VERSION ""

NS_ :

BS_:

BU_: OLDC EWP2 iBAU PSB EWP ESC EVP2 Dummy EVP1 SCU AAF eCALL H_U AEB IBOX LCA MCU SPAS CGW OBC TMU EPB SMK BCF MDPS CPD vDCM ACU vBDM AAF_2 CCM AAF_3 CLU ICSC LVR LDC CDM VCMS FCA IBU SCC PLC VCRM TCU EMS TPMS BMS NEMS LDW_LKA AAF_Tester DATC eCall VESS VCU ODS

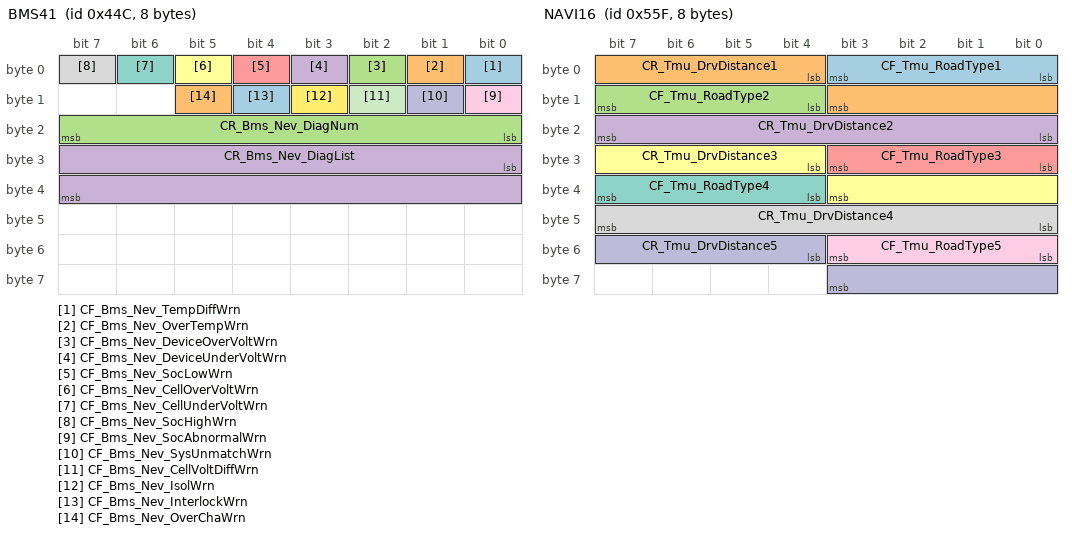
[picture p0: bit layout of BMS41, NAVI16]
BO_ 1100 BMS41: 8 BMS
 SG_ CF_Bms_Nev_TempDiffWrn : 0|1@1+ (1,0) [0|0] ""  CGW,NEMS
 SG_ CF_Bms_Nev_OverTempWrn : 1|1@1+ (1,0) [0|0] ""  CGW,NEMS
 SG_ CF_Bms_Nev_DeviceOverVoltWrn : 2|1@1+ (1,0) [0|0] ""  CGW,NEMS
 SG_ CF_Bms_Nev_DeviceUnderVoltWrn : 3|1@1+ (1,0) [0|0] ""  CGW,NEMS
 SG_ CF_Bms_Nev_SocLowWrn : 4|1@1+ (1,0) [0|0] ""  CGW,NEMS
 SG_ CF_Bms_Nev_CellOverVoltWrn : 5|1@1+ (1,0) [0|0] ""  CGW,NEMS
 SG_ CF_Bms_Nev_CellUnderVoltWrn : 6|1@1+ (1,0) [0|0] ""  CGW,NEMS
 SG_ CF_Bms_Nev_SocHighWrn : 7|1@1+ (1,0) [0|0] ""  CGW,NEMS
 SG_ CF_Bms_Nev_SocAbnormalWrn : 8|1@1+ (1,0) [0|0] ""  CGW,NEMS
 SG_ CF_Bms_Nev_SysUnmatchWrn : 9|1@1+ (1,0) [0|0] ""  CGW,NEMS
 SG_ CF_Bms_Nev_CellVoltDiffWrn : 10|1@1+ (1,0) [0|0] ""  CGW,NEMS
 SG_ CF_Bms_Nev_IsolWrn : 11|1@1+ (1,0) [0|0] ""  CGW,NEMS
 SG_ CF_Bms_Nev_InterlockWrn : 12|1@1+ (1,0) [0|0] ""  CGW,NEMS
 SG_ CF_Bms_Nev_OverChaWrn : 13|1@1+ (1,0) [0|0] ""  CGW,NEMS
 SG_ CR_Bms_Nev_DiagNum : 16|8@1+ (1,0) [0|0] ""  CGW,NEMS
 SG_ CR_Bms_Nev_DiagList : 24|16@1+ (1,0) [0|0] ""  CGW,NEMS

BO_ 1375 NAVI16: 8 CGW
 SG_ CF_Tmu_RoadType1 : 0|4@1+ (1,0) [0|15] ""  VCU
 SG_ CR_Tmu_DrvDistance1 : 4|8@1+ (1,0) [0|255] "km"  VCU
 SG_ CF_Tmu_RoadType2 : 12|4@1+ (1,0) [0|15] ""  VCU
 SG_ CR_Tmu_DrvDistance2 : 16|8@1+ (1,0) [0|255] "km"  VCU
 SG_ CF_Tmu_RoadType3 : 24|4@1+ (1,0) [0|15] ""  VCU
 SG_ CR_Tmu_DrvDistance3 : 28|8@1+ (1,0) [0|255] "km"  VCU
 SG_ CF_Tmu_RoadType4 : 36|4@1+ (1,0) [0|15] ""  VCU
 SG_ CR_Tmu_DrvDistance4 : 40|8@1+ (1,0) [0|255] "km"  VCU
 SG_ CF_Tmu_RoadType5 : 48|4@1+ (1,0) [0|15] ""  VCU
 SG_ CR_Tmu_DrvDistance5 : 52|8@1+ (1,0) [0|255] "km"  VCU

BO_ 820 MCB11: 8 iBAU
 SG_ MCB_CtlSta : 0|1@1+ (1,0) [0|1] ""  ACU,vBDM
 SG_ MCB_DefSta : 1|1@1+ (1,0) [0|1] ""  ACU,vBDM

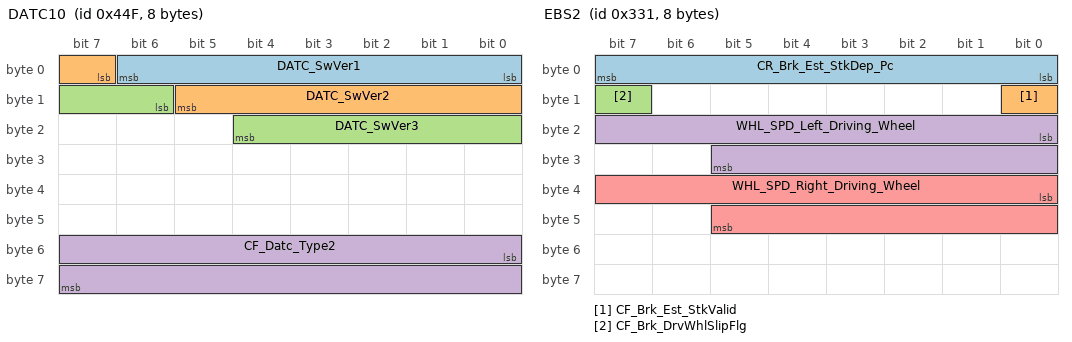
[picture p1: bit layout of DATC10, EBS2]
BO_ 1103 DATC10: 8 DATC
 SG_ DATC_SwVer1 : 0|7@1+ (1,0) [0|127] ""  CGW
 SG_ DATC_SwVer2 : 7|7@1+ (1,0) [0|127] ""  CGW
 SG_ DATC_SwVer3 : 14|7@1+ (1,0) [0|127] ""  CGW
 SG_ CF_Datc_Type2 : 48|16@1+ (1,0) [0|0] ""  CGW

BO_ 817 EBS2: 8 iBAU
 SG_ CR_Brk_Est_StkDep_Pc : 0|8@1+ (0.390625,0) [0|99.609375] "%"  Dummy
 SG_ CF_Brk_Est_StkValid : 8|1@1+ (1,0) [0|1] ""  Dummy
 SG_ CF_Brk_DrvWhlSlipFlg : 15|1@1+ (1,0) [0|1] ""  VCU
 SG_ WHL_SPD_Left_Driving_Wheel : 16|14@1+ (0.03125,0) [0|511.9375] "Km/h"  MCU,VCU
 SG_ WHL_SPD_Right_Driving_Wheel : 32|14@1+ (0.03125,0) [0|511.9375] "Km/h"  MCU,VCU

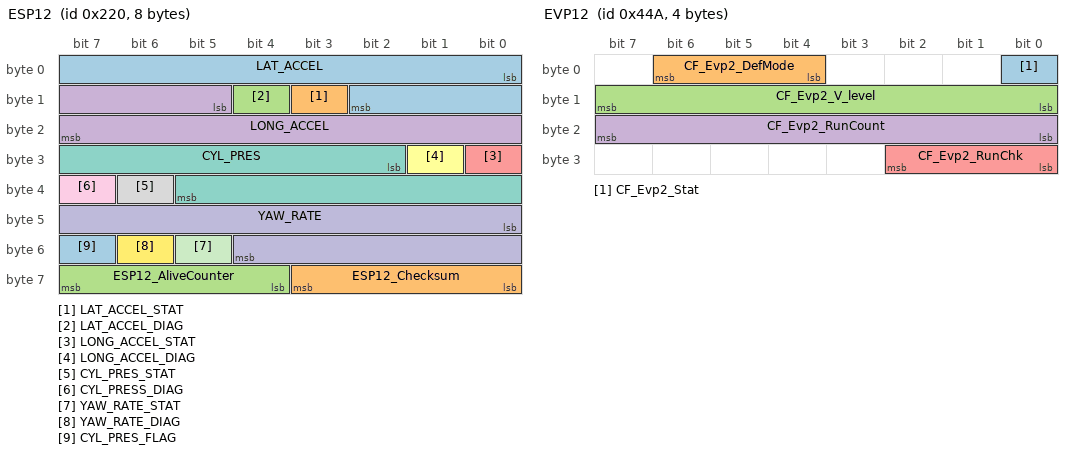
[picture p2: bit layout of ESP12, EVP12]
BO_ 544 ESP12: 8 iBAU
 SG_ LAT_ACCEL : 0|11@1+ (0.01,-10.23) [-10.23|10.24] "m/s^2"  CGW,MCU,VCU,vBDM
 SG_ LAT_ACCEL_STAT : 11|1@1+ (1,0) [0|1] ""  MCU,VCU
 SG_ LAT_ACCEL_DIAG : 12|1@1+ (1,0) [0|1] ""  ACU,MCU,VCU
 SG_ LONG_ACCEL : 13|11@1+ (0.01,-10.23) [-10.23|10.24] "m/s^2"  MCU,VCU
 SG_ LONG_ACCEL_STAT : 24|1@1+ (1,0) [0|1] ""  MCU,VCU
 SG_ LONG_ACCEL_DIAG : 25|1@1+ (1,0) [0|1] ""  ACU,MCU,VCU
 SG_ CYL_PRES : 26|12@1+ (0.1,0) [0|409.5] "Bar"  ACU,Dummy,EVP1,EVP2
 SG_ CYL_PRES_STAT : 38|1@1+ (1,0) [0|1] ""  CGW,Dummy,IBU
 SG_ CYL_PRESS_DIAG : 39|1@1+ (1,0) [0|1] ""  Dummy
 SG_ YAW_RATE : 40|13@1+ (0.01,-40.95) [-40.95|40.96] "¢ª/s"  Dummy
 SG_ YAW_RATE_STAT : 53|1@1+ (1,0) [0|1] ""  Dummy
 SG_ YAW_RATE_DIAG : 54|1@1+ (1,0) [0|1] ""  ACU,Dummy
 SG_ CYL_PRES_FLAG : 55|1@1+ (1,0) [0|1] ""  CGW,IBU
 SG_ ESP12_Checksum : 56|4@1+ (1,0) [0|15] ""  Dummy
 SG_ ESP12_AliveCounter : 60|4@1+ (1,0) [0|15] ""  Dummy,TMU

BO_ 819 VCU30: 8 VCU
 SG_ CR_Vcu_WhlRgnTqMax_Nm : 0|16@1+ (1,0) [0|65535] "Nm"  Dummy,iBAU

BO_ 1098 EVP12: 4 EVP2
 SG_ CF_Evp2_Stat : 0|1@1+ (1,0) [0|1] ""  CGW,EVP1,iBAU
 SG_ CF_Evp2_DefMode : 4|3@1+ (1,0) [0|7] ""  EVP1
 SG_ CF_Evp2_V_level : 8|8@1+ (10,0) [0|760] "mmHg"  EVP1
 SG_ CF_Evp2_RunCount : 16|8@1+ (100,0) [0|255] "ms"  EVP1
 SG_ CF_Evp2_RunChk : 24|3@1+ (1,0) [0|7] ""  EVP1,iBAU

BO_ 1369 CGW4: 8 CGW
 SG_ CF_Gway_MemoryP1Cmd : 0|1@1+ (1,0) [0|1] ""  Dummy
 SG_ CF_Gway_MemoryP2Cmd : 1|1@1+ (1,0) [0|1] ""  Dummy
 SG_ CF_Gway_PBackP1Cmd : 2|1@1+ (1,0) [0|1] ""  Dummy
 SG_ CF_Gway_PBackP2Cmd : 3|1@1+ (1,0) [0|1] ""  Dummy
 SG_ CF_Gway_StrgWhlHeatedState : 4|1@1+ (1,0) [0|1] ""  Dummy
 SG_ CF_Gway_PBackStopCmd : 5|1@1+ (1,0) [0|1] ""  Dummy
 SG_ CF_Gway_StaticBendLhAct : 6|1@1+ (1,0) [0|1] ""  Dummy
 SG_ CF_Gway_StaticBendRhAct : 7|1@1+ (1,0) [0|1] ""  Dummy
 SG_ CF_Gway_DrvWdwStat : 8|1@1+ (1,0) [0|1] ""  Dummy
 SG_ CF_Gway_RLWdwState : 9|1@1+ (1,0) [0|1] ""  Dummy
 SG_ CF_Gway_RRWdwState : 10|1@1+ (1,0) [0|1] ""  Dummy
 SG_ CF_Gway_AstWdwStat : 11|1@1+ (1,0) [0|1] ""  Dummy
 SG_ CF_Gway_MemoryEnable : 12|1@1+ (1,0) [0|1] ""  Dummy
 SG_ CF_Gway_DrvUnlockState : 14|1@1+ (1,0) [0|1] ""  Dummy
 SG_ CF_Gway_IMSBuzzer : 15|1@1+ (1,0) [0|1] ""  Dummy
 SG_ C_HSWSSysStat : 16|2@1+ (1,0) [0|3] ""  Dummy
 SG_ CF_Gway_WiperSwState : 18|2@1+ (1,0) [0|3] ""  Dummy
 SG_ CF_Gway_HCIMSPBackCmd : 20|12@1+ (1,0) [0|4095] ""  Dummy
 SG_ CF_Gway_DrvSeatBeltIND : 36|2@1+ (1,0) [0|3] ""  Dummy
 SG_ CF_Gway_AstSeatBeltIND : 38|2@1+ (1,0) [0|3] ""  Dummy
 SG_ CF_Gway_RCSeatBeltIND : 40|2@1+ (1,0) [0|3] ""  Dummy
 SG_ CF_Gway_RLSeatBeltIND : 42|2@1+ (1,0) [0|3] ""  Dummy
 SG_ CF_Gway_RRSeatBeltIND : 44|2@1+ (1,0) [0|3] ""  Dummy
 SG_ CF_Gway_RrWiperHighSw : 46|1@1+ (1,0) [0|1] ""  Dummy
 SG_ CF_Gway_RrWiperLowSw : 47|1@1+ (1,0) [0|1] ""  Dummy
 SG_ CF_Gway_Navigation_On_Off : 48|2@1+ (1,0) [0|3] ""  Dummy
 SG_ CF_Gway_LanguageInfo : 50|5@1+ (1,0) [0|31] ""  Dummy
 SG_ CF_Gway_Navi_On_Off : 55|1@1+ (1,0) [0|1] ""  Dummy
 SG_ CF_Gway_WPCWarning : 56|3@1+ (1,0) [0|7] ""  Dummy
 SG_ CF_Gway_RWPCWarning : 59|3@1+ (1,0) [0|7] ""  Dummy
 SG_ CF_Gway_DedicatedDRLState : 62|1@1+ (1,0) [0|1] ""  Dummy
 SG_ CF_Gway_SeatBeltWngBuz : 63|1@1+ (1,0) [0|1] ""  Dummy

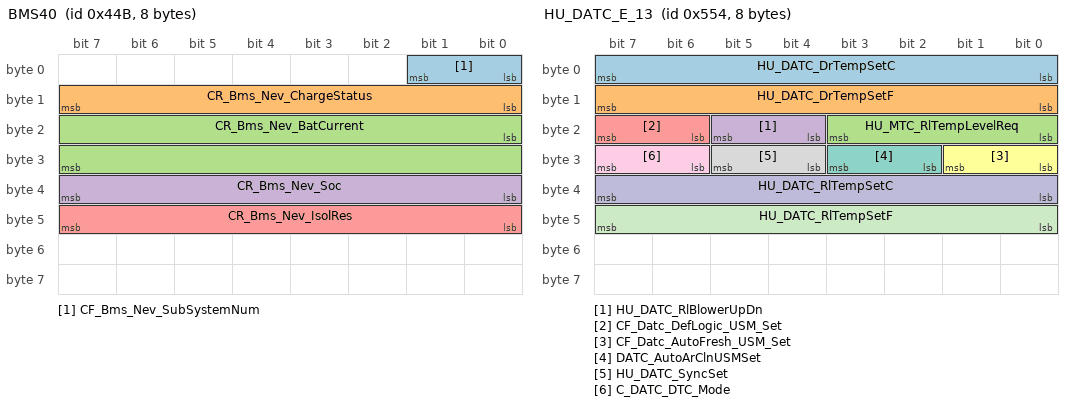
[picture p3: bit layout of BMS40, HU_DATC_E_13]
BO_ 1099 BMS40: 8 BMS
 SG_ CF_Bms_Nev_SubSystemNum : 0|2@1+ (1,0) [0|0] ""  CGW,NEMS
 SG_ CR_Bms_Nev_ChargeStatus : 8|8@1+ (1,0) [0|0] ""  CGW,NEMS
 SG_ CR_Bms_Nev_BatCurrent : 16|16@1- (0.1,0) [0|0] "A"  CGW,NEMS
 SG_ CR_Bms_Nev_Soc : 32|8@1+ (0.5,0) [0|0] "%"  CGW,NEMS
 SG_ CR_Bms_Nev_IsolRes : 40|8@1+ (5,0) [0|0] "k¥Ø"  CGW,NEMS

BO_ 1364 HU_DATC_E_13: 8 CGW
 SG_ HU_DATC_DrTempSetC : 0|8@1+ (0.5,14) [15|32] "¡É"  DATC
 SG_ HU_DATC_DrTempSetF : 8|8@1+ (1,56) [58|90] "¢µ"  DATC
 SG_ HU_MTC_RlTempLevelReq : 16|4@1+ (1,0) [0|0] ""  DATC
 SG_ HU_DATC_RlBlowerUpDn : 20|2@1+ (1,0) [0|0] ""  DATC
 SG_ CF_Datc_DefLogic_USM_Set : 22|2@1+ (1,0) [0|0] ""  DATC
 SG_ CF_Datc_AutoFresh_USM_Set : 24|2@1+ (1,0) [0|0] ""  DATC
 SG_ DATC_AutoArClnUSMSet : 26|2@1+ (1,0) [0|0] ""  DATC
 SG_ HU_DATC_SyncSet : 28|2@1+ (1,0) [0|0] ""  DATC
 SG_ C_DATC_DTC_Mode : 30|2@1+ (1,0) [0|0] ""  DATC
 SG_ HU_DATC_RlTempSetC : 32|8@1+ (0.5,14) [15|32] ""  DATC
 SG_ HU_DATC_RlTempSetF : 40|8@1+ (1,56) [58|90] ""  DATC

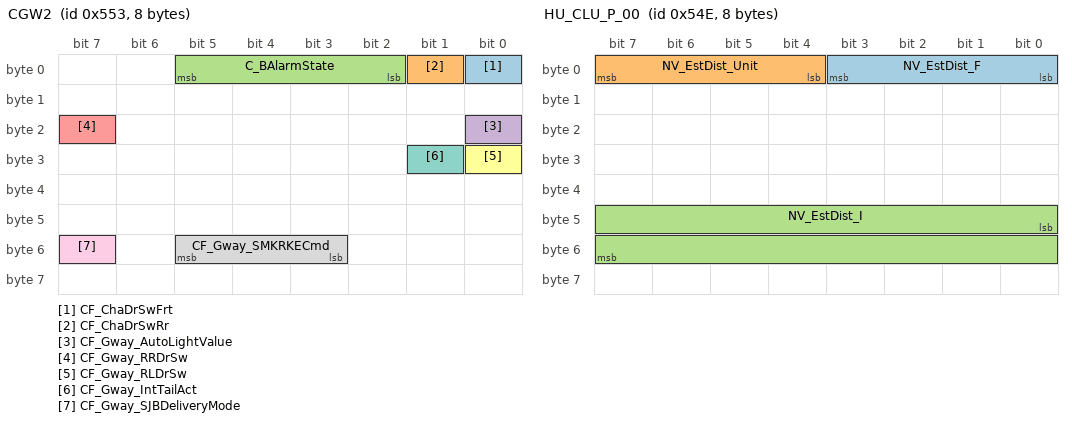
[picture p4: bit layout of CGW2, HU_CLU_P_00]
BO_ 1363 CGW2: 8 CGW
 SG_ CF_ChaDrSwFrt : 0|1@1+ (1,0) [0|0] ""  CDM,VCU
 SG_ CF_ChaDrSwRr : 1|1@1+ (1,0) [0|0] ""  CDM,VCU
 SG_ C_BAlarmState : 2|4@1+ (1,0) [0|0] ""  TMU,VCU
 SG_ CF_Gway_AutoLightValue : 16|1@1+ (1,0) [0|0] ""  DATC
 SG_ CF_Gway_RRDrSw : 23|1@1+ (1,0) [0|1] ""  BMS,vBDM
 SG_ CF_Gway_RLDrSw : 24|1@1+ (1,0) [0|1] ""  BMS
 SG_ CF_Gway_IntTailAct : 25|1@1+ (1,0) [0|1] ""  CLU,LVR,VESS
 SG_ CF_Gway_SMKRKECmd : 51|3@1+ (1,0) [0|7] ""  LVR
 SG_ CF_Gway_SJBDeliveryMode : 55|1@1+ (1,0) [0|1] ""  H_U,LDC,TMU

BO_ 1358 HU_CLU_P_00: 8 CGW
 SG_ NV_EstDist_F : 0|4@1+ (1,0) [0|15] ""  VCU
 SG_ NV_EstDist_Unit : 4|4@1+ (1,0) [0|15] ""  VCU
 SG_ NV_EstDist_I : 40|16@1+ (1,0) [0|65535] ""  VCU

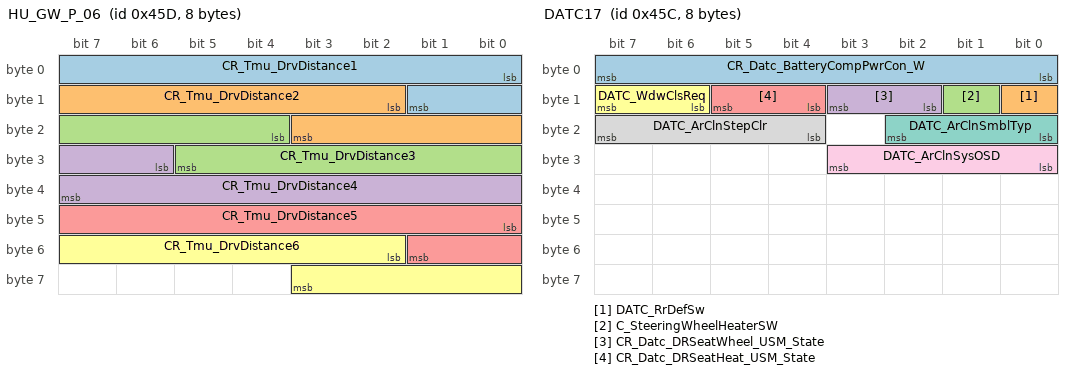
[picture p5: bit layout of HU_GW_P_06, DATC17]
BO_ 1117 HU_GW_P_06: 8 CGW
 SG_ CR_Tmu_DrvDistance1 : 0|10@1+ (1,0) [0|1022] "km"  VCU
 SG_ CR_Tmu_DrvDistance2 : 10|10@1+ (1,0) [0|1022] "km"  VCU
 SG_ CR_Tmu_DrvDistance3 : 20|10@1+ (1,0) [0|1022] "km"  VCU
 SG_ CR_Tmu_DrvDistance4 : 30|10@1+ (1,0) [0|1022] "km"  VCU
 SG_ CR_Tmu_DrvDistance5 : 40|10@1+ (1,0) [0|1022] "km"  VCU
 SG_ CR_Tmu_DrvDistance6 : 50|10@1+ (1,0) [0|1022] "km"  VCU

BO_ 1116 DATC17: 8 DATC
 SG_ CR_Datc_BatteryCompPwrCon_W : 0|8@1+ (40,0) [0|8000] "W"  CGW,TMU,VCU
 SG_ DATC_RrDefSw : 8|1@1+ (1,0) [0|1] ""  CGW
 SG_ C_SteeringWheelHeaterSW : 9|1@1+ (1,0) [0|1] ""  CGW,IBU
 SG_ CR_Datc_DRSeatWheel_USM_State : 10|2@1+ (1,0) [0|3] ""  CGW
 SG_ CR_Datc_DRSeatHeat_USM_State : 12|2@1+ (1,0) [0|3] ""  CGW
 SG_ DATC_WdwClsReq : 14|2@1+ (1,0) [0|3] ""  CGW,IBU
 SG_ DATC_ArClnSmblTyp : 16|3@1+ (1,0) [0|0] ""  CGW
 SG_ DATC_ArClnStepClr : 20|4@1+ (1,0) [0|0] ""  CGW
 SG_ DATC_ArClnSysOSD : 24|4@1+ (1,0) [0|0] ""  CGW

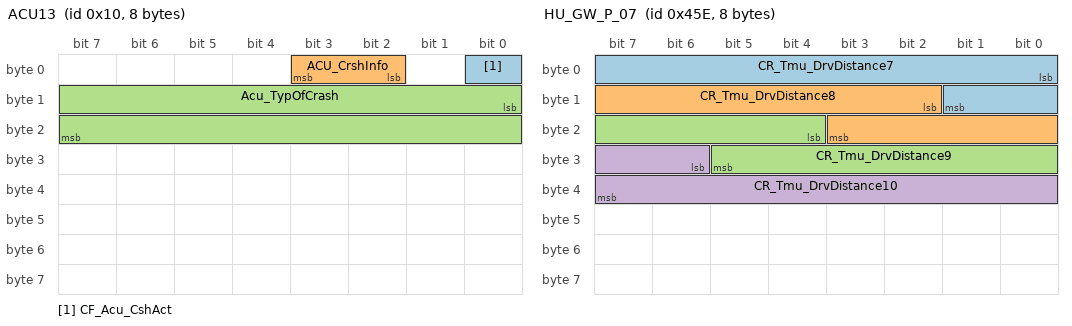
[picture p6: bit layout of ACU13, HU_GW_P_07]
BO_ 16 ACU13: 8 ACU
 SG_ CF_Acu_CshAct : 0|1@1+ (1,0) [0|1] ""  BMS,CGW,DATC,H_U,LDC,MCU,ODS,TMU,eCall
 SG_ ACU_CrshInfo : 2|2@1+ (1,0) [0|2] ""  ESC,iBAU
 SG_ Acu_TypOfCrash : 8|16@1+ (1,0) [0|0] ""  iBAU,vBDM

BO_ 1359 HU_DATC_E_12: 8 CGW
 SG_ HU_DATC_DrTempUpDn : 0|2@1+ (1,0) [0|0] ""  DATC
 SG_ HU_DATC_PsTempUpDn : 2|2@1+ (1,0) [0|0] ""  DATC
 SG_ HU_DATC_RLTempUpDn : 4|2@1+ (1,0) [0|3] ""  DATC
 SG_ HU_DATC_RrTempUpDn : 6|2@1+ (1,0) [0|0] ""  DATC
 SG_ HU_DATC_MainBlower : 8|4@1+ (1,0) [0|0] ""  DATC
 SG_ HU_DATC_RearBlower : 16|4@1+ (1,0) [0|15] ""  DATC
 SG_ HU_DATCRearPsModeSet : 20|4@1+ (1,0) [0|15] ""  DATC
 SG_ HU_DATC_FrontModeSet : 24|4@1+ (1,0) [0|0] ""  DATC
 SG_ HU_DATC_RearModeSet : 28|4@1+ (1,0) [0|15] ""  DATC
 SG_ HU_DATC_AutoSet : 32|2@1+ (1,0) [0|0] ""  DATC
 SG_ HU_DATC_OffReq : 34|2@1+ (1,0) [0|0] ""  DATC
 SG_ HU_DATC_IntakeSet : 36|2@1+ (1,0) [0|0] ""  DATC
 SG_ HU_DATC_RearOnOffSet : 38|2@1+ (1,0) [0|3] ""  DATC
 SG_ HU_DATC_AcSet : 40|2@1+ (1,0) [0|0] ""  DATC
 SG_ HU_DATC_FrontDefog : 44|2@1+ (1,0) [0|0] ""  DATC
 SG_ HU_DATC_RearDefog : 46|2@1+ (1,0) [0|0] ""  DATC
 SG_ HU_DATC_CO2Set : 50|2@1+ (1,0) [0|3] ""  DATC
 SG_ DATC_SmartVentOnOffSet : 52|2@1+ (1,0) [0|3] ""  DATC
 SG_ DATC_ADSOnOffSet : 54|2@1+ (1,0) [0|3] ""  DATC
 SG_ HU_Datc_RearAutoDisp : 56|2@1+ (1,0) [0|3] ""  DATC
 SG_ HU_Datc_RearOffDisp : 58|2@1+ (1,0) [0|3] ""  DATC
 SG_ HU_DATC_MainBlowerUpDn : 60|2@1+ (1,0) [0|0] ""  DATC
 SG_ HU_DATC_AirCleaningSet : 62|2@1+ (1,0) [0|0] ""  DATC

BO_ 1118 HU_GW_P_07: 8 CGW
 SG_ CR_Tmu_DrvDistance7 : 0|10@1+ (1,0) [0|1022] "km"  VCU
 SG_ CR_Tmu_DrvDistance8 : 10|10@1+ (1,0) [0|1022] "km"  VCU
 SG_ CR_Tmu_DrvDistance9 : 20|10@1+ (1,0) [0|1022] "km"  VCU
 SG_ CR_Tmu_DrvDistance10 : 30|10@1+ (1,0) [0|1022] "km"  VCU

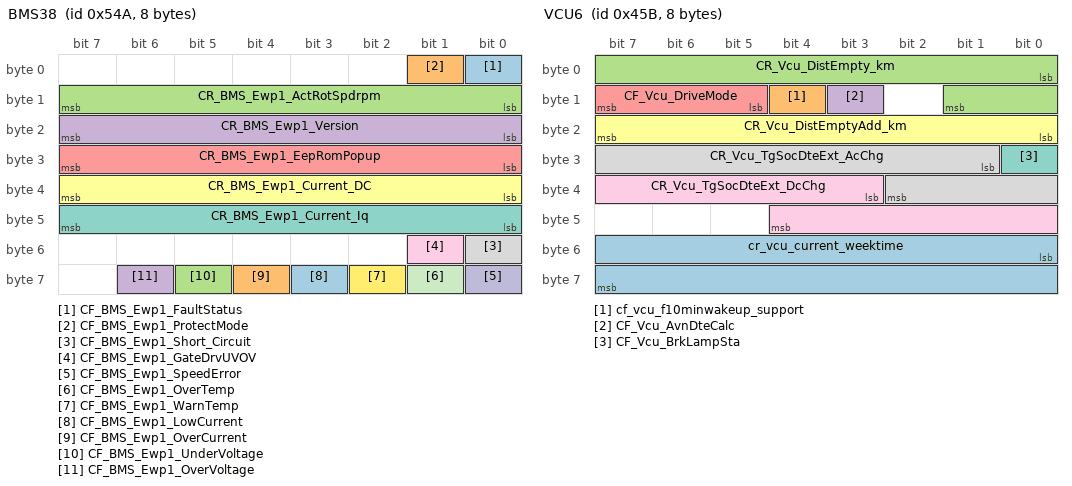
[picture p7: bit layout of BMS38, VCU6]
BO_ 1354 BMS38: 8 BMS
 SG_ CF_BMS_Ewp1_FaultStatus : 0|1@1+ (1,0) [0|1] "flag"  Dummy
 SG_ CF_BMS_Ewp1_ProtectMode : 1|1@1+ (1,0) [0|1] "flag"  Dummy
 SG_ CR_BMS_Ewp1_ActRotSpdrpm : 8|8@1+ (20,0) [0|5000] "rpm"  Dummy
 SG_ CR_BMS_Ewp1_Version : 16|8@1+ (1,0) [0|255] ""  CGW,Dummy,vBDM
 SG_ CR_BMS_Ewp1_EepRomPopup : 24|8@1+ (1,0) [0|255] ""  Dummy
 SG_ CR_BMS_Ewp1_Current_DC : 32|8@1+ (0.1,0) [0|25.5] "A"  Dummy
 SG_ CR_BMS_Ewp1_Current_Iq : 40|8@1+ (0.1,0) [0|25.5] "A"  Dummy
 SG_ CF_BMS_Ewp1_Short_Circuit : 48|1@1+ (1,0) [0|1] ""  Dummy
 SG_ CF_BMS_Ewp1_GateDrvUVOV : 49|1@1+ (1,0) [0|1] "flag"  Dummy
 SG_ CF_BMS_Ewp1_SpeedError : 56|1@1+ (1,0) [0|1] "flag"  Dummy
 SG_ CF_BMS_Ewp1_OverTemp : 57|1@1+ (1,0) [0|1] "flag"  Dummy
 SG_ CF_BMS_Ewp1_WarnTemp : 58|1@1+ (1,0) [0|1] "flag"  Dummy
 SG_ CF_BMS_Ewp1_LowCurrent : 59|1@1+ (1,0) [0|1] "flag"  Dummy
 SG_ CF_BMS_Ewp1_OverCurrent : 60|1@1+ (1,0) [0|1] "flag"  Dummy
 SG_ CF_BMS_Ewp1_UnderVoltage : 61|1@1+ (1,0) [0|1] "flag"  Dummy
 SG_ CF_BMS_Ewp1_OverVoltage : 62|1@1+ (1,0) [0|1] "flag"  Dummy

BO_ 1115 VCU6: 8 VCU
 SG_ cr_vcu_current_weektime : 48|16@1+ (1,0) [0|65535] "" Vector__XXX
 SG_ cf_vcu_f10minwakeup_support : 12|1@1+ (1,0) [0|1] "" Vector__XXX
 SG_ CR_Vcu_DistEmpty_km : 0|10@1+ (1,0) [0|1023] "km"  CGW,H_U,TMU
 SG_ CF_Vcu_AvnDteCalc : 11|1@1+ (1,0) [0|1] "flag"  CGW
 SG_ CF_Vcu_DriveMode : 13|3@1+ (1,0) [0|7] ""  CGW,DATC,MCU,iBAU
 SG_ CR_Vcu_DistEmptyAdd_km : 16|8@1+ (1,0) [0|255] "km"  CGW,TMU
 SG_ CF_Vcu_BrkLampSta : 24|1@1+ (1,0) [0|1] ""  EVP1,EVP2
 SG_ CR_Vcu_TgSocDteExt_AcChg : 25|10@1+ (1,0) [0|1023] ""  CGW
 SG_ CR_Vcu_TgSocDteExt_DcChg : 35|10@1+ (1,0) [0|1023] ""  CGW

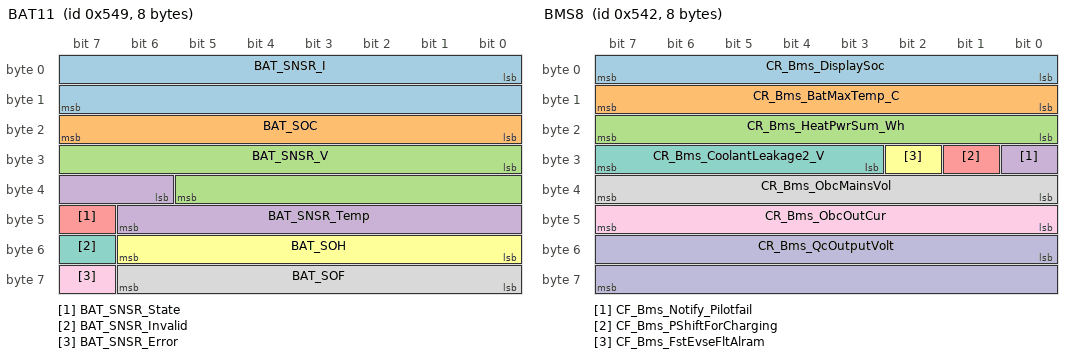
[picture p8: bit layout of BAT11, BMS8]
BO_ 1353 BAT11: 8 LDC
 SG_ BAT_SNSR_I : 0|16@1+ (0.01,-327) [-327|327] "A"  CGW,MCU
 SG_ BAT_SOC : 16|8@1+ (1,0) [0|100] "%"  CGW,H_U,MCU,TMU
 SG_ BAT_SNSR_V : 24|14@1+ (0.001,6) [6|18] "V"  MCU
 SG_ BAT_SNSR_Temp : 38|9@1- (0.5,-40) [-40|87] "¡É"  MCU
 SG_ BAT_SNSR_State : 47|1@1+ (1,0) [0|1] ""  CGW,H_U,MCU,TMU
 SG_ BAT_SOH : 48|7@1+ (1,0) [0|100] "%"  CGW,MCU
 SG_ BAT_SNSR_Invalid : 55|1@1+ (1,0) [0|1] ""  MCU
 SG_ BAT_SOF : 56|7@1+ (0.1,0) [0|12] "V"  MCU
 SG_ BAT_SNSR_Error : 63|1@1+ (1,0) [0|1] ""  MCU

BO_ 265 VCU32: 8 VCU
 SG_ CR_Vcu_EwpRpmReqToMcu : 0|8@1+ (20,0) [0|5000] "rpm"  MCU
 SG_ CF_Vcu_WakeupReq : 8|1@1+ (1,0) [0|1] ""  SCU
 SG_ CF_Vcu_HvIntlock_Req : 9|1@1+ (1,0) [0|1] "flag"  BMS,DATC,OBC,VCU
 SG_ CF_Vcu_BmsEwpOpReq : 10|1@1+ (1,0) [0|1] "flag"  BMS
 SG_ CR_Vcu_TQI_Max : 16|8@1+ (0.3906,0) [0|99.61] "%"  iBAU
 SG_ CR_Vcu_SchedChgSt_Day : 24|3@1+ (1,0) [0|6] ""  CGW
 SG_ CR_Vcu_SchedChgSt_Hr : 27|5@1+ (1,0) [0|23] "Hour"  CGW
 SG_ CR_Vcu_SchedChgSt_Min : 32|6@1+ (1,0) [0|59] "Min"  CGW
 SG_ CR_Vcu_SchedChgEnd_Day : 38|3@1+ (1,0) [0|6] ""  CGW
 SG_ CR_Vcu_SchedChgEnd_Hr : 41|5@1+ (1,0) [0|23] "Hour"  CGW
 SG_ CR_Vcu_SchedChgEnd_Min : 46|6@1+ (1,0) [0|59] "Min"  CGW
 SG_ CF_Vcu_3WayValInhibitToMcu : 52|1@1+ (1,0) [0|1] ""  MCU
 SG_ CF_Vcu_EwpForcedOperToMcu : 53|1@1+ (1,0) [0|1] "flag"  MCU
 SG_ CF_Vcu_EwpCoolantDiagEnbToMcu : 54|1@1+ (1,0) [0|1] "flag"  MCU
 SG_ CF_Vcu_EwpCoolantDispToMcu : 55|1@1+ (1,0) [0|1] "flag"  MCU
 SG_ CF_Vcu_CAN_CHECKSUM : 56|4@1+ (1,0) [0|15] ""  CGW,SCU,TMU,vBDM
 SG_ CF_Vcu_CAN_COUNT : 60|2@1+ (1,0) [0|3] ""  SCU
 SG_ CF_Vcu_PARKCMD : 62|2@1+ (1,0) [0|3] ""  SCU

BO_ 1346 BMS8: 8 BMS
 SG_ CR_Bms_DisplaySoc : 0|8@1+ (0.5,0) [0|100] "%"  CGW,TMU,vBDM
 SG_ CR_Bms_BatMaxTemp_C : 8|8@1- (1,0) [-128|126] "¡É"  Dummy
 SG_ CR_Bms_HeatPwrSum_Wh : 16|8@1+ (10,0) [0|2540] "Wh"  CGW,TMU
 SG_ CF_Bms_Notify_Pilotfail : 24|1@1+ (1,0) [0|1] "flag"  CGW,TMU
 SG_ CF_Bms_PShiftForCharging : 25|1@1+ (1,0) [0|1] "flag"  CGW,TMU
 SG_ CF_Bms_FstEvseFltAlram : 26|1@1+ (1,0) [0|1] "flag"  CGW,TMU
 SG_ CR_Bms_CoolantLeakage2_V : 27|5@1+ (0.2,0) [0|6.3] "V"  Dummy
 SG_ CR_Bms_ObcMainsVol : 32|8@1+ (2,0) [0|500] "V"  VCU
 SG_ CR_Bms_ObcOutCur : 40|8@1+ (0.1,0) [0|25] "A"  VCU
 SG_ CR_Bms_QcOutputVolt : 48|16@1+ (0.1,0) [0|500] "V"  MCU,VCU

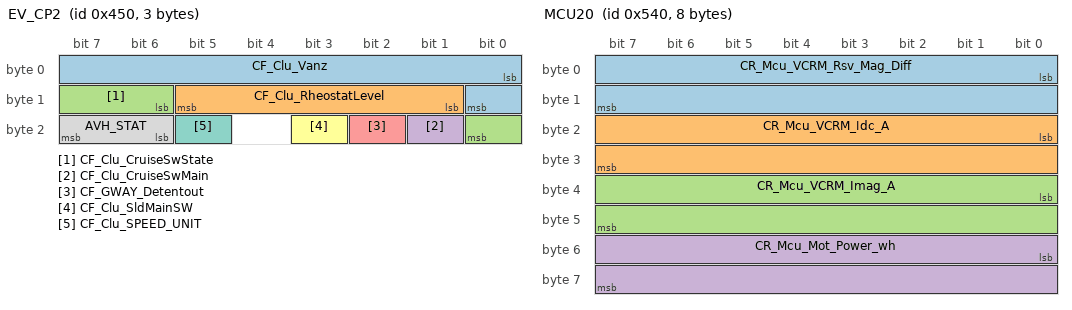
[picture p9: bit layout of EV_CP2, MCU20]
BO_ 1104 EV_CP2: 3 CGW
 SG_ CF_Clu_Vanz : 0|9@1+ (0.5,0) [0|255.5] "km/h or MPH"  DATC,H_U,NEMS,TMU,VCU,VESS,eCall
 SG_ CF_Clu_RheostatLevel : 9|5@1+ (1,0) [0|31] ""  DATC,LCA,LVR,MDPS,SPAS,VESS
 SG_ CF_Clu_CruiseSwState : 14|3@1+ (1,0) [0|7] ""  VCU
 SG_ CF_Clu_CruiseSwMain : 17|1@1+ (1,0) [0|1] ""  VCU
 SG_ CF_GWAY_Detentout : 18|1@1+ (1,0) [0|0] ""  DATC,LVR,VESS
 SG_ CF_Clu_SldMainSW : 19|1@1+ (1,0) [0|1] ""  VCU
 SG_ CF_Clu_SPEED_UNIT : 21|1@1+ (1,0) [0|1] ""  DATC,H_U,NEMS,TMU,VCU,VESS,eCall
 SG_ AVH_STAT : 22|2@1+ (1,0) [0|3] ""  VCU

BO_ 1344 MCU20: 8 MCU
 SG_ CR_Mcu_VCRM_Rsv_Mag_Diff : 0|16@1+ (0.0001,0) [0|6.5535] ""  CGW,TMU,vBDM
 SG_ CR_Mcu_VCRM_Idc_A : 16|16@1+ (0.1,-1000) [-1000|1000] "A"  CGW,NEMS
 SG_ CR_Mcu_VCRM_Imag_A : 32|16@1+ (0.01,0) [0|655.35] "A"  TMU
 SG_ CR_Mcu_Mot_Power_wh : 48|16@1+ (1,0) [0|65534] "Wh"  CGW

BO_ 1345 CGW1: 8 CGW
 SG_ CF_Gway_IGNSw : 0|3@1+ (1,0) [0|7] ""  ACU,H_U,LVR,TMU,VCU,iBAU
 SG_ CF_Gway_RKECmd : 3|3@1+ (1,0) [0|7] ""  LVR
 SG_ CF_Gway_DrvKeyLockSw : 6|1@1+ (1,0) [0|1] ""  Dummy
 SG_ CF_Gway_DrvKeyUnlockSw : 7|1@1+ (1,0) [0|1] ""  Dummy
 SG_ CF_Gway_DrvDrSw : 8|2@1+ (1,0) [0|3] ""  BMS,LVR,VCU,iBAU
 SG_ CF_Gway_DrvSeatBeltSw : 10|2@1+ (1,0) [0|3] ""  ACU,H_U,TMU,VCU,iBAU
 SG_ CF_Gway_TrunkTgSw : 12|2@1+ (1,0) [0|3] ""  BMS,iBAU
 SG_ CF_Gway_AstSeatBeltSw : 14|2@1+ (1,0) [0|3] ""  ACU,H_U,TMU
 SG_ CF_Gway_SMKOption : 16|1@1+ (1,0) [0|1] ""  Dummy
 SG_ CF_Gway_HoodSw : 17|2@1+ (1,0) [0|3] ""  iBAU
 SG_ CF_Gway_TurnSigLh : 19|2@1+ (1,0) [0|3] ""  Dummy
 SG_ CF_Gway_WiperIntT : 21|3@1+ (1,0) [0|7] ""  LDC,iBAU
 SG_ CF_Gway_WiperIntSw : 24|1@1+ (1,0) [0|1] ""  LDC,iBAU
 SG_ CF_Gway_WiperLowSw : 25|1@1+ (1,0) [0|1] ""  LDC,iBAU
 SG_ CF_Gway_WiperHighSw : 26|1@1+ (1,0) [0|1] ""  LDC,iBAU
 SG_ CF_Gway_WiperAutoSw : 27|1@1+ (1,0) [0|1] ""  iBAU
 SG_ CF_Gway_RainSnsState : 28|3@1+ (1,0) [0|7] ""  iBAU
 SG_ CF_Gway_HeadLampLow : 31|1@1+ (1,0) [0|1] ""  LDC
 SG_ CF_Gway_HeadLampHigh : 32|1@1+ (1,0) [0|1] ""  LDC
 SG_ CF_Gway_HazardSw : 33|2@1+ (1,0) [0|3] ""  H_U,TMU,iBAU,vBDM
 SG_ CF_Gway_AstDrSw : 35|1@1+ (1,0) [0|1] ""  BMS
 SG_ CF_Gway_DefoggerRly : 36|1@1+ (1,0) [0|1] ""  LDC
 SG_ CF_Gway_ALightStat : 37|1@1+ (1,0) [0|1] ""  Dummy
 SG_ CF_Gway_LightSwState : 38|2@1+ (1,0) [0|3] ""  LVR
 SG_ CF_Gway_Frt_Fog_Act : 40|1@1+ (1,0) [0|1] ""  Dummy
 SG_ CF_Gway_TSigLHSw : 41|1@1+ (1,0) [0|1] ""  Dummy
 SG_ CF_Gway_TSigRHSw : 42|1@1+ (1,0) [0|1] ""  Dummy
 SG_ CF_Gway_DriveTypeOption : 43|1@1+ (1,0) [0|1] ""  Dummy
 SG_ CF_Gway_StarterRlyState : 44|1@1+ (1,0) [0|1] ""  Dummy
 SG_ CF_Gway_PassiveAccessLock : 45|2@1+ (1,0) [0|3] ""  Dummy
 SG_ CF_Gway_RearFogAct : 47|1@1+ (1,0) [0|1] ""  LDC
 SG_ CF_Gway_PassiveAccessUnlock : 48|2@1+ (1,0) [0|3] ""  Dummy
 SG_ CF_Gway_PassingSW : 51|1@1+ (1,0) [0|1] ""  Dummy
 SG_ CF_Gway_HBAControlMode : 52|1@1+ (1,0) [0|1] ""  Dummy
 SG_ CF_Gway_HLpHighSw : 53|1@1+ (1,0) [0|1] ""  Dummy
 SG_ CF_Gway_InhibitRMT : 54|2@1+ (1,0) [0|3] ""  iBAU
 SG_ CF_Gway_Ign1 : 58|1@1+ (1,0) [0|1] ""  ACU,CDM,Dummy,VCU,iBAU
 SG_ CF_Gway_Ign2 : 59|1@1+ (1,0) [0|1] ""  ACU,Dummy,VCU
 SG_ CF_Gway_ParkBrakeSw : 60|2@1+ (1,0) [0|3] ""  TMU,VCU,iBAU
 SG_ CF_Gway_TurnSigRh : 62|2@1+ (1,0) [0|3] ""  Dummy

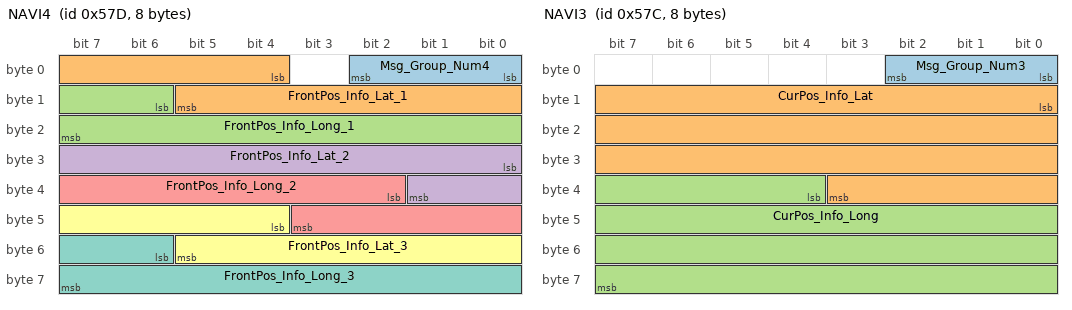
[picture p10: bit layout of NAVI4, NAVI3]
BO_ 1405 NAVI4: 8 CGW
 SG_ Msg_Group_Num4 : 0|3@1+ (1,0) [0|7] ""  VCU
 SG_ FrontPos_Info_Lat_1 : 4|10@1+ (1,-512) [-512|511] "m"  VCU
 SG_ FrontPos_Info_Long_1 : 14|10@1+ (1,-512) [-512|511] "m"  VCU
 SG_ FrontPos_Info_Lat_2 : 24|10@1+ (1,-512) [-512|511] "m"  VCU
 SG_ FrontPos_Info_Long_2 : 34|10@1+ (1,-512) [-512|511] "m"  VCU
 SG_ FrontPos_Info_Lat_3 : 44|10@1+ (1,-512) [-512|511] "m"  VCU
 SG_ FrontPos_Info_Long_3 : 54|10@1+ (1,-512) [-512|511] "m"  VCU

BO_ 1404 NAVI3: 8 CGW
 SG_ Msg_Group_Num3 : 0|3@1+ (1,0) [0|7] ""  VCU
 SG_ CurPos_Info_Lat : 8|28@1+ (1,-134217727) [-134217727|0] "Sec"  VCU
 SG_ CurPos_Info_Long : 36|28@1+ (1,-134217727) [-134217727|0] "Sec"  VCU

BO_ 1407 OBC1: 8 OBC
 SG_ CF_OBC_CONTRAB : 0|1@1+ (1,0) [0|1] ""  BMS,TMU
 SG_ CF_OBC_PD_Stat : 1|2@1+ (1,0) [0|3] ""  BMS,CCM,CGW,H_U,SMK,TMU
 SG_ CF_OBC_Chg_Finished : 3|1@1+ (1,0) [0|1] ""  BMS,CCM,TMU
 SG_ CF_OBC_EVSE_RDY_STATE : 4|1@1+ (1,0) [0|1] ""  BMS,CDM,CGW,H_U,TMU,VCU
 SG_ CF_OBC_WRN : 5|1@1+ (1,0) [0|1] ""  BMS,TMU
 SG_ CF_OBC_FLT : 6|1@1+ (1,0) [0|1] ""  BMS,CGW,H_U,TMU,VCU
 SG_ CF_OBC_RDY : 7|1@1+ (1,0) [0|1] ""  BMS,CGW,TMU,VCU
 SG_ CF_OBC_AC_DETECT_FLAG : 8|1@1+ (1,0) [0|1] ""  BMS,CDM,DATC,TMU
 SG_ CR_OBC_CP_Volt : 9|7@1+ (0.1,0) [0|12.7] "V"  BMS,TMU,VCU
 SG_ CR_OBC_TEMP : 16|8@1+ (1,-100) [-100|155] "¡É"  AAF,MCU,TMU,VCU
 SG_ CR_OBC_RadFanReq_Duty : 24|8@1+ (1,0) [0|255] "%"  MCU,TMU,VCU
 SG_ CF_OBC_IG3_DRV_STATE : 32|1@1+ (1,0) [0|1] ""  BMS,CDM,TMU,VCU
 SG_ CF_OBC_AC_CONNECT : 33|1@1+ (1,0) [0|1] ""  BMS,CCM,CDM,CGW,IBU,SMK,TMU,VCU
 SG_ CF_OBC_S2_SW_ON_FLAG : 34|1@1+ (1,0) [0|1] ""  BMS,CCM,TMU
 SG_ CF_OBC_MainRlyOn_Req : 35|1@1+ (1,0) [0|1] ""  BMS,TMU
 SG_ CF_OBC_OBCRlyOn_Req : 36|1@1+ (1,0) [0|1] ""  BMS,TMU
 SG_ CF_OBC_MILReq : 37|1@1+ (1,0) [0|1] ""  CGW,H_U,TMU,VCU
 SG_ CF_OBC_VCRM_Req : 38|2@1+ (1,0) [0|2] ""  CGW,H_U,TMU,vBDM
 SG_ CF_OBC_RAD_Fan_Req : 40|2@1+ (1,0) [0|2] ""  MCU,TMU,VCU
 SG_ CF_OBC_SERVICE_LAMP_Req : 42|1@1+ (1,0) [0|1] ""  CGW,H_U,TMU
 SG_ CF_OBC_HvIntlockReq : 43|1@1+ (1,0) [0|1] ""  BMS,DATC,LDC,MCU,TMU
 SG_ CF_EVSE_FAULT_FLAG : 44|1@1+ (1,0) [0|1] ""  CCM,CGW,TMU
 SG_ CF_OBC_DCChargingStat : 45|1@1+ (1,0) [0|1] ""  BMS,CCM,CDM,CGW,H_U,TMU
 SG_ CF_OBC_ACChargingStat : 46|1@1+ (1,0) [0|1] ""  CDM,CGW,H_U,TMU,VCU
 SG_ CF_OBC_ImmeChgSwState : 47|1@1+ (1,0) [0|1] ""  VCU
 SG_ CR_OBC_EWP_Rpm_Req : 48|8@1+ (20,0) [0|5000] "rpm"  MCU,TMU,VCU
 SG_ CR_OBC_TEMP_B : 56|8@1+ (1,-100) [-100|155] "¡É"  AAF,MCU,TMU,VCU

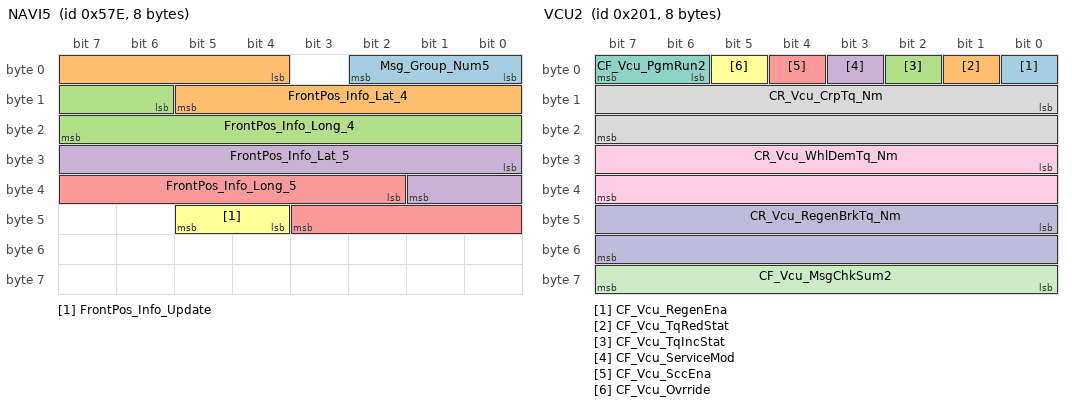
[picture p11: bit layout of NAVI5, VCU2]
BO_ 1406 NAVI5: 8 CGW
 SG_ Msg_Group_Num5 : 0|3@1+ (1,0) [0|7] ""  VCU
 SG_ FrontPos_Info_Lat_4 : 4|10@1+ (1,-512) [-512|511] "m"  VCU
 SG_ FrontPos_Info_Long_4 : 14|10@1+ (1,-512) [-512|511] "m"  VCU
 SG_ FrontPos_Info_Lat_5 : 24|10@1+ (1,-512) [-512|511] "m"  VCU
 SG_ FrontPos_Info_Long_5 : 34|10@1+ (1,-512) [-512|511] "m"  VCU
 SG_ FrontPos_Info_Update : 44|2@1+ (1,0) [0|3] ""  VCU

BO_ 1133 CTM1: 8 CGW
 SG_ CF_Ctm_TrailerAct : 0|1@1+ (1,0) [0|0] ""  Dummy,VCU
 SG_ CF_Ctm_RearfogAct : 1|1@1+ (1,0) [0|0] ""  Dummy

BO_ 1401 VCU18: 8 VCU
 SG_ CF_Vcu_SchedChgMode : 0|2@1+ (1,0) [0|3] ""  CGW,OBC,TMU,vBDM
 SG_ CR_Vcu_OffPeakTimeStHr : 2|5@1+ (1,0) [0|23] "Hour"  CGW,TMU
 SG_ CR_Vcu_OffPeakTimeStMin : 7|3@1+ (10,0) [0|50] "Min"  CGW,TMU
 SG_ CR_Vcu_OffPeakTimeEndHr : 10|5@1+ (1,0) [0|23] "Hour"  CGW,TMU
 SG_ CR_Vcu_OffPeakTimeEndMin : 15|3@1+ (10,0) [0|50] "Min"  CGW,TMU
 SG_ CF_Vcu_RestModeRValueSet : 18|2@1+ (1,0) [0|3] ""  CGW
 SG_ CF_Vcu_RestModeWarn : 20|2@1+ (1,0) [0|2] ""  CGW
 SG_ CF_Vcu_RestModeVehCond : 22|1@1+ (1,0) [0|1] ""  CGW
 SG_ CF_Vcu_EpbRequest : 23|1@1+ (1,0) [0|1] ""  CGW
 SG_ CF_Vcu_GpsSched_State : 24|2@1+ (1,0) [0|3] ""  CGW
 SG_ CF_Vcu_GpsSched_ChgAir : 26|1@1+ (1,0) [0|1] ""  CGW
 SG_ CF_Vcu_GpsSchedUpdateRq : 27|1@1+ (1,0) [0|1] ""  CGW
 SG_ CF_Vcu_MainBattType : 29|2@1+ (1,0) [0|1] ""  Dummy
 SG_ CF_Vcu_MainBattTypeLrnSts : 31|1@1+ (1,0) [0|1] ""  Dummy
 SG_ CF_Vcu_RegenLevel_Eco : 34|2@1+ (1,0) [0|3] "Level"  CGW,TMU
 SG_ CF_Vcu_RegenLevel_Normal : 36|2@1+ (1,0) [0|3] "Level"  CGW,TMU
 SG_ CF_Vcu_RegenLevel_Sport : 38|2@1+ (1,0) [0|3] "Level"  CGW,TMU
 SG_ CF_Vcu_SmartRegen_RValueSet : 40|2@1+ (1,0) [0|3] ""  CGW
 SG_ CF_Vcu_SmartRegen_Disp : 42|1@1+ (1,0) [0|1] ""  CGW
 SG_ CF_Vcu_SmartRegen_Step : 43|1@1+ (1,0) [0|1] ""  CGW
 SG_ CF_Vcu_SmartRegen_WarnMsg : 48|2@1+ (1,0) [0|3] ""  CGW
 SG_ CF_Vcu_DriveMode : 52|3@1+ (1,0) [0|7] ""  BMS,CGW,DATC,LDC,MCU
 SG_ CF_Vcu_SpdLmt : 55|1@1+ (1,0) [0|1] ""  CGW,TMU
 SG_ CR_Vcu_MaxSpd : 56|8@1+ (1,0) [0|255] "kph"  CGW,TMU

BO_ 512 VCU1: 8 VCU
 SG_ CR_Vcu_DistEmptyAdd_km : 0|8@1+ (1,0) [0|255] "km"  CGW,TMU
 SG_ CF_Vcu_ChgStat : 8|3@1+ (1,0) [0|7] ""  TMU,VESS
 SG_ CF_Vcu_GarSelDisp : 11|4@1+ (1,0) [0|15] ""  AAF,ACU,BMS,CGW,H_U,IBU,LDC,LVR,MCU,NEMS,OBC,SMK,TMU,VESS,iBAU
 SG_ CR_Vcu_DistEmpty_km : 15|10@1+ (1,0) [0|1023] "km"  CGW,H_U,TMU
 SG_ CF_Vcu_ChargeCycle : 25|1@1+ (1,0) [0|1] ""  BMS,LDC,MCU,OBC,TMU
 SG_ CF_Vcu_IGONStatus : 26|4@1+ (1,0) [0|10] ""  Dummy
 SG_ CF_Vcu_AvnDteCalc : 30|1@1+ (1,0) [0|1] "flag"  CGW
 SG_ CF_Vcu_EstApsSel : 31|1@1+ (1,0) [0|1] ""  CGW,TMU,iBAU
 SG_ CR_Vcu_AccPedDep_Pc : 32|8@1+ (0.3921568627,0) [0|100] "%"  AAF,ACU,CGW,LDC,MCU,NEMS,TMU,iBAU
 SG_ CF_Vcu_Veh_DC : 40|1@1+ (1,0) [0|1] ""  BMS,DATC,LDC,MCU,OBC,TMU
 SG_ CF_Vcu_WarmupCyc : 41|1@1+ (1,0) [0|1] ""  BMS,LDC,MCU,OBC,TMU
 SG_ CF_Vcu_Key_ST : 42|1@1+ (1,0) [0|1] ""  BMS,CGW,LDC,TMU
 SG_ CF_Vcu_EvRdyClu : 43|1@1+ (1,0) [0|1] ""  CDM,CGW,DATC,IBU,SMK,TMU
 SG_ CF_Vcu_Rdy : 44|1@1+ (1,0) [0|1] ""  BMS,CGW,LDC,LVR,MCU,OBC,TMU,eCall,iBAU,vBDM
 SG_ CF_Vcu_EvRdy : 45|1@1+ (1,0) [0|1] ""  BMS,CCM,CDM,CGW,DATC,EVP1,EVP2,H_U,IBU,LDC,LVR,MCU,OBC,SMK,TMU,VESS,iBAU
 SG_ CF_Vcu_PgmRun1 : 46|2@1+ (1,0) [0|3] ""  TMU,iBAU
 SG_ CF_Vcu_RelayOffReq : 48|1@1+ (1,0) [0|1] ""  BMS,CGW,TMU
 SG_ CR_Vcu_TqStd_Nm : 49|6@1+ (10,0) [0|630] "Nm"  CGW,MCU,TMU,iBAU
 SG_ CF_Vcu_EcoMdOff : 55|1@1+ (1,0) [0|1] ""  CGW,DATC,MCU,TMU,VESS,iBAU
 SG_ CR_Vcu_EstAccPed_PC : 56|8@1+ (0.3906,0) [0|99.61] "%"  CGW,TMU,iBAU

BO_ 513 VCU2: 8 VCU
 SG_ CF_Vcu_RegenEna : 0|1@1+ (1,0) [0|1] ""  TMU,iBAU
 SG_ CF_Vcu_TqRedStat : 1|1@1+ (1,0) [0|1] ""  TMU,iBAU
 SG_ CF_Vcu_TqIncStat : 2|1@1+ (1,0) [0|1] ""  TMU,iBAU
 SG_ CF_Vcu_ServiceMod : 3|1@1+ (1,0) [0|1] ""  CGW,MCU,TMU,iBAU
 SG_ CF_Vcu_SccEna : 4|1@1+ (1,0) [0|1] ""  CGW,TMU,iBAU
 SG_ CF_Vcu_Ovrride : 5|1@1+ (1,0) [0|1] ""  CGW,TMU,iBAU
 SG_ CF_Vcu_PgmRun2 : 6|2@1+ (1,0) [0|3] ""  TMU,iBAU
 SG_ CR_Vcu_CrpTq_Nm : 8|16@1- (1,0) [-32768|32767] "Nm"  TMU,iBAU
 SG_ CR_Vcu_WhlDemTq_Nm : 24|16@1- (1,0) [-32768|32767] "Nm"  CGW,TMU,iBAU
 SG_ CR_Vcu_RegenBrkTq_Nm : 40|16@1+ (1,0) [0|65535] "Nm"  TMU,iBAU
 SG_ CF_Vcu_MsgChkSum2 : 56|8@1+ (1,0) [0|255] ""  CGW,TMU,iBAU,vBDM

BO_ 1400 EV_CP5: 6 CGW
 SG_ CF_Clu_LowfuelWarn : 0|2@1+ (1,0) [0|3] ""  Dummy
 SG_ CF_Ahb_Def : 2|2@1+ (1,0) [0|3] ""  NEMS,TMU,VCU
 SG_ CF_LKA_SysState : 4|4@1+ (1,0) [0|15] ""  H_U,TMU,vBDM
 SG_ CF_Mdps_WLmp : 8|2@1+ (1,0) [0|3] ""  H_U,TMU
 SG_ SCCFailInfo : 11|2@1+ (1,0) [0|3] ""  H_U,TMU
 SG_ SCCMode : 13|2@1+ (1,0) [0|3] ""  H_U,TMU
 SG_ CF_Clu_ActiveEcoSW : 15|1@1+ (1,0) [0|1] ""  TMU,VCU
 SG_ POS_FL_W_LAMP : 16|1@1+ (1,0) [0|1] ""  H_U,TMU
 SG_ POS_FR_W_LAMP : 17|1@1+ (1,0) [0|1] ""  H_U,TMU
 SG_ POS_RL_W_LAMP : 18|1@1+ (1,0) [0|1] ""  H_U,TMU
 SG_ POS_RR_W_LAMP : 19|1@1+ (1,0) [0|1] ""  H_U,TMU
 SG_ TPMS_W_LAMP : 20|2@1+ (1,0) [0|3] ""  H_U,TMU
 SG_ TREAD_W_LAMP : 22|2@1+ (1,0) [0|3] ""  H_U,TMU
 SG_ CF_Clu_SmartRegen_NValueSet : 24|2@1+ (1,0) [0|3] ""  VCU
 SG_ CF_Clu_NCC_CameraNValueSet : 26|3@1+ (1,0) [0|7] ""  VCU
 SG_ CF_DAW_Warn : 30|2@1+ (1,0) [0|3] ""  H_U,TMU
 SG_ CF_Clu_DAWLastBreakTime : 32|4@1+ (1,0) [0|15] ""  H_U,TMU
 SG_ CF_Clu_RefDetMod : 42|1@1+ (1,0) [0|1] ""  VCU
 SG_ CF_Clu_DriveModeSW : 47|1@1+ (1,0) [0|1] ""  TMU,VCU

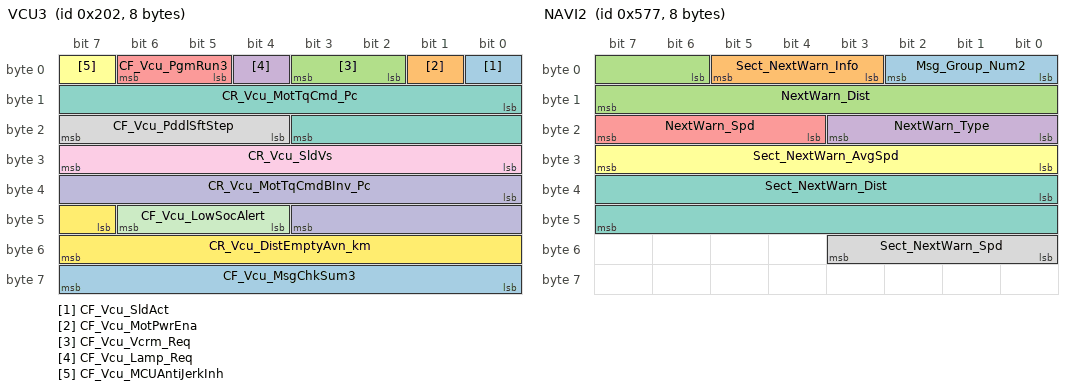
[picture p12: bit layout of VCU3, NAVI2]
BO_ 514 VCU3: 8 VCU
 SG_ CF_Vcu_SldAct : 0|1@1+ (1,0) [0|1] ""  CGW,TMU
 SG_ CF_Vcu_MotPwrEna : 1|1@1+ (1,0) [0|1] ""  CGW,MCU,TMU
 SG_ CF_Vcu_Vcrm_Req : 2|2@1+ (1,0) [0|3] ""  CGW,H_U,TMU,vBDM
 SG_ CF_Vcu_Lamp_Req : 4|1@1+ (1,0) [0|1] ""  CGW,H_U,TMU
 SG_ CF_Vcu_PgmRun3 : 5|2@1+ (1,0) [0|3] ""  MCU,TMU
 SG_ CF_Vcu_MCUAntiJerkInh : 7|1@1+ (1,0) [0|1] ""  MCU,TMU
 SG_ CR_Vcu_MotTqCmd_Pc : 8|12@1- (0.048828125,0) [-100|99.95] "%"  CGW,MCU,TMU,iBAU
 SG_ CF_Vcu_PddlSftStep : 20|4@1+ (1,0) [0|15] ""  CGW,TMU
 SG_ CR_Vcu_SldVs : 24|8@1+ (1,0) [0|255] "km/h"  CGW,TMU
 SG_ CR_Vcu_MotTqCmdBInv_Pc : 32|12@1- (0.048828125,0) [-100|99.95] "%"  TMU,iBAU
 SG_ CF_Vcu_LowSocAlert : 44|3@1+ (1,0) [0|7] ""  CGW
 SG_ CR_Vcu_DistEmptyAvn_km : 47|9@1+ (2,0) [0|1022] "km"  CGW
 SG_ CF_Vcu_MsgChkSum3 : 56|8@1+ (1,0) [0|255] ""  MCU,TMU,iBAU

BO_ 1403 VCU10: 8 VCU
 SG_ CF_Vcu_CharInh : 0|1@1+ (1,0) [0|1] ""  OBC
 SG_ CF_Vcu_CharStopOpt : 1|2@1+ (1,0) [0|3] ""  BMS
 SG_ CF_Vcu_CharStopData : 3|6@1+ (1,40) [40|100] ""  BMS
 SG_ CF_Vcu_ClimateOperPerm : 9|1@1+ (1,0) [0|1] ""  BMS,CGW,DATC,TMU
 SG_ CF_Vcu_Aircon_Finish : 10|1@1+ (1,0) [0|1] ""  CGW,H_U,TMU
 SG_ CF_Vcu_AVN_Wakeup : 11|1@1+ (1,0) [0|1] ""  CGW,DATC,TMU
 SG_ CF_Vcu_IG3RlyMd : 12|4@1+ (1,0) [0|15] ""  BMS,CGW,DATC,H_U,LDC,OBC,TMU
 SG_ CF_Vcu_FailComfirmed : 16|1@1+ (1,0) [0|1] ""  BMS,CGW,DATC,H_U,OBC,TMU
 SG_ CF_Vcu_NoramlAriconCtr : 17|2@1+ (1,0) [0|3] ""  BMS,CGW,DATC,H_U,OBC,TMU
 SG_ CF_Vcu_ProgCharInfo : 19|1@1+ (1,0) [0|1] ""  BMS,CGW
 SG_ CF_Vuc_ProgCharWaitForCharInd : 20|1@1+ (1,0) [0|1] ""  BMS
 SG_ CF_Vcu_CharCancel : 21|1@1+ (1,0) [0|1] ""  BMS
 SG_ CF_Vcu_AirconCtr : 22|1@1+ (1,0) [0|1] ""  BMS,CGW,DATC
 SG_ CF_Vcu_TempUnit4FATC : 23|1@1+ (1,0) [0|1] ""  DATC
 SG_ CR_Vcu_TempSet4FATC : 24|6@1+ (0.5,15) [15|32] "Deg"  DATC
 SG_ CF_Vcu_MainRelayOnReq : 30|1@1+ (1,0) [0|1] ""  BMS
 SG_ CF_Vcu_IG3Only : 31|1@1+ (1,0) [0|1] ""  BMS,CGW,H_U,LDC,MCU,TMU
 SG_ CF_Vcu_ProgCharStop : 32|1@1+ (1,0) [0|1] ""  BMS
 SG_ CF_Vcu_ProgAirConInfo : 33|1@1+ (1,0) [0|1] ""  BMS,CGW,DATC
 SG_ CF_Vcu_SbwWarnMsg : 34|3@1+ (1,0) [0|7] "flag"  CGW
 SG_ CF_Vcu_SbwWarnSnd : 37|1@1+ (1,0) [0|1] "flag"  CGW
 SG_ CF_Vcu_Invalid : 39|1@1+ (1,0) [0|1] ""  CGW
 SG_ CR_Vcu_EcoPotential_Sport : 40|8@1+ (0.5,0) [0|100] "%"  CGW,TMU
 SG_ CR_Vcu_EcoPotential_Normal : 48|8@1+ (0.5,0) [0|100] "%"  CGW,TMU
 SG_ CR_Vcu_EcoPotential_Eco : 56|8@1+ (0.5,0) [0|100] "%"  CGW,TMU

BO_ 1402 VCU9: 8 VCU
 SG_ CR_Vcu_DepartSet1_Hour : 0|5@1+ (1,0) [0|23] "Hour"  CGW,TMU
 SG_ CR_Vcu_DepartSet1_Min : 5|3@1+ (10,0) [0|50] "Min"  CGW,TMU
 SG_ CF_Vcu_DepartSet1_Mon : 8|1@1+ (1,0) [0|1] ""  CGW,TMU
 SG_ CF_Vcu_DepartSet1_Tue : 9|1@1+ (1,0) [0|1] ""  CGW,TMU
 SG_ CF_Vcu_DepartSet1_Wed : 10|1@1+ (1,0) [0|1] ""  CGW,TMU
 SG_ CF_Vcu_DepartSet1_Thu : 11|1@1+ (1,0) [0|1] ""  CGW,TMU
 SG_ CF_Vcu_DepartSet1_Fri : 12|1@1+ (1,0) [0|1] ""  CGW,TMU
 SG_ CF_Vcu_DepartSet1_Sat : 13|1@1+ (1,0) [0|1] ""  CGW,TMU
 SG_ CF_Vcu_DepartSet1_Sun : 14|1@1+ (1,0) [0|1] ""  CGW,TMU
 SG_ CF_Vcu_DepartSet1_PreCondSet : 15|1@1+ (1,0) [0|1] ""  CGW,DATC,TMU
 SG_ CR_Vcu_DepartSet1_TempSet : 16|6@1+ (0.5,15) [15|32] "¡É"  CGW,TMU
 SG_ CF_Vcu_DepartSet1_TempUnit : 22|1@1+ (1,0) [0|1] ""  CGW,TMU
 SG_ CF_Vcu_DepartSet1_DefrostCtr : 23|1@1+ (1,0) [0|1] ""  CGW,TMU
 SG_ CF_Vcu_DepartSet1_Enable : 24|1@1+ (1,0) [0|1] ""  CGW,TMU
 SG_ CR_Vcu_DepartSet2_Hour : 25|5@1+ (1,0) [0|23] "Hour"  CGW,TMU
 SG_ CR_Vcu_DepartSet2_Min : 30|3@1+ (10,0) [0|50] "Min"  CGW,TMU
 SG_ CF_Vcu_DepartSet2_Mon : 33|1@1+ (1,0) [0|1] ""  CGW,TMU
 SG_ CF_Vcu_DepartSet2_Tue : 34|1@1+ (1,0) [0|1] ""  CGW,TMU
 SG_ CF_Vcu_DepartSet2_Wed : 35|1@1+ (1,0) [0|1] ""  CGW,TMU
 SG_ CF_Vcu_DepartSet2_Thu : 36|1@1+ (1,0) [0|1] ""  CGW,TMU
 SG_ CF_Vcu_DepartSet2_Fri : 37|1@1+ (1,0) [0|1] ""  CGW,TMU
 SG_ CF_Vcu_DepartSet2_Sat : 38|1@1+ (1,0) [0|1] ""  CGW,TMU
 SG_ CF_Vcu_DepartSet2_Sun : 39|1@1+ (1,0) [0|1] ""  CGW,TMU
 SG_ CF_Vcu_DepartSet2_PreCondSet : 40|1@1+ (1,0) [0|1] ""  CGW,DATC,TMU
 SG_ CR_Vcu_DepartSet2_TempSet : 41|6@1+ (0.5,15) [15|32] "¡É"  CGW,TMU
 SG_ CF_Vcu_DepartSet2_TempUnit : 47|1@1+ (1,0) [0|1] ""  CGW,TMU
 SG_ CF_Vcu_DepartSet2_DefrostCtr : 48|1@1+ (1,0) [0|1] ""  CGW,TMU
 SG_ CF_Vcu_DepartSet2_Enable : 49|1@1+ (1,0) [0|1] ""  CGW,TMU
 SG_ CF_VCU_IG3DrvSts : 50|1@1+ (1,0) [0|1] ""  LDC
 SG_ CF_VCU_AuxBattChgUsmSts : 62|2@1+ (1,0) [0|3] ""  CGW,LDC

BO_ 1399 NAVI2: 8 CGW
 SG_ Msg_Group_Num2 : 0|3@1+ (1,0) [0|7] ""  VCU
 SG_ Sect_NextWarn_Info : 3|3@1+ (1,0) [0|7] ""  VCU
 SG_ NextWarn_Dist : 6|10@1+ (1,0) [0|1023] "m"  VCU
 SG_ NextWarn_Type : 16|4@1+ (1,0) [0|15] ""  VCU
 SG_ NextWarn_Spd : 20|4@1+ (10,0) [0|150] "Km/h"  VCU
 SG_ Sect_NextWarn_AvgSpd : 24|8@1+ (1,0) [0|255] "Km/h"  VCU
 SG_ Sect_NextWarn_Dist : 32|16@1+ (1,0) [0|65535] "m"  VCU
 SG_ Sect_NextWarn_Spd : 48|4@1+ (10,0) [0|150] "Km/h"  VCU

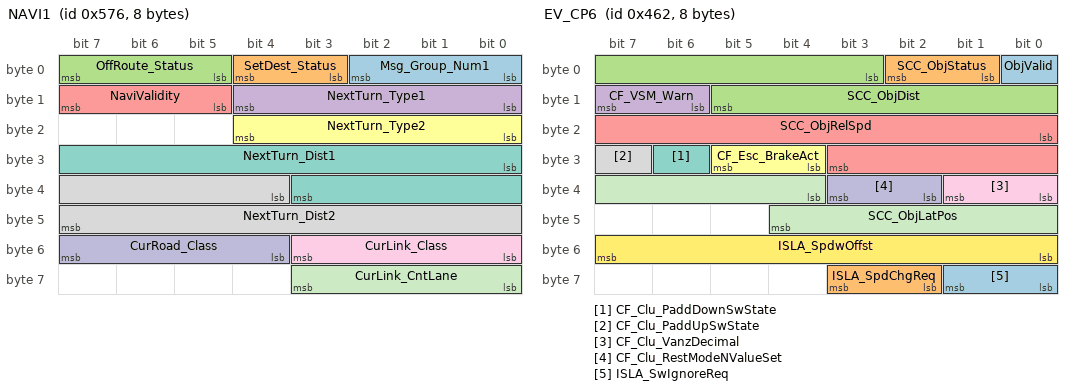
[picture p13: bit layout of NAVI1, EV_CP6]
BO_ 1398 NAVI1: 8 CGW
 SG_ Msg_Group_Num1 : 0|3@1+ (1,0) [0|7] ""  VCU
 SG_ SetDest_Status : 3|2@1+ (1,0) [0|3] ""  VCU
 SG_ OffRoute_Status : 5|3@1+ (1,0) [0|7] ""  VCU
 SG_ NextTurn_Type1 : 8|5@1+ (1,0) [0|31] ""  VCU
 SG_ NaviValidity : 13|3@1+ (1,0) [0|7] ""  VCU
 SG_ NextTurn_Type2 : 16|5@1+ (1,0) [0|31] ""  VCU
 SG_ NextTurn_Dist1 : 24|12@1+ (1,0) [0|4095] "m"  VCU
 SG_ NextTurn_Dist2 : 36|12@1+ (1,0) [0|4095] "m"  VCU
 SG_ CurLink_Class : 48|4@1+ (1,0) [0|15] ""  VCU
 SG_ CurRoad_Class : 52|4@1+ (1,0) [0|15] ""  VCU
 SG_ CurLink_CntLane : 56|4@1+ (1,0) [0|15] ""  VCU

BO_ 1122 EV_CP6: 8 CGW
 SG_ ObjValid : 0|1@1+ (1,0) [0|1] ""  VCU
 SG_ SCC_ObjStatus : 1|2@1+ (1,0) [0|3] "m"  VCU
 SG_ SCC_ObjDist : 3|11@1+ (0.1,0) [0|204.7] "m"  VCU
 SG_ CF_VSM_Warn : 14|2@1+ (1,0) [0|3] ""  VCU,VESS
 SG_ SCC_ObjRelSpd : 16|12@1+ (0.1,-170) [-170|239.5] "m/s"  VCU
 SG_ CF_Esc_BrakeAct : 28|2@1+ (1,0) [0|3] ""  ACU,EPB
 SG_ CF_Clu_PaddDownSwState : 30|1@1+ (1,0) [0|1] ""  VCU
 SG_ CF_Clu_PaddUpSwState : 31|1@1+ (1,0) [0|1] ""  VCU
 SG_ CF_Clu_VanzDecimal : 32|2@1+ (0.125,0) [0|0.375] ""  VCU
 SG_ CF_Clu_RestModeNValueSet : 34|2@1+ (1,0) [0|3] ""  VCU
 SG_ SCC_ObjLatPos : 36|9@1+ (0.1,-20) [-20|31.1] "m"  VCU
 SG_ ISLA_SpdwOffst : 48|8@1+ (1,0) [0|0] ""  VCU
 SG_ ISLA_SwIgnoreReq : 56|2@1+ (1,0) [0|0] ""  VCU
 SG_ ISLA_SpdChgReq : 58|2@1+ (1,0) [0|0] ""  VCU

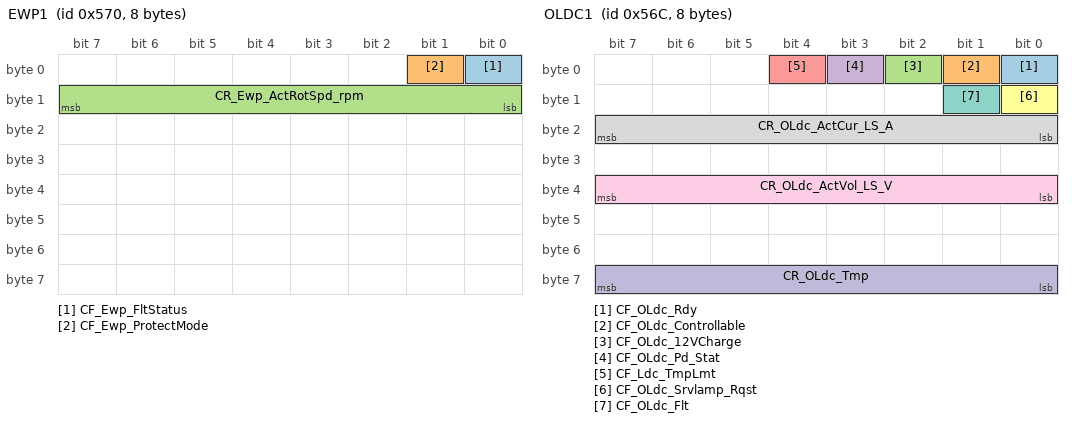
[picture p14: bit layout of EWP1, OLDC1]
BO_ 1392 EWP1: 8 EWP
 SG_ CF_Ewp_FltStatus : 0|1@1+ (1,0) [0|1] ""  DATC,MCU,TMU,VCU
 SG_ CF_Ewp_ProtectMode : 1|1@1+ (1,0) [0|1] ""  DATC,MCU,TMU,VCU
 SG_ CR_Ewp_ActRotSpd_rpm : 8|8@1+ (20,0) [0|5000] "rpm"  DATC,MCU,OBC,TMU,VCU

BO_ 1388 OLDC1: 8 OLDC
 SG_ CF_OLdc_Rdy : 0|1@1+ (1,0) [0|1] ""  LDC,TMU,VCU
 SG_ CF_OLdc_Controllable : 1|1@1+ (1,0) [0|1] ""  LDC,TMU,VCU
 SG_ CF_OLdc_12VCharge : 2|1@1+ (1,0) [0|1] ""  CGW,LDC,NEMS,TMU,VCU
 SG_ CF_OLdc_Pd_Stat : 3|1@1+ (1,0) [0|1] ""  CGW,LDC,MCU,NEMS,TMU
 SG_ CF_Ldc_TmpLmt : 4|1@1+ (1,0) [0|1] ""  MCU
 SG_ CF_OLdc_Srvlamp_Rqst : 8|1@1+ (1,0) [0|1] ""  CGW,H_U,LDC,TMU,vBDM
 SG_ CF_OLdc_Flt : 9|1@1+ (1,0) [0|1] ""  AAF,BMS,CGW,H_U,LDC,MCU,NEMS,OBC,TMU,VCU
 SG_ CR_OLdc_ActCur_LS_A : 16|8@1+ (1,0) [0|255] "A"  LDC,MCU,TMU
 SG_ CR_OLdc_ActVol_LS_V : 32|8@1+ (0.1,0) [0|25.5] "V"  CGW,LDC,MCU,OBC,TMU
 SG_ CR_OLdc_Tmp : 56|8@1+ (1,-100) [-100|155] "¡É"  AAF,LDC,TMU,VCU

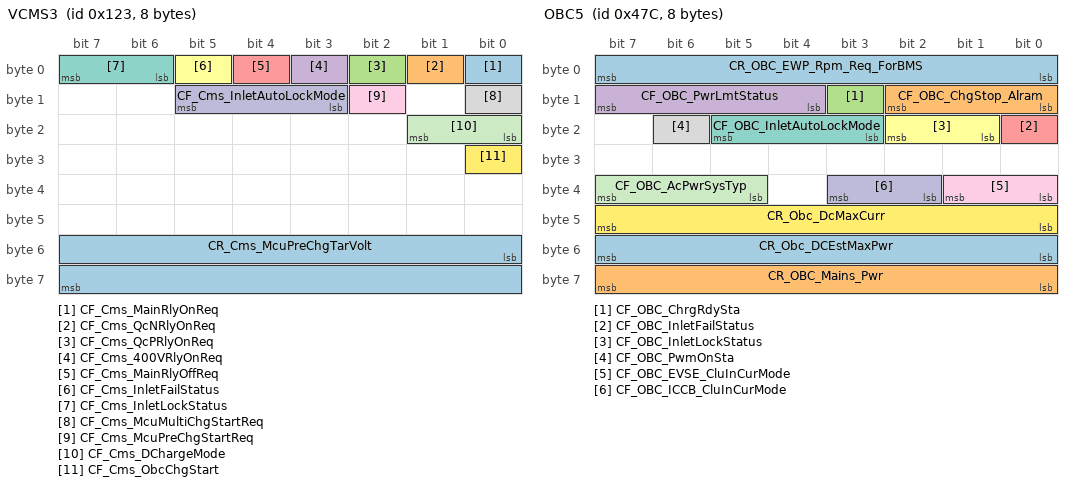
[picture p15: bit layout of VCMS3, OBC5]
BO_ 291 VCMS3: 8 VCMS
 SG_ CF_Cms_MainRlyOnReq : 0|1@1+ (1,0) [0|1] "flag"  BMS
 SG_ CF_Cms_QcNRlyOnReq : 1|1@1+ (1,0) [0|1] "flag"  BMS
 SG_ CF_Cms_QcPRlyOnReq : 2|1@1+ (1,0) [0|1] "flag"  BMS
 SG_ CF_Cms_400VRlyOnReq : 3|1@1+ (1,0) [0|1] "flag"  MCU
 SG_ CF_Cms_MainRlyOffReq : 4|1@1+ (1,0) [0|1] "flag"  BMS
 SG_ CF_Cms_InletFailStatus : 5|1@1+ (1,0) [0|1] "flag"  CGW
 SG_ CF_Cms_InletLockStatus : 6|2@1+ (1,0) [0|3] ""  BMS,CCM,OBC
 SG_ CF_Cms_McuMultiChgStartReq : 8|1@1+ (1,0) [0|1] "flag"  MCU
 SG_ CF_Cms_McuPreChgStartReq : 10|1@1+ (1,0) [0|1] "flag"  MCU
 SG_ CF_Cms_InletAutoLockMode : 11|3@1+ (1,0) [0|7] "flag"  CGW
 SG_ CF_Cms_DChargeMode : 16|2@1+ (1,0) [0|3] ""  BMS,CCM,MCU,OBC
 SG_ CF_Cms_ObcChgStart : 24|1@1+ (1,0) [0|1] "flag"  BMS,OBC
 SG_ CR_Cms_McuPreChgTarVolt : 48|16@1+ (0.1,0) [0|6553.5] "V"  MCU

BO_ 1148 OBC5: 8 OBC
 SG_ CR_OBC_EWP_Rpm_Req_ForBMS : 0|8@1+ (20,0) [0|5100] ""  BMS,CGW,vBDM
 SG_ CF_OBC_ChgStop_Alram : 8|3@1+ (1,0) [0|7] ""  CGW
 SG_ CF_OBC_ChrgRdySta : 11|1@1+ (1,0) [0|1] ""  Dummy
 SG_ CF_OBC_PwrLmtStatus : 12|4@1+ (1,0) [0|0] ""  LDC
 SG_ CF_OBC_InletFailStatus : 16|1@1+ (1,0) [0|1] ""  BMS,CGW,TMU,VCU
 SG_ CF_OBC_InletLockStatus : 17|2@1+ (1,0) [0|3] ""  BMS,CGW,TMU,VCU
 SG_ CF_OBC_InletAutoLockMode : 19|3@1+ (1,0) [0|0] ""  CGW
 SG_ CF_OBC_PwmOnSta : 22|1@1+ (1,0) [0|0] ""  Dummy
 SG_ CF_OBC_EVSE_CluInCurMode : 32|2@1+ (1,0) [0|0] ""  BMS,CGW
 SG_ CF_OBC_ICCB_CluInCurMode : 34|2@1+ (1,0) [0|0] ""  BMS,CGW
 SG_ CF_OBC_AcPwrSysTyp : 37|3@1+ (1,0) [0|0] ""  BMS
 SG_ CR_Obc_DcMaxCurr : 40|8@1+ (1,0) [0|100] "A"  BMS
 SG_ CR_Obc_DCEstMaxPwr : 48|8@1+ (0.1,0) [0|25] "kW"  BMS
 SG_ CR_OBC_Mains_Pwr : 56|8@1+ (0.1,0) [0|0] "kW"  CGW,H_U,TMU

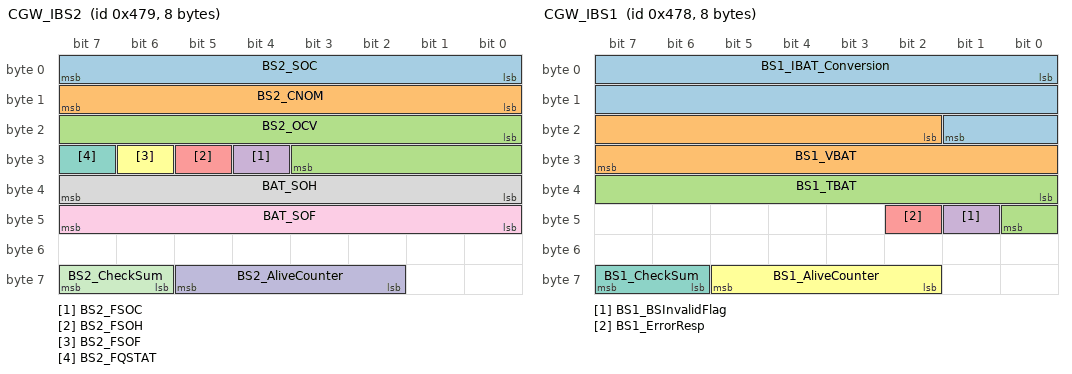
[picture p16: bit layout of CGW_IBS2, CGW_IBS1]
BO_ 1145 CGW_IBS2: 8 CGW
 SG_ BS2_SOC : 0|8@1+ (1,0) [0|100] "%"  Dummy
 SG_ BS2_CNOM : 8|8@1+ (1,0) [0|120] "Ah"  Dummy
 SG_ BS2_OCV : 16|12@1+ (0.001,10) [10|14] "V"  Dummy
 SG_ BS2_FSOC : 28|1@1+ (1,0) [0|1] ""  Dummy
 SG_ BS2_FSOH : 29|1@1+ (1,0) [0|1] ""  Dummy
 SG_ BS2_FSOF : 30|1@1+ (1,0) [0|1] ""  Dummy
 SG_ BS2_FQSTAT : 31|1@1+ (1,0) [0|1] ""  Dummy
 SG_ BAT_SOH : 32|8@1+ (1,0) [0|100] "%"  Dummy
 SG_ BAT_SOF : 40|8@1+ (0.05,0) [0|12] "V"  Dummy
 SG_ BS2_AliveCounter : 58|4@1+ (1,0) [0|15] ""  Dummy
 SG_ BS2_CheckSum : 62|2@1+ (1,0) [0|3] ""  Dummy

BO_ 1144 CGW_IBS1: 8 CGW
 SG_ BS1_IBAT_Conversion : 0|18@1+ (10,-1200000) [-1200000|1200000] "mA"  Dummy
 SG_ BS1_VBAT : 18|14@1+ (0.001,6) [6|18] "V"  Dummy
 SG_ BS1_TBAT : 32|9@1+ (0.5,-40) [-40|125] "¡É"  Dummy
 SG_ BS1_BSInvalidFlag : 41|1@1+ (1,0) [0|1] ""  Dummy
 SG_ BS1_ErrorResp : 42|1@1+ (1,0) [0|1] ""  Dummy
 SG_ BS1_AliveCounter : 58|4@1+ (1,0) [0|15] ""  Dummy
 SG_ BS1_CheckSum : 62|2@1+ (1,0) [0|3] ""  Dummy

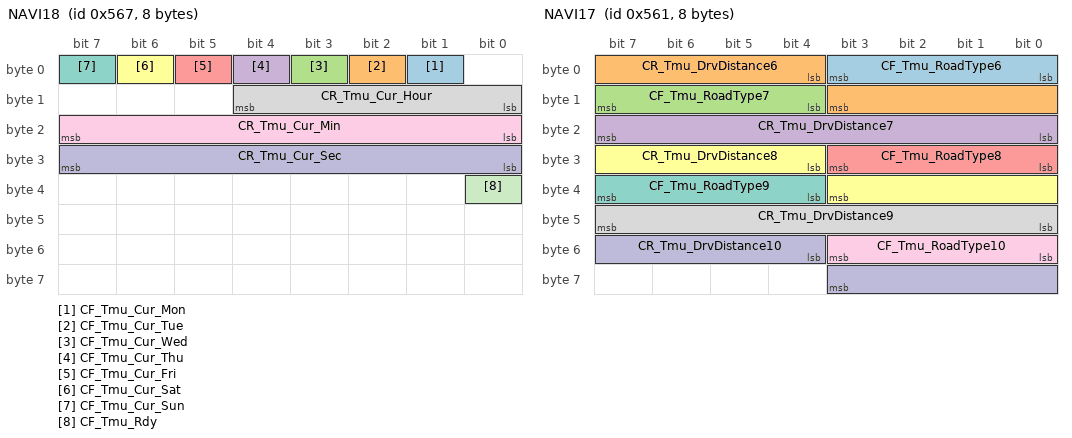
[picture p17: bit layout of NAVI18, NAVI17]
BO_ 1383 NAVI18: 8 CGW
 SG_ CF_Tmu_Cur_Mon : 1|1@1+ (1,0) [0|1] ""  VCU
 SG_ CF_Tmu_Cur_Tue : 2|1@1+ (1,0) [0|1] ""  VCU
 SG_ CF_Tmu_Cur_Wed : 3|1@1+ (1,0) [0|1] ""  VCU
 SG_ CF_Tmu_Cur_Thu : 4|1@1+ (1,0) [0|1] ""  VCU
 SG_ CF_Tmu_Cur_Fri : 5|1@1+ (1,0) [0|1] ""  VCU
 SG_ CF_Tmu_Cur_Sat : 6|1@1+ (1,0) [0|1] ""  VCU
 SG_ CF_Tmu_Cur_Sun : 7|1@1+ (1,0) [0|1] ""  VCU
 SG_ CR_Tmu_Cur_Hour : 8|5@1+ (1,0) [0|23] "Hour"  VCU
 SG_ CR_Tmu_Cur_Min : 16|8@1+ (1,0) [0|59] "min"  VCU
 SG_ CR_Tmu_Cur_Sec : 24|8@1+ (1,0) [0|59] "Sec"  VCU
 SG_ CF_Tmu_Rdy : 32|1@1+ (1,0) [0|1] ""  DATC,OBC,VCU

BO_ 1377 NAVI17: 8 CGW
 SG_ CF_Tmu_RoadType6 : 0|4@1+ (1,0) [0|15] ""  VCU
 SG_ CR_Tmu_DrvDistance6 : 4|8@1+ (1,0) [0|255] "km"  VCU
 SG_ CF_Tmu_RoadType7 : 12|4@1+ (1,0) [0|15] ""  VCU
 SG_ CR_Tmu_DrvDistance7 : 16|8@1+ (1,0) [0|255] "km"  VCU
 SG_ CF_Tmu_RoadType8 : 24|4@1+ (1,0) [0|15] ""  VCU
 SG_ CR_Tmu_DrvDistance8 : 28|8@1+ (1,0) [0|255] "km"  VCU
 SG_ CF_Tmu_RoadType9 : 36|4@1+ (1,0) [0|15] ""  VCU
 SG_ CR_Tmu_DrvDistance9 : 40|8@1+ (1,0) [0|255] "km"  VCU
 SG_ CF_Tmu_RoadType10 : 48|4@1+ (1,0) [0|15] ""  VCU
 SG_ CR_Tmu_DrvDistance10 : 52|8@1+ (1,0) [0|255] "km"  VCU

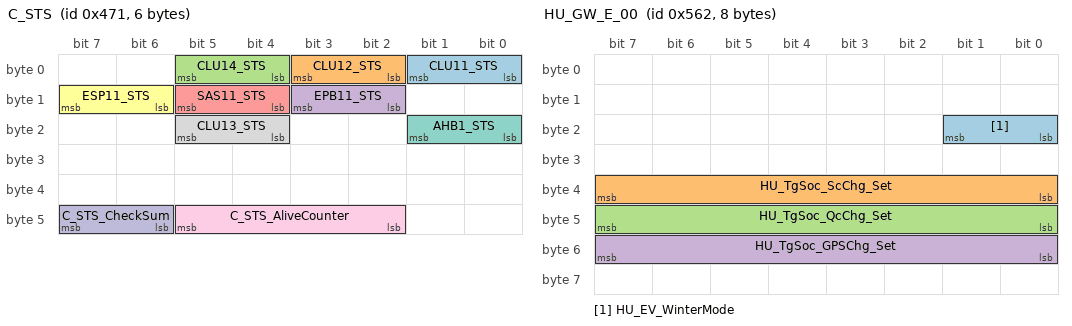
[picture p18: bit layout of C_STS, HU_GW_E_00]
BO_ 1137 C_STS: 6 CGW
 SG_ CLU11_STS : 0|2@1+ (1,0) [0|3] ""  VESS
 SG_ CLU12_STS : 2|2@1+ (1,0) [0|3] ""  AAF,LDC,MCU
 SG_ CLU14_STS : 4|2@1+ (1,0) [0|3] ""  Dummy
 SG_ EPB11_STS : 10|2@1+ (1,0) [0|3] ""  Dummy
 SG_ SAS11_STS : 12|2@1+ (1,0) [0|3] ""  Dummy
 SG_ ESP11_STS : 14|2@1+ (1,0) [0|3] ""  Dummy
 SG_ AHB1_STS : 16|2@1+ (1,0) [0|3] ""  Dummy
 SG_ CLU13_STS : 20|2@1+ (1,0) [0|3] ""  VCU
 SG_ C_STS_AliveCounter : 42|4@1+ (1,0) [0|15] ""  AAF,LDC,MCU,VCU,VESS
 SG_ C_STS_CheckSum : 46|2@1+ (1,0) [0|3] ""  AAF,LDC,MCU,VCU,VESS

BO_ 1378 HU_GW_E_00: 8 CGW
 SG_ HU_EV_WinterMode : 16|2@1+ (1,0) [0|0] ""  BMS
 SG_ HU_TgSoc_ScChg_Set : 32|8@1+ (0.5,0) [0|100] "%"  BMS
 SG_ HU_TgSoc_QcChg_Set : 40|8@1+ (0.5,0) [0|100] "%"  BMS
 SG_ HU_TgSoc_GPSChg_Set : 48|8@1+ (0.5,0) [0|100] "%"  BMS

BO_ 1032 VCMS13: 8 VCMS
 SG_ CR_Cms_EVTransferType : 0|4@1+ (1,0) [0|9] ""  CCM
 SG_ CR_Cms_PLCChgFaultSubCode : 24|8@1+ (1,0) [0|255] ""  BMS,CCM,MCU
 SG_ CR_Cms_ChgEstPwr : 32|16@1+ (10,0) [0|655350] "W"  BMS,CCM,OBC

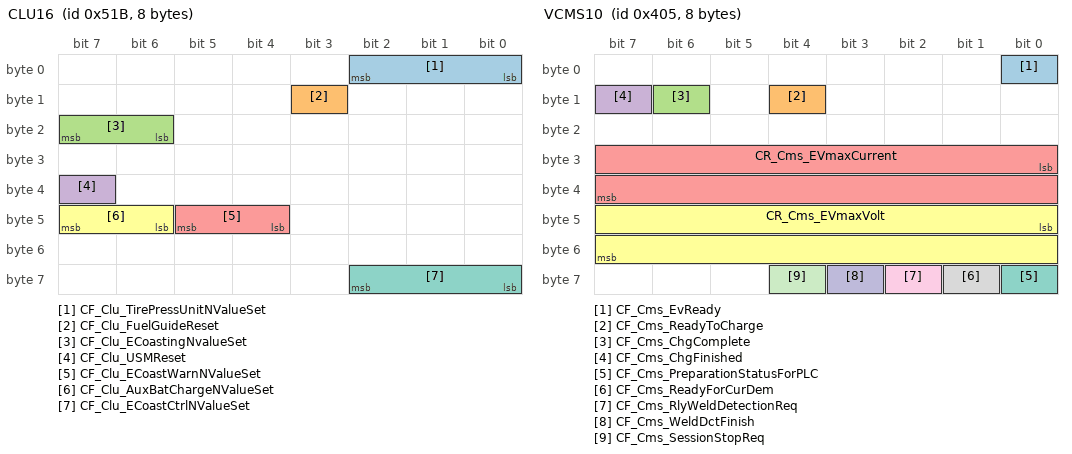
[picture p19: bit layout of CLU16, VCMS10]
BO_ 1307 CLU16: 8 CGW
 SG_ CF_Clu_TirePressUnitNValueSet : 0|3@1+ (1,0) [0|7] ""  IBU,vBDM
 SG_ CF_Clu_FuelGuideReset : 11|1@1+ (1,0) [0|1] ""  VCU
 SG_ CF_Clu_ECoastingNvalueSet : 22|2@1+ (1,0) [0|1] ""  VCU
 SG_ CF_Clu_USMReset : 39|1@1+ (1,0) [0|1] ""  DATC,IBU,SMK,TMU,VCU,iBAU
 SG_ CF_Clu_ECoastWarnNValueSet : 44|2@1+ (1,0) [0|3] ""  VCU
 SG_ CF_Clu_AuxBatChargeNValueSet : 46|2@1+ (1,0) [0|3] ""  VCU
 SG_ CF_Clu_ECoastCtrlNValueSet : 56|3@1+ (1,0) [0|7] ""  VCU

BO_ 339 TCS11: 8 iBAU
 SG_ TCS_REQ : 0|1@1+ (1,0) [0|1] ""  Dummy
 SG_ MSR_C_REQ : 1|1@1+ (1,0) [0|1] ""  Dummy
 SG_ TCS_PAS : 2|1@1+ (1,0) [0|1] ""  Dummy
 SG_ TCS_GSC : 3|1@1+ (1,0) [0|1] ""  Dummy
 SG_ CF_Esc_LimoInfo : 4|2@1+ (1,0) [0|3] ""  Dummy
 SG_ ABS_DIAG : 6|1@1+ (1,0) [0|1] ""  Dummy
 SG_ ABS_DEF : 7|1@1+ (1,0) [0|1] ""  ACU
 SG_ TCS_DEF : 8|1@1+ (1,0) [0|1] ""  Dummy
 SG_ TCS_CTL : 9|1@1+ (1,0) [0|1] ""  MCU
 SG_ ABS_ACT : 10|1@1+ (1,0) [0|1] ""  ACU,MCU
 SG_ EBD_DEF : 11|1@1+ (1,0) [0|1] ""  Dummy
 SG_ ESP_PAS : 12|1@1+ (1,0) [0|1] ""  ACU
 SG_ ESP_DEF : 13|1@1+ (1,0) [0|1] ""  ACU
 SG_ ESP_CTL : 14|1@1+ (1,0) [0|1] ""  ACU
 SG_ TCS_MFRN : 15|1@1+ (1,0) [0|1] ""  Dummy
 SG_ DBC_CTL : 16|1@1+ (1,0) [0|1] ""  Dummy
 SG_ DBC_PAS : 17|1@1+ (1,0) [0|1] ""  Dummy
 SG_ DBC_DEF : 18|1@1+ (1,0) [0|1] ""  Dummy
 SG_ HAC_CTL : 19|1@1+ (1,0) [0|1] ""  Dummy
 SG_ HAC_PAS : 20|1@1+ (1,0) [0|1] ""  Dummy
 SG_ HAC_DEF : 21|1@1+ (1,0) [0|1] ""  Dummy
 SG_ ESS_STAT : 22|2@1+ (1,0) [0|3] ""  CGW,H_U,TMU,vBDM
 SG_ TQI_TCS : 24|8@1+ (0.390625,0) [0|99.609375] "%"  Dummy
 SG_ TQI_MSR : 32|8@1+ (0.390625,0) [0|99.609375] "%"  Dummy
 SG_ TQI_SLW_TCS : 40|8@1+ (0.390625,0) [0|99.609375] "%"  Dummy
 SG_ CF_Esc_BrkCtl : 48|1@1+ (1,0) [0|1] ""  Dummy
 SG_ CF_Brk_AbsNReq : 49|1@1+ (1,0) [0|1] ""  VCU
 SG_ BLA_CTL : 50|2@1+ (1,0) [0|3] ""  CGW
 SG_ AliveCounter_TCS1 : 52|4@1+ (1,0) [0|14] ""  Dummy
 SG_ CheckSum_TCS1 : 56|8@1+ (1,0) [0|255] ""  Dummy

BO_ 1029 VCMS10: 8 VCMS
 SG_ CF_Cms_EvReady : 0|1@1+ (1,0) [0|1] "flag"  BMS,CCM,OBC
 SG_ CF_Cms_ReadyToCharge : 12|1@1+ (1,0) [0|1] "flag"  BMS,CCM,MCU,OBC
 SG_ CF_Cms_ChgComplete : 14|1@1+ (1,0) [0|1] "flag"  BMS,CCM,MCU,OBC
 SG_ CF_Cms_ChgFinished : 15|1@1+ (1,0) [0|1] "flag"  BMS,CCM,MCU,OBC
 SG_ CR_Cms_EVmaxCurrent : 24|16@1+ (0.1,0) [0|6553.5] "A"  BMS,CCM,OBC
 SG_ CR_Cms_EVmaxVolt : 40|16@1+ (0.1,0) [0|6553.5] "V"  BMS,CCM,MCU,OBC
 SG_ CF_Cms_PreparationStatusForPLC : 56|1@1+ (1,0) [0|1] "flag"  CCM
 SG_ CF_Cms_ReadyForCurDem : 57|1@1+ (1,0) [0|1] "flag"  CCM
 SG_ CF_Cms_RlyWeldDetectionReq : 58|1@1+ (1,0) [0|1] "flag"  CCM
 SG_ CF_Cms_WeldDctFinish : 59|1@1+ (1,0) [0|1] "flag"  CCM
 SG_ CF_Cms_SessionStopReq : 60|1@1+ (1,0) [0|1] "flag"  CCM

BO_ 1030 VCMS11: 8 VCMS
 SG_ CR_Cms_EVTargetVolt : 16|16@1+ (0.1,0) [0|6553.5] ""  BMS,CCM,MCU
 SG_ CR_Cms_EVTargetCurrent : 32|16@1+ (0.1,0) [0|6553.5] "A"  BMS,CCM,MCU

BO_TX_BU_ 1375 : CGW,TMU;
BO_TX_BU_ 1383 : CGW,TMU;
BO_TX_BU_ 1377 : CGW,TMU;

CM_ BO_ 1100 "[P] Periodic";
CM_ BO_ 1375 "[P] Periodic";
CM_ BO_ 820 "[P] Periodic";
CM_ BO_ 1103 "[P] Periodic";
CM_ BO_ 817 "[P] Periodic";
CM_ BO_ 544 "[P] Periodic";
CM_ BO_ 819 "[P] Periodic";
CM_ BO_ 1098 "[P] Periodic";
CM_ SG_ 1098 CF_Evp2_Stat "this signal is only for case which the warning lamp is illuminated when the EVP is defective";
CM_ SG_ 1098 CF_Evp2_DefMode "Information regarding the EVP 'defective' State Mode";
CM_ SG_ 1098 CF_Evp2_RunCount "This signal indicates Vacuum Pump Running Time information.";
CM_ SG_ 1098 CF_Evp2_RunChk "This signal indicates Vacuum Pump Running Command information.";
CM_ BO_ 1369 "[PE] Periodic and On Event";
CM_ SG_ 1369 CF_Gway_StaticBendLhAct "This signal is for ¡°IPM (Gateway)¡± applied vehicles only.";
CM_ SG_ 1369 CF_Gway_StaticBendRhAct "This signal is for ¡°IPM (Gateway)¡± applied vehicles only.";
CM_ BO_ 1099 "[P] Periodic";
CM_ BO_ 1364 "[E] On Event";
CM_ BO_ 1363 "[PE] Periodic and On Event";
CM_ SG_ 1363 CF_Gway_RRDrSw "This signal is for ¡°IPM (Gateway)¡± applied vehicles only.";
CM_ SG_ 1363 CF_Gway_RLDrSw "This signal is for ¡°IPM (Gateway)¡± applied vehicles only.";
CM_ SG_ 1363 CF_Gway_IntTailAct "This signal is for ¡°IPM (Gateway)¡± applied vehicles only.";
CM_ SG_ 1363 CF_Gway_SMKRKECmd "This signal is for ¡°IPM (Gateway)¡± applied vehicles only.";
CM_ BO_ 1358 "[P] Periodic";
CM_ BO_ 1117 "[P] Periodic";
CM_ BO_ 1116 "[PE] Periodic and On Event";
CM_ BO_ 16 "[E] On Event";
CM_ SG_ 16 Acu_TypOfCrash "This signal indicates types of  crash.";
CM_ BO_ 1359 "[E] On Event";
CM_ BO_ 1118 "[P] Periodic";
CM_ BO_ 1354 "[P] Periodic";
CM_ BO_ 1115 "[P] Periodic";
CM_ BO_ 1353 "[P] Periodic";
CM_ BO_ 265 "[P] Periodic";
CM_ BO_ 1346 "[P] Periodic";
CM_ BO_ 1104 "[P] Periodic";
CM_ SG_ 1104 CF_Clu_Vanz "This signal is same as another one in CLU11 message on C-CAN. It means this signal is indirectly routed from C-CAN to P-CAN through Gateway unit.";
CM_ SG_ 1104 CF_Clu_RheostatLevel "This signal is for ¡°IPM (Gateway)¡± applied vehicles only.
This signal has Validity with Battery (Not IGN1)";
CM_ SG_ 1104 CF_Clu_CruiseSwState "This signal is same as another one in CLU11 message on C-CAN. It means this signal is indirectly routed from C-CAN to P-CAN through Gateway unit.";
CM_ SG_ 1104 CF_Clu_CruiseSwMain "This signal is same as another one in CLU11 message on C-CAN. It means this signal is indirectly routed from C-CAN to P-CAN through Gateway unit.";
CM_ SG_ 1104 CF_Clu_SPEED_UNIT "This signal is same as another one in CLU11 message on C-CAN. It means this signal is indirectly routed from C-CAN to P-CAN through Gateway unit.";
CM_ SG_ 1104 AVH_STAT "This signal is same as another one in ESP11 message on C-CAN. It means this signal is indirectly routed from C-CAN to P-CAN through Gateway unit.";
CM_ BO_ 1344 "[P] Periodic";
CM_ BO_ 1345 "[PE] Periodic and On Event";
CM_ SG_ 1345 CF_Gway_LightSwState "This signal is for ¡°IPM (Gateway)¡± applied vehicles only.";
CM_ SG_ 1345 CF_Gway_TSigLHSw "This signal is for ¡°IPM (Gateway)¡± applied vehicles only.";
CM_ SG_ 1345 CF_Gway_TSigRHSw "This signal is for ¡°IPM (Gateway)¡± applied vehicles only.";
CM_ SG_ 1345 CF_Gway_DriveTypeOption "This signal is for ¡°IPM (Gateway)¡± applied vehicles only.";
CM_ SG_ 1345 CF_Gway_StarterRlyState "This signal is for ¡°IPM (Gateway)¡± applied vehicles only.";
CM_ SG_ 1345 CF_Gway_PassiveAccessLock "This signal is for ¡°IPM (Gateway)¡± applied vehicles only.";
CM_ SG_ 1345 CF_Gway_PassiveAccessUnlock "This signal is for ¡°IPM (Gateway)¡± applied vehicles only.";
CM_ SG_ 1345 CF_Gway_HLpHighSw "This signal is for ¡°IPM (Gateway)¡± applied vehicles only.";
CM_ SG_ 1345 CF_Gway_InhibitRMT "This signal is for ¡°IPM (Gateway)¡± applied vehicles only.";
CM_ SG_ 1345 CF_Gway_Ign1 "Status of Ignition 1";
CM_ SG_ 1345 CF_Gway_Ign2 "Status of Ignition 2";
CM_ BO_ 1405 "[P] Periodic";
CM_ BO_ 1404 "[P] Periodic";
CM_ BO_ 1407 "[P] Periodic";
CM_ BO_ 1406 "[P] Periodic";
CM_ BO_ 1133 "[PE] Periodic and On Event";
CM_ BO_ 1401 "[P] Periodic";
CM_ SG_ 1401 CF_Vcu_SpdLmt "`";
CM_ BO_ 512 "[P] Periodic";
CM_ BO_ 513 "[P] Periodic";
CM_ BO_ 1400 "[P] Periodic";
CM_ SG_ 1400 CF_Ahb_Def "This signal is same as another one in AHB1 message on C-CAN. It means this signal is indirectly routed from C-CAN to P-CAN through Gateway unit.";
CM_ SG_ 1400 CF_Clu_ActiveEcoSW "This signal is same as another one in CLU13 message on C-CAN. It means this signal is indirectly routed from C-CAN to P-CAN through Gateway unit.
This signal is for the Active ECO equipped vehicle only.";
CM_ SG_ 1400 CF_DAW_Warn "This signal is for DAW CLU HMI output";
CM_ SG_ 1400 CF_Clu_DAWLastBreakTime "This signal is used for Driver Attention Warning level calculation by continuous driving time. This signal is reset by CF_DAW_TimeReset signal of LKA12 Message";
CM_ BO_ 514 "[P] Periodic";
CM_ BO_ 1403 "[P] Periodic";
CM_ BO_ 1402 "[P] Periodic";
CM_ BO_ 1399 "[P] Periodic";
CM_ BO_ 1398 "[P] Periodic";
CM_ BO_ 1122 "[P] Periodic";
CM_ BO_ 1392 "[P] Periodic";
CM_ BO_ 1388 "[P] Periodic";
CM_ BO_ 291 "[P] Periodic";
CM_ BO_ 1148 "[P] Periodic";
CM_ BO_ 1145 "[P] Periodic";
CM_ SG_ 1145 BS2_SOC "This signal is Battery SOC from battery sensor.";
CM_ SG_ 1145 BAT_SOH "This signal is Battery SOH from battery sensor.";
CM_ SG_ 1145 BAT_SOF "This signal is Battery SOF from battery sensor.";
CM_ BO_ 1144 "[P] Periodic";
CM_ SG_ 1144 BS1_VBAT "This signal is Battery Voltage from battery sensor.";
CM_ SG_ 1144 BS1_TBAT "This signal is Battery electrolyte temperature from battery sensor.";
CM_ BO_ 1383 "[P] Periodic";
CM_ BO_ 1377 "[P] Periodic";
CM_ BO_ 1137 "[P] Periodic";
CM_ BO_ 1378 "[E] On Event";
CM_ BO_ 1032 "[P] Periodic";
CM_ BO_ 1307 "[E] On Event";
CM_ SG_ 1307 CF_Clu_TirePressUnitNValueSet "Request to set Tire Pressure Unit";
CM_ BO_ 339 "[P] Periodic";
CM_ BO_ 1029 "[P] Periodic";
CM_ BO_ 1030 "[P] Periodic";
BA_DEF_ SG_  "GenSigEnvVarType" ENUM  "Int","Float","Undef";
BA_DEF_ SG_  "GenSigEVName" STRING ;
BA_DEF_ SG_  "GenSigInactiveValue" INT 0 65535;
BA_DEF_ SG_  "GenSigSendType" ENUM  "Cyclic","OnWrite","OnWriteWithRepetition","OnChange","OnChangeWithRepetition","IfActive","IfActiveWithRepetition","NoSigSendType";
BA_DEF_ SG_  "GenSigStartValue" INT 0 1215752192;
BA_DEF_ SG_  "GwSigLatencyTime" INT 0 65535;
BA_DEF_ SG_  "GwSigMissingSourceType" ENUM  "Undef","OldValue","DefaultValue","InitialValue";
BA_DEF_ SG_  "SignalCategory" HEX 10 15;
BA_DEF_ BO_  "GenMsgCycleTime" INT 0 2000;
BA_DEF_ BO_  "GenMsgCycleTimeFast" INT 0 500;
BA_DEF_ BO_  "GenMsgDelayTime" INT 0 20;
BA_DEF_ BO_  "GenMsgILSupport" ENUM  "No","Yes";
BA_DEF_ BO_  "GenMsgNrOfRepetition" INT 0 3;
BA_DEF_ BO_  "GenMsgSendType" ENUM  "Cyclic","not_used","not_used","not_used","not_used","not_used","not_used","not_used","NoMsgSendType";
BA_DEF_ BO_  "GenMsgStartDelayTime" INT 0 2000;
BA_DEF_ BU_  "GenNodSleepTime" INT 1375 1650;
BA_DEF_ BU_  "ILUsed" ENUM  "No","Yes";
BA_DEF_ BU_  "NmCAN" INT 1 2;
BA_DEF_ BU_  "NmStationAddress" HEX 0 255;
BA_DEF_ BU_  "NodeLayerModules" STRING ;
BA_DEF_  "Baudrate" INT 50000 1000000;
BA_DEF_  "BusType" STRING ;
BA_DEF_  "GenEnvVarEndingDsp" STRING ;
BA_DEF_  "GenEnvVarEndingSnd" STRING ;
BA_DEF_  "GenEnvVarPrefix" STRING ;
BA_DEF_  "GenNWMApBusSleep" STRING ;
BA_DEF_  "GenNWMApCanNormal" STRING ;
BA_DEF_  "GenNWMApCanOff" STRING ;
BA_DEF_  "GenNWMApCanOn" STRING ;
BA_DEF_  "GenNWMApCanSleep" STRING ;
BA_DEF_  "GenNWMApCanWakeUp" STRING ;
BA_DEF_  "GenNWMGotoMode_Awake" STRING ;
BA_DEF_  "GenNWMGotoMode_BusSleep" STRING ;
BA_DEF_  "GenNWMSleepTime" INT 1375 1650;
BA_DEF_  "GenNWMTalkNM" STRING ;
BA_DEF_  "Manufacturer" STRING ;
BA_DEF_  "NmBaseAddress" HEX 0 2047;
BA_DEF_  "NmMessageCount" INT 0 128;
BA_DEF_  "NmType" STRING ;
BA_DEF_  "SamplePointMax" INT 50 85;
BA_DEF_  "SamplePointMin" INT 55 85;
BA_DEF_  "SyncJumpWidthMax" INT 1 8;
BA_DEF_  "SyncJumpWidthMin" INT 1 4;
BA_DEF_  "VersionDay" INT 1 31;
BA_DEF_  "VersionMonth" INT 1 12;
BA_DEF_  "VersionWeek" INT 1 53;
BA_DEF_  "VersionYear" INT 0 9999;
BA_DEF_REL_ BU_SG_REL_  "GenSigTimeoutTime" INT 0 7000;
BA_DEF_DEF_  "GenSigEnvVarType" "Undef";
BA_DEF_DEF_  "GenSigEVName" "@Signame";
BA_DEF_DEF_  "GenSigInactiveValue" 0;
BA_DEF_DEF_  "GenSigSendType" "NoSigSendType";
BA_DEF_DEF_  "GenSigStartValue" 0;
BA_DEF_DEF_  "GwSigLatencyTime" 40;
BA_DEF_DEF_  "GwSigMissingSourceType" "Undef";
BA_DEF_DEF_  "SignalCategory" 12;
BA_DEF_DEF_  "GenMsgCycleTime" 10;
BA_DEF_DEF_  "GenMsgCycleTimeFast" 40;
BA_DEF_DEF_  "GenMsgDelayTime" 20;
BA_DEF_DEF_  "GenMsgILSupport" "Yes";
BA_DEF_DEF_  "GenMsgNrOfRepetition" 0;
BA_DEF_DEF_  "GenMsgSendType" "Cyclic";
BA_DEF_DEF_  "GenMsgStartDelayTime" 0;
BA_DEF_DEF_  "GenNodSleepTime" 1500;
BA_DEF_DEF_  "ILUsed" "Yes";
BA_DEF_DEF_  "NmCAN" 1;
BA_DEF_DEF_  "NmStationAddress" 0;
BA_DEF_DEF_  "NodeLayerModules" "oseknm01.dll";
BA_DEF_DEF_  "Baudrate" 500000;
BA_DEF_DEF_  "BusType" "CAN";
BA_DEF_DEF_  "GenEnvVarEndingDsp" "Dsp_";
BA_DEF_DEF_  "GenEnvVarEndingSnd" "_";
BA_DEF_DEF_  "GenEnvVarPrefix" "Env";
BA_DEF_DEF_  "GenNWMApBusSleep" "ApplNmCanBusSleep()";
BA_DEF_DEF_  "GenNWMApCanNormal" "ApplNmCanNormal()";
BA_DEF_DEF_  "GenNWMApCanOff" "ApplCanOffline()";
BA_DEF_DEF_  "GenNWMApCanOn" "ApplCanOnline()";
BA_DEF_DEF_  "GenNWMApCanSleep" "ApplNmCanSleep()";
BA_DEF_DEF_  "GenNWMApCanWakeUp" "ApplCanWakeUp()";
BA_DEF_DEF_  "GenNWMGotoMode_Awake" "GotoMode_Awake()";
BA_DEF_DEF_  "GenNWMGotoMode_BusSleep" "GotoMode_BusSleep()";
BA_DEF_DEF_  "GenNWMSleepTime" 1500;
BA_DEF_DEF_  "GenNWMTalkNM" "TalkNM()";
BA_DEF_DEF_  "Manufacturer" "HMC";
BA_DEF_DEF_  "NmBaseAddress" 1024;
BA_DEF_DEF_  "NmMessageCount" 128;
BA_DEF_DEF_  "NmType" "Vector";
BA_DEF_DEF_  "SamplePointMax" 82;
BA_DEF_DEF_  "SamplePointMin" 75;
BA_DEF_DEF_  "SyncJumpWidthMax" 3;
BA_DEF_DEF_  "SyncJumpWidthMin" 2;
BA_DEF_DEF_  "VersionDay" 1;
BA_DEF_DEF_  "VersionMonth" 1;
BA_DEF_DEF_  "VersionWeek" 1;
BA_DEF_DEF_  "VersionYear" 2010;
BA_DEF_DEF_REL_ "GenSigTimeoutTime" 500;
BA_ "GenMsgCycleTime" BO_ 1100 1000;
BA_ "GenMsgCycleTime" BO_ 1375 100;
BA_ "GenMsgCycleTime" BO_ 820 200;
BA_ "GenMsgCycleTime" BO_ 1103 1000;
BA_ "GenMsgCycleTime" BO_ 1098 100;
BA_ "GenMsgNrOfRepetition" BO_ 1369 3;
BA_ "GenMsgCycleTime" BO_ 1369 200;
BA_ "GenMsgCycleTime" BO_ 1099 1000;
BA_ "GenMsgNrOfRepetition" BO_ 1364 3;
BA_ "GenMsgCycleTime" BO_ 1364 0;
BA_ "GenMsgSendType" BO_ 1364 8;
BA_ "GenMsgNrOfRepetition" BO_ 1363 3;
BA_ "GenMsgCycleTime" BO_ 1363 200;
BA_ "GenMsgCycleTime" BO_ 1358 200;
BA_ "GenMsgCycleTime" BO_ 1117 200;
BA_ "GenMsgNrOfRepetition" BO_ 1116 3;
BA_ "GenMsgCycleTime" BO_ 1116 200;
BA_ "GenMsgNrOfRepetition" BO_ 16 3;
BA_ "GenMsgCycleTime" BO_ 16 0;
BA_ "GenMsgSendType" BO_ 16 8;
BA_ "GenMsgNrOfRepetition" BO_ 1359 3;
BA_ "GenMsgCycleTime" BO_ 1359 0;
BA_ "GenMsgSendType" BO_ 1359 8;
BA_ "GenMsgCycleTime" BO_ 1118 200;
BA_ "GenMsgCycleTime" BO_ 1354 1000;
BA_ "GenMsgCycleTime" BO_ 1115 100;
BA_ "GenMsgCycleTime" BO_ 1353 100;
BA_ "GenMsgCycleTime" BO_ 1346 100;
BA_ "GenMsgCycleTime" BO_ 1104 20;
BA_ "GenMsgCycleTime" BO_ 1344 200;
BA_ "GenMsgNrOfRepetition" BO_ 1345 3;
BA_ "GenMsgCycleTime" BO_ 1345 100;
BA_ "GenMsgCycleTime" BO_ 1405 200;
BA_ "GenMsgCycleTime" BO_ 1404 200;
BA_ "GenMsgCycleTime" BO_ 1407 100;
BA_ "GenMsgCycleTime" BO_ 1406 200;
BA_ "GenMsgNrOfRepetition" BO_ 1133 3;
BA_ "GenMsgCycleTime" BO_ 1133 200;
BA_ "GenMsgCycleTime" BO_ 1401 100;
BA_ "GenMsgCycleTime" BO_ 1400 100;
BA_ "GenMsgCycleTime" BO_ 1403 100;
BA_ "GenMsgCycleTime" BO_ 1402 100;
BA_ "GenMsgCycleTime" BO_ 1399 200;
BA_ "GenMsgCycleTime" BO_ 1398 200;
BA_ "GenMsgCycleTime" BO_ 1122 20;
BA_ "GenMsgCycleTime" BO_ 1392 100;
BA_ "GenMsgCycleTime" BO_ 1388 100;
BA_ "GenMsgCycleTime" BO_ 1148 100;
BA_ "GenMsgCycleTime" BO_ 1145 100;
BA_ "GenMsgCycleTime" BO_ 1144 100;
BA_ "GenMsgCycleTime" BO_ 1383 100;
BA_ "GenMsgCycleTime" BO_ 1377 100;
BA_ "GenMsgCycleTime" BO_ 1137 20;
BA_ "GenMsgCycleTime" BO_ 1378 0;
BA_ "GenMsgSendType" BO_ 1378 8;
BA_ "GenMsgCycleTime" BO_ 1032 200;
BA_ "GenMsgNrOfRepetition" BO_ 1307 3;
BA_ "GenMsgCycleTime" BO_ 1307 0;
BA_ "GenMsgSendType" BO_ 1307 8;
BA_ "GenMsgCycleTime" BO_ 1029 200;
BA_ "GenMsgCycleTime" BO_ 1030 200;
BA_ "GenSigStartValue" SG_ 1103 DATC_SwVer1 127;
BA_ "GenSigStartValue" SG_ 1103 DATC_SwVer2 127;
BA_ "GenSigStartValue" SG_ 1103 DATC_SwVer3 127;
BA_ "GenSigSendType" SG_ 1369 CF_Gway_MemoryP1Cmd 4;
BA_ "GenSigSendType" SG_ 1369 CF_Gway_MemoryP2Cmd 4;
BA_ "GenSigSendType" SG_ 1369 CF_Gway_PBackP1Cmd 4;
BA_ "GenSigSendType" SG_ 1369 CF_Gway_PBackP2Cmd 4;
BA_ "GenSigSendType" SG_ 1369 CF_Gway_StrgWhlHeatedState 4;
BA_ "GenSigSendType" SG_ 1369 CF_Gway_PBackStopCmd 4;
BA_ "GenSigSendType" SG_ 1369 CF_Gway_StaticBendLhAct 4;
BA_ "GenSigSendType" SG_ 1369 CF_Gway_StaticBendRhAct 4;
BA_ "GenSigSendType" SG_ 1369 CF_Gway_DrvWdwStat 4;
BA_ "GenSigSendType" SG_ 1369 CF_Gway_RLWdwState 4;
BA_ "GenSigSendType" SG_ 1369 CF_Gway_RRWdwState 4;
BA_ "GenSigSendType" SG_ 1369 CF_Gway_AstWdwStat 4;
BA_ "GenSigSendType" SG_ 1369 CF_Gway_MemoryEnable 4;
BA_ "GenSigSendType" SG_ 1369 CF_Gway_DrvUnlockState 4;
BA_ "GenSigSendType" SG_ 1369 CF_Gway_IMSBuzzer 4;
BA_ "GenSigSendType" SG_ 1369 C_HSWSSysStat 4;
BA_ "GenSigSendType" SG_ 1369 CF_Gway_WiperSwState 4;
BA_ "GenSigSendType" SG_ 1369 CF_Gway_HCIMSPBackCmd 4;
BA_ "GenSigSendType" SG_ 1369 CF_Gway_DrvSeatBeltIND 4;
BA_ "GenSigSendType" SG_ 1369 CF_Gway_AstSeatBeltIND 4;
BA_ "GenSigSendType" SG_ 1369 CF_Gway_RCSeatBeltIND 4;
BA_ "GenSigSendType" SG_ 1369 CF_Gway_RLSeatBeltIND 4;
BA_ "GenSigSendType" SG_ 1369 CF_Gway_RRSeatBeltIND 4;
BA_ "GenSigSendType" SG_ 1369 CF_Gway_RrWiperHighSw 4;
BA_ "GenSigSendType" SG_ 1369 CF_Gway_RrWiperLowSw 4;
BA_ "GenSigStartValue" SG_ 1369 CF_Gway_Navigation_On_Off 3;
BA_ "GenSigSendType" SG_ 1369 CF_Gway_Navigation_On_Off 4;
BA_ "GenSigSendType" SG_ 1369 CF_Gway_LanguageInfo 4;
BA_ "GenSigSendType" SG_ 1369 CF_Gway_Navi_On_Off 4;
BA_ "GenSigSendType" SG_ 1369 CF_Gway_WPCWarning 4;
BA_ "GenSigSendType" SG_ 1369 CF_Gway_RWPCWarning 4;
BA_ "GenSigSendType" SG_ 1369 CF_Gway_DedicatedDRLState 4;
BA_ "GenSigSendType" SG_ 1369 CF_Gway_SeatBeltWngBuz 4;
BA_ "GenSigStartValue" SG_ 1364 HU_DATC_DrTempSetC 255;
BA_ "GenSigSendType" SG_ 1364 HU_DATC_DrTempSetC 4;
BA_ "GenSigStartValue" SG_ 1364 HU_DATC_DrTempSetF 255;
BA_ "GenSigSendType" SG_ 1364 HU_DATC_DrTempSetF 4;
BA_ "GenSigStartValue" SG_ 1364 HU_MTC_RlTempLevelReq 15;
BA_ "GenSigSendType" SG_ 1364 HU_MTC_RlTempLevelReq 4;
BA_ "GenSigStartValue" SG_ 1364 HU_DATC_RlBlowerUpDn 3;
BA_ "GenSigSendType" SG_ 1364 HU_DATC_RlBlowerUpDn 4;
BA_ "GenSigSendType" SG_ 1364 CF_Datc_DefLogic_USM_Set 4;
BA_ "GenSigSendType" SG_ 1364 CF_Datc_AutoFresh_USM_Set 4;
BA_ "GenSigSendType" SG_ 1364 DATC_AutoArClnUSMSet 4;
BA_ "GenSigStartValue" SG_ 1364 HU_DATC_SyncSet 3;
BA_ "GenSigSendType" SG_ 1364 HU_DATC_SyncSet 4;
BA_ "GenSigStartValue" SG_ 1364 C_DATC_DTC_Mode 3;
BA_ "GenSigSendType" SG_ 1364 C_DATC_DTC_Mode 4;
BA_ "GenSigStartValue" SG_ 1364 HU_DATC_RlTempSetC 255;
BA_ "GenSigSendType" SG_ 1364 HU_DATC_RlTempSetC 4;
BA_ "GenSigStartValue" SG_ 1364 HU_DATC_RlTempSetF 255;
BA_ "GenSigSendType" SG_ 1364 HU_DATC_RlTempSetF 4;
BA_ "SignalCategory" SG_ 1363 CF_ChaDrSwFrt 10;
BA_ "GenSigSendType" SG_ 1363 CF_ChaDrSwFrt 4;
BA_ "SignalCategory" SG_ 1363 CF_ChaDrSwRr 10;
BA_ "GenSigSendType" SG_ 1363 CF_ChaDrSwRr 4;
BA_ "GenSigSendType" SG_ 1363 C_BAlarmState 4;
BA_ "GenSigSendType" SG_ 1363 CF_Gway_AutoLightValue 4;
BA_ "GenSigSendType" SG_ 1363 CF_Gway_RRDrSw 4;
BA_ "GenSigSendType" SG_ 1363 CF_Gway_RLDrSw 4;
BA_ "GenSigSendType" SG_ 1363 CF_Gway_IntTailAct 4;
BA_ "GenSigSendType" SG_ 1363 CF_Gway_SMKRKECmd 4;
BA_ "GenSigStartValue" SG_ 1363 CF_Gway_SJBDeliveryMode 1;
BA_ "GenSigSendType" SG_ 1363 CF_Gway_SJBDeliveryMode 4;
BA_ "GenSigStartValue" SG_ 1358 NV_EstDist_F 15;
BA_ "GenSigStartValue" SG_ 1358 NV_EstDist_Unit 15;
BA_ "GenSigStartValue" SG_ 1358 NV_EstDist_I 65535;
BA_ "GenSigStartValue" SG_ 1117 CR_Tmu_DrvDistance1 1023;
BA_ "GenSigStartValue" SG_ 1117 CR_Tmu_DrvDistance2 1023;
BA_ "GenSigStartValue" SG_ 1117 CR_Tmu_DrvDistance3 1023;
BA_ "GenSigStartValue" SG_ 1117 CR_Tmu_DrvDistance4 1023;
BA_ "GenSigStartValue" SG_ 1117 CR_Tmu_DrvDistance5 1023;
BA_ "GenSigStartValue" SG_ 1117 CR_Tmu_DrvDistance6 1023;
BA_ "GenSigSendType" SG_ 1116 CR_Datc_BatteryCompPwrCon_W 4;
BA_ "GenSigSendType" SG_ 1116 DATC_RrDefSw 4;
BA_ "GenSigSendType" SG_ 1116 C_SteeringWheelHeaterSW 4;
BA_ "GenSigSendType" SG_ 1116 CR_Datc_DRSeatWheel_USM_State 4;
BA_ "GenSigSendType" SG_ 1116 CR_Datc_DRSeatHeat_USM_State 4;
BA_ "GenSigSendType" SG_ 1116 DATC_WdwClsReq 4;
BA_ "GenSigSendType" SG_ 1116 DATC_ArClnSmblTyp 4;
BA_ "GenSigSendType" SG_ 1116 DATC_ArClnStepClr 4;
BA_ "GenSigSendType" SG_ 1116 DATC_ArClnSysOSD 4;
BA_ "GenSigSendType" SG_ 16 CF_Acu_CshAct 4;
BA_ "GenSigSendType" SG_ 16 ACU_CrshInfo 4;
BA_ "GenSigSendType" SG_ 16 Acu_TypOfCrash 4;
BA_ "GenSigStartValue" SG_ 1359 HU_DATC_DrTempUpDn 3;
BA_ "GenSigSendType" SG_ 1359 HU_DATC_DrTempUpDn 4;
BA_ "GenSigStartValue" SG_ 1359 HU_DATC_PsTempUpDn 3;
BA_ "GenSigSendType" SG_ 1359 HU_DATC_PsTempUpDn 4;
BA_ "GenSigStartValue" SG_ 1359 HU_DATC_RLTempUpDn 3;
BA_ "GenSigSendType" SG_ 1359 HU_DATC_RLTempUpDn 4;
BA_ "GenSigStartValue" SG_ 1359 HU_DATC_RrTempUpDn 3;
BA_ "GenSigSendType" SG_ 1359 HU_DATC_RrTempUpDn 4;
BA_ "GenSigStartValue" SG_ 1359 HU_DATC_MainBlower 15;
BA_ "GenSigSendType" SG_ 1359 HU_DATC_MainBlower 4;
BA_ "GenSigSendType" SG_ 1359 HU_DATC_RearBlower 4;
BA_ "GenSigSendType" SG_ 1359 HU_DATCRearPsModeSet 4;
BA_ "GenSigStartValue" SG_ 1359 HU_DATC_FrontModeSet 15;
BA_ "GenSigSendType" SG_ 1359 HU_DATC_FrontModeSet 4;
BA_ "GenSigSendType" SG_ 1359 HU_DATC_RearModeSet 4;
BA_ "GenSigStartValue" SG_ 1359 HU_DATC_AutoSet 3;
BA_ "GenSigSendType" SG_ 1359 HU_DATC_AutoSet 4;
BA_ "GenSigStartValue" SG_ 1359 HU_DATC_OffReq 3;
BA_ "GenSigSendType" SG_ 1359 HU_DATC_OffReq 4;
BA_ "GenSigStartValue" SG_ 1359 HU_DATC_IntakeSet 3;
BA_ "GenSigSendType" SG_ 1359 HU_DATC_IntakeSet 4;
BA_ "GenSigStartValue" SG_ 1359 HU_DATC_RearOnOffSet 3;
BA_ "GenSigSendType" SG_ 1359 HU_DATC_RearOnOffSet 4;
BA_ "GenSigStartValue" SG_ 1359 HU_DATC_AcSet 3;
BA_ "GenSigSendType" SG_ 1359 HU_DATC_AcSet 4;
BA_ "GenSigStartValue" SG_ 1359 HU_DATC_FrontDefog 3;
BA_ "GenSigSendType" SG_ 1359 HU_DATC_FrontDefog 4;
BA_ "GenSigStartValue" SG_ 1359 HU_DATC_RearDefog 3;
BA_ "GenSigSendType" SG_ 1359 HU_DATC_RearDefog 4;
BA_ "GenSigStartValue" SG_ 1359 HU_DATC_CO2Set 3;
BA_ "GenSigSendType" SG_ 1359 HU_DATC_CO2Set 4;
BA_ "GenSigSendType" SG_ 1359 DATC_SmartVentOnOffSet 4;
BA_ "GenSigStartValue" SG_ 1359 DATC_ADSOnOffSet 3;
BA_ "GenSigSendType" SG_ 1359 DATC_ADSOnOffSet 4;
BA_ "GenSigSendType" SG_ 1359 HU_Datc_RearAutoDisp 4;
BA_ "GenSigSendType" SG_ 1359 HU_Datc_RearOffDisp 4;
BA_ "GenSigStartValue" SG_ 1359 HU_DATC_MainBlowerUpDn 3;
BA_ "GenSigSendType" SG_ 1359 HU_DATC_MainBlowerUpDn 4;
BA_ "GenSigStartValue" SG_ 1359 HU_DATC_AirCleaningSet 3;
BA_ "GenSigSendType" SG_ 1359 HU_DATC_AirCleaningSet 4;
BA_ "GenSigStartValue" SG_ 1118 CR_Tmu_DrvDistance7 1023;
BA_ "GenSigStartValue" SG_ 1118 CR_Tmu_DrvDistance8 1023;
BA_ "GenSigStartValue" SG_ 1118 CR_Tmu_DrvDistance9 1023;
BA_ "GenSigStartValue" SG_ 1118 CR_Tmu_DrvDistance10 1023;
BA_ "GenSigStartValue" SG_ 1353 BAT_SNSR_I 65535;
BA_ "GenSigStartValue" SG_ 1353 BAT_SNSR_V 16383;
BA_ "GenSigStartValue" SG_ 1353 BAT_SNSR_Temp 511;
BA_ "GenSigStartValue" SG_ 1353 BAT_SNSR_State 1;
BA_ "GenSigStartValue" SG_ 1353 BAT_SOH 127;
BA_ "GenSigStartValue" SG_ 1353 BAT_SNSR_Invalid 1;
BA_ "GenSigStartValue" SG_ 1353 BAT_SOF 127;
BA_ "GenSigStartValue" SG_ 1353 BAT_SNSR_Error 1;
BA_ "GenSigSendType" SG_ 1345 CF_Gway_IGNSw 4;
BA_ "GenSigSendType" SG_ 1345 CF_Gway_RKECmd 4;
BA_ "GenSigSendType" SG_ 1345 CF_Gway_DrvKeyLockSw 4;
BA_ "GenSigSendType" SG_ 1345 CF_Gway_DrvKeyUnlockSw 4;
BA_ "GenSigSendType" SG_ 1345 CF_Gway_DrvDrSw 4;
BA_ "GenSigSendType" SG_ 1345 CF_Gway_DrvSeatBeltSw 4;
BA_ "GenSigSendType" SG_ 1345 CF_Gway_TrunkTgSw 4;
BA_ "GenSigSendType" SG_ 1345 CF_Gway_AstSeatBeltSw 4;
BA_ "GenSigSendType" SG_ 1345 CF_Gway_SMKOption 4;
BA_ "GenSigSendType" SG_ 1345 CF_Gway_HoodSw 4;
BA_ "GenSigSendType" SG_ 1345 CF_Gway_TurnSigLh 4;
BA_ "GenSigSendType" SG_ 1345 CF_Gway_WiperIntT 4;
BA_ "GenSigSendType" SG_ 1345 CF_Gway_WiperIntSw 4;
BA_ "GenSigSendType" SG_ 1345 CF_Gway_WiperLowSw 4;
BA_ "GenSigSendType" SG_ 1345 CF_Gway_WiperHighSw 4;
BA_ "GenSigSendType" SG_ 1345 CF_Gway_WiperAutoSw 4;
BA_ "GenSigSendType" SG_ 1345 CF_Gway_RainSnsState 4;
BA_ "GenSigSendType" SG_ 1345 CF_Gway_HeadLampLow 4;
BA_ "GenSigSendType" SG_ 1345 CF_Gway_HeadLampHigh 4;
BA_ "GenSigSendType" SG_ 1345 CF_Gway_HazardSw 4;
BA_ "GenSigSendType" SG_ 1345 CF_Gway_AstDrSw 4;
BA_ "GenSigSendType" SG_ 1345 CF_Gway_DefoggerRly 4;
BA_ "GenSigSendType" SG_ 1345 CF_Gway_ALightStat 4;
BA_ "GenSigSendType" SG_ 1345 CF_Gway_LightSwState 4;
BA_ "GenSigSendType" SG_ 1345 CF_Gway_Frt_Fog_Act 4;
BA_ "GenSigSendType" SG_ 1345 CF_Gway_TSigLHSw 4;
BA_ "GenSigSendType" SG_ 1345 CF_Gway_TSigRHSw 4;
BA_ "GenSigSendType" SG_ 1345 CF_Gway_DriveTypeOption 4;
BA_ "GenSigSendType" SG_ 1345 CF_Gway_StarterRlyState 4;
BA_ "GenSigSendType" SG_ 1345 CF_Gway_PassiveAccessLock 4;
BA_ "GenSigSendType" SG_ 1345 CF_Gway_RearFogAct 4;
BA_ "GenSigSendType" SG_ 1345 CF_Gway_PassiveAccessUnlock 4;
BA_ "GenSigSendType" SG_ 1345 CF_Gway_PassingSW 4;
BA_ "GenSigSendType" SG_ 1345 CF_Gway_HBAControlMode 4;
BA_ "GenSigSendType" SG_ 1345 CF_Gway_HLpHighSw 4;
BA_ "GenSigSendType" SG_ 1345 CF_Gway_InhibitRMT 4;
BA_ "GenSigSendType" SG_ 1345 CF_Gway_Ign1 4;
BA_ "GenSigSendType" SG_ 1345 CF_Gway_Ign2 4;
BA_ "GenSigSendType" SG_ 1345 CF_Gway_ParkBrakeSw 4;
BA_ "GenSigSendType" SG_ 1345 CF_Gway_TurnSigRh 4;
BA_ "GenSigSendType" SG_ 1133 CF_Ctm_TrailerAct 4;
BA_ "GenSigSendType" SG_ 1133 CF_Ctm_RearfogAct 4;
BA_ "GenSigStartValue" SG_ 512 CF_Vcu_GarSelDisp 9;
BA_ "GenSigStartValue" SG_ 514 CF_Vcu_MCUAntiJerkInh 1;
BA_ "GenSigStartValue" SG_ 1402 CF_VCU_AuxBattChgUsmSts 2;
BA_ "GenSigStartValue" SG_ 1122 SCC_ObjStatus 3;
BA_ "GenSigStartValue" SG_ 1122 SCC_ObjDist 2047;
BA_ "GenSigStartValue" SG_ 1122 SCC_ObjRelSpd 4095;
BA_ "GenSigStartValue" SG_ 1122 SCC_ObjLatPos 511;
BA_ "GenSigStartValue" SG_ 1145 BS2_CNOM 255;
BA_ "GenSigStartValue" SG_ 1145 BS2_OCV 4095;
BA_ "GenSigStartValue" SG_ 1145 BS2_FSOC 1;
BA_ "GenSigStartValue" SG_ 1145 BS2_FSOH 1;
BA_ "GenSigStartValue" SG_ 1145 BS2_FSOF 1;
BA_ "GenSigStartValue" SG_ 1145 BS2_FQSTAT 1;
BA_ "GenSigStartValue" SG_ 1145 BAT_SOH 255;
BA_ "GenSigStartValue" SG_ 1145 BAT_SOF 255;
BA_ "GenSigStartValue" SG_ 1144 BS1_VBAT 16383;
BA_ "GenSigStartValue" SG_ 1144 BS1_TBAT 511;
BA_ "GenSigStartValue" SG_ 1144 BS1_BSInvalidFlag 1;
BA_ "GenSigStartValue" SG_ 1144 BS1_ErrorResp 1;
BA_ "GenSigStartValue" SG_ 1137 CLU11_STS 1;
BA_ "GenSigStartValue" SG_ 1137 CLU12_STS 1;
BA_ "GenSigStartValue" SG_ 1137 CLU14_STS 1;
BA_ "GenSigStartValue" SG_ 1137 EPB11_STS 1;
BA_ "GenSigStartValue" SG_ 1137 SAS11_STS 1;
BA_ "GenSigStartValue" SG_ 1137 ESP11_STS 1;
BA_ "GenSigStartValue" SG_ 1137 AHB1_STS 1;
BA_ "GenSigStartValue" SG_ 1137 CLU13_STS 1;
BA_ "GenSigStartValue" SG_ 1378 HU_EV_WinterMode 3;
BA_ "GenSigSendType" SG_ 1378 HU_EV_WinterMode 3;
BA_ "GenSigStartValue" SG_ 1378 HU_TgSoc_ScChg_Set 255;
BA_ "GenSigSendType" SG_ 1378 HU_TgSoc_ScChg_Set 3;
BA_ "GenSigStartValue" SG_ 1378 HU_TgSoc_QcChg_Set 255;
BA_ "GenSigSendType" SG_ 1378 HU_TgSoc_QcChg_Set 3;
BA_ "GenSigStartValue" SG_ 1378 HU_TgSoc_GPSChg_Set 255;
BA_ "GenSigSendType" SG_ 1378 HU_TgSoc_GPSChg_Set 3;
BA_ "GenSigSendType" SG_ 1307 CF_Clu_TirePressUnitNValueSet 4;
BA_ "GenSigSendType" SG_ 1307 CF_Clu_FuelGuideReset 4;
BA_ "GenSigSendType" SG_ 1307 CF_Clu_ECoastingNvalueSet 4;
BA_ "GenSigSendType" SG_ 1307 CF_Clu_USMReset 4;
BA_ "GenSigSendType" SG_ 1307 CF_Clu_ECoastWarnNValueSet 4;
BA_ "GenSigSendType" SG_ 1307 CF_Clu_AuxBatChargeNValueSet 4;
BA_ "GenSigSendType" SG_ 1307 CF_Clu_ECoastCtrlNValueSet 4;
BA_ "GenSigStartValue" SG_ 339 TQI_TCS 255;
BA_ "GenSigStartValue" SG_ 339 TQI_SLW_TCS 255;
BA_REL_ "GenSigTimeoutTime" BU_SG_REL_ CGW SG_ 1100 CF_Bms_Nev_TempDiffWrn 10000;
BA_REL_ "GenSigTimeoutTime" BU_SG_REL_ NEMS SG_ 1100 CF_Bms_Nev_TempDiffWrn 10000;
BA_REL_ "GenSigTimeoutTime" BU_SG_REL_ CGW SG_ 1100 CF_Bms_Nev_OverTempWrn 10000;
BA_REL_ "GenSigTimeoutTime" BU_SG_REL_ NEMS SG_ 1100 CF_Bms_Nev_OverTempWrn 10000;
BA_REL_ "GenSigTimeoutTime" BU_SG_REL_ CGW SG_ 1100 CF_Bms_Nev_DeviceOverVoltWrn 10000;
BA_REL_ "GenSigTimeoutTime" BU_SG_REL_ NEMS SG_ 1100 CF_Bms_Nev_DeviceOverVoltWrn 10000;
BA_REL_ "GenSigTimeoutTime" BU_SG_REL_ CGW SG_ 1100 CF_Bms_Nev_DeviceUnderVoltWrn 10000;
BA_REL_ "GenSigTimeoutTime" BU_SG_REL_ NEMS SG_ 1100 CF_Bms_Nev_DeviceUnderVoltWrn 10000;
BA_REL_ "GenSigTimeoutTime" BU_SG_REL_ CGW SG_ 1100 CF_Bms_Nev_SocLowWrn 10000;
BA_REL_ "GenSigTimeoutTime" BU_SG_REL_ NEMS SG_ 1100 CF_Bms_Nev_SocLowWrn 10000;
BA_REL_ "GenSigTimeoutTime" BU_SG_REL_ CGW SG_ 1100 CF_Bms_Nev_CellOverVoltWrn 10000;
BA_REL_ "GenSigTimeoutTime" BU_SG_REL_ NEMS SG_ 1100 CF_Bms_Nev_CellOverVoltWrn 10000;
BA_REL_ "GenSigTimeoutTime" BU_SG_REL_ CGW SG_ 1100 CF_Bms_Nev_CellUnderVoltWrn 10000;
BA_REL_ "GenSigTimeoutTime" BU_SG_REL_ NEMS SG_ 1100 CF_Bms_Nev_CellUnderVoltWrn 10000;
BA_REL_ "GenSigTimeoutTime" BU_SG_REL_ CGW SG_ 1100 CF_Bms_Nev_SocHighWrn 10000;
BA_REL_ "GenSigTimeoutTime" BU_SG_REL_ NEMS SG_ 1100 CF_Bms_Nev_SocHighWrn 10000;
BA_REL_ "GenSigTimeoutTime" BU_SG_REL_ CGW SG_ 1100 CF_Bms_Nev_SocAbnormalWrn 10000;
BA_REL_ "GenSigTimeoutTime" BU_SG_REL_ NEMS SG_ 1100 CF_Bms_Nev_SocAbnormalWrn 10000;
BA_REL_ "GenSigTimeoutTime" BU_SG_REL_ CGW SG_ 1100 CF_Bms_Nev_SysUnmatchWrn 10000;
BA_REL_ "GenSigTimeoutTime" BU_SG_REL_ NEMS SG_ 1100 CF_Bms_Nev_SysUnmatchWrn 10000;
BA_REL_ "GenSigTimeoutTime" BU_SG_REL_ CGW SG_ 1100 CF_Bms_Nev_CellVoltDiffWrn 10000;
BA_REL_ "GenSigTimeoutTime" BU_SG_REL_ NEMS SG_ 1100 CF_Bms_Nev_CellVoltDiffWrn 10000;
BA_REL_ "GenSigTimeoutTime" BU_SG_REL_ CGW SG_ 1100 CF_Bms_Nev_IsolWrn 10000;
BA_REL_ "GenSigTimeoutTime" BU_SG_REL_ NEMS SG_ 1100 CF_Bms_Nev_IsolWrn 10000;
BA_REL_ "GenSigTimeoutTime" BU_SG_REL_ CGW SG_ 1100 CF_Bms_Nev_InterlockWrn 10000;
BA_REL_ "GenSigTimeoutTime" BU_SG_REL_ NEMS SG_ 1100 CF_Bms_Nev_InterlockWrn 10000;
BA_REL_ "GenSigTimeoutTime" BU_SG_REL_ CGW SG_ 1100 CF_Bms_Nev_OverChaWrn 10000;
BA_REL_ "GenSigTimeoutTime" BU_SG_REL_ NEMS SG_ 1100 CF_Bms_Nev_OverChaWrn 10000;
BA_REL_ "GenSigTimeoutTime" BU_SG_REL_ CGW SG_ 1100 CR_Bms_Nev_DiagNum 10000;
BA_REL_ "GenSigTimeoutTime" BU_SG_REL_ NEMS SG_ 1100 CR_Bms_Nev_DiagNum 10000;
BA_REL_ "GenSigTimeoutTime" BU_SG_REL_ CGW SG_ 1100 CR_Bms_Nev_DiagList 10000;
BA_REL_ "GenSigTimeoutTime" BU_SG_REL_ NEMS SG_ 1100 CR_Bms_Nev_DiagList 10000;
BA_REL_ "GenSigTimeoutTime" BU_SG_REL_ ACU SG_ 820 MCB_CtlSta 0;
BA_REL_ "GenSigTimeoutTime" BU_SG_REL_ vBDM SG_ 820 MCB_CtlSta 0;
BA_REL_ "GenSigTimeoutTime" BU_SG_REL_ ACU SG_ 820 MCB_DefSta 0;
BA_REL_ "GenSigTimeoutTime" BU_SG_REL_ vBDM SG_ 820 MCB_DefSta 0;
BA_REL_ "GenSigTimeoutTime" BU_SG_REL_ CGW SG_ 1103 DATC_SwVer1 5000;
BA_REL_ "GenSigTimeoutTime" BU_SG_REL_ CGW SG_ 1103 DATC_SwVer2 5000;
BA_REL_ "GenSigTimeoutTime" BU_SG_REL_ CGW SG_ 1103 DATC_SwVer3 5000;
BA_REL_ "GenSigTimeoutTime" BU_SG_REL_ CGW SG_ 1103 CF_Datc_Type2 5000;
BA_REL_ "GenSigTimeoutTime" BU_SG_REL_ Dummy SG_ 819 CR_Vcu_WhlRgnTqMax_Nm 0;
BA_REL_ "GenSigTimeoutTime" BU_SG_REL_ iBAU SG_ 819 CR_Vcu_WhlRgnTqMax_Nm 0;
BA_REL_ "GenSigTimeoutTime" BU_SG_REL_ CGW SG_ 1098 CF_Evp2_Stat 1500;
BA_REL_ "GenSigTimeoutTime" BU_SG_REL_ EVP1 SG_ 1098 CF_Evp2_Stat 1500;
BA_REL_ "GenSigTimeoutTime" BU_SG_REL_ iBAU SG_ 1098 CF_Evp2_Stat 1500;
BA_REL_ "GenSigTimeoutTime" BU_SG_REL_ EVP1 SG_ 1098 CF_Evp2_DefMode 1500;
BA_REL_ "GenSigTimeoutTime" BU_SG_REL_ EVP1 SG_ 1098 CF_Evp2_V_level 1500;
BA_REL_ "GenSigTimeoutTime" BU_SG_REL_ EVP1 SG_ 1098 CF_Evp2_RunCount 1500;
BA_REL_ "GenSigTimeoutTime" BU_SG_REL_ EVP1 SG_ 1098 CF_Evp2_RunChk 1500;
BA_REL_ "GenSigTimeoutTime" BU_SG_REL_ iBAU SG_ 1098 CF_Evp2_RunChk 1500;
BA_REL_ "GenSigTimeoutTime" BU_SG_REL_ Dummy SG_ 1369 CF_Gway_MemoryP1Cmd 1500;
BA_REL_ "GenSigTimeoutTime" BU_SG_REL_ Dummy SG_ 1369 CF_Gway_MemoryP2Cmd 1500;
BA_REL_ "GenSigTimeoutTime" BU_SG_REL_ Dummy SG_ 1369 CF_Gway_PBackP1Cmd 1500;
BA_REL_ "GenSigTimeoutTime" BU_SG_REL_ Dummy SG_ 1369 CF_Gway_PBackP2Cmd 1500;
BA_REL_ "GenSigTimeoutTime" BU_SG_REL_ Dummy SG_ 1369 CF_Gway_StrgWhlHeatedState 1500;
BA_REL_ "GenSigTimeoutTime" BU_SG_REL_ Dummy SG_ 1369 CF_Gway_PBackStopCmd 1500;
BA_REL_ "GenSigTimeoutTime" BU_SG_REL_ Dummy SG_ 1369 CF_Gway_StaticBendLhAct 1500;
BA_REL_ "GenSigTimeoutTime" BU_SG_REL_ Dummy SG_ 1369 CF_Gway_StaticBendRhAct 1500;
BA_REL_ "GenSigTimeoutTime" BU_SG_REL_ Dummy SG_ 1369 CF_Gway_DrvWdwStat 1500;
BA_REL_ "GenSigTimeoutTime" BU_SG_REL_ Dummy SG_ 1369 CF_Gway_RLWdwState 1500;
BA_REL_ "GenSigTimeoutTime" BU_SG_REL_ Dummy SG_ 1369 CF_Gway_RRWdwState 1500;
BA_REL_ "GenSigTimeoutTime" BU_SG_REL_ Dummy SG_ 1369 CF_Gway_AstWdwStat 1500;
BA_REL_ "GenSigTimeoutTime" BU_SG_REL_ Dummy SG_ 1369 CF_Gway_MemoryEnable 1500;
BA_REL_ "GenSigTimeoutTime" BU_SG_REL_ Dummy SG_ 1369 CF_Gway_DrvUnlockState 1500;
BA_REL_ "GenSigTimeoutTime" BU_SG_REL_ Dummy SG_ 1369 CF_Gway_IMSBuzzer 1500;
BA_REL_ "GenSigTimeoutTime" BU_SG_REL_ Dummy SG_ 1369 C_HSWSSysStat 1500;
BA_REL_ "GenSigTimeoutTime" BU_SG_REL_ Dummy SG_ 1369 CF_Gway_WiperSwState 1500;
BA_REL_ "GenSigTimeoutTime" BU_SG_REL_ Dummy SG_ 1369 CF_Gway_HCIMSPBackCmd 1500;
BA_REL_ "GenSigTimeoutTime" BU_SG_REL_ Dummy SG_ 1369 CF_Gway_DrvSeatBeltIND 1500;
BA_REL_ "GenSigTimeoutTime" BU_SG_REL_ Dummy SG_ 1369 CF_Gway_AstSeatBeltIND 1500;
BA_REL_ "GenSigTimeoutTime" BU_SG_REL_ Dummy SG_ 1369 CF_Gway_RCSeatBeltIND 1500;
BA_REL_ "GenSigTimeoutTime" BU_SG_REL_ Dummy SG_ 1369 CF_Gway_RLSeatBeltIND 1500;
BA_REL_ "GenSigTimeoutTime" BU_SG_REL_ Dummy SG_ 1369 CF_Gway_RRSeatBeltIND 1500;
BA_REL_ "GenSigTimeoutTime" BU_SG_REL_ Dummy SG_ 1369 CF_Gway_RrWiperHighSw 1500;
BA_REL_ "GenSigTimeoutTime" BU_SG_REL_ Dummy SG_ 1369 CF_Gway_RrWiperLowSw 1500;
BA_REL_ "GenSigTimeoutTime" BU_SG_REL_ Dummy SG_ 1369 CF_Gway_Navigation_On_Off 1500;
BA_REL_ "GenSigTimeoutTime" BU_SG_REL_ Dummy SG_ 1369 CF_Gway_LanguageInfo 1500;
BA_REL_ "GenSigTimeoutTime" BU_SG_REL_ Dummy SG_ 1369 CF_Gway_Navi_On_Off 1500;
BA_REL_ "GenSigTimeoutTime" BU_SG_REL_ Dummy SG_ 1369 CF_Gway_WPCWarning 1500;
BA_REL_ "GenSigTimeoutTime" BU_SG_REL_ Dummy SG_ 1369 CF_Gway_RWPCWarning 1500;
BA_REL_ "GenSigTimeoutTime" BU_SG_REL_ Dummy SG_ 1369 CF_Gway_DedicatedDRLState 1500;
BA_REL_ "GenSigTimeoutTime" BU_SG_REL_ Dummy SG_ 1369 CF_Gway_SeatBeltWngBuz 1500;
BA_REL_ "GenSigTimeoutTime" BU_SG_REL_ CGW SG_ 1099 CF_Bms_Nev_SubSystemNum 10000;
BA_REL_ "GenSigTimeoutTime" BU_SG_REL_ NEMS SG_ 1099 CF_Bms_Nev_SubSystemNum 10000;
BA_REL_ "GenSigTimeoutTime" BU_SG_REL_ CGW SG_ 1099 CR_Bms_Nev_ChargeStatus 10000;
BA_REL_ "GenSigTimeoutTime" BU_SG_REL_ NEMS SG_ 1099 CR_Bms_Nev_ChargeStatus 10000;
BA_REL_ "GenSigTimeoutTime" BU_SG_REL_ CGW SG_ 1099 CR_Bms_Nev_BatCurrent 10000;
BA_REL_ "GenSigTimeoutTime" BU_SG_REL_ NEMS SG_ 1099 CR_Bms_Nev_BatCurrent 10000;
BA_REL_ "GenSigTimeoutTime" BU_SG_REL_ CGW SG_ 1099 CR_Bms_Nev_Soc 10000;
BA_REL_ "GenSigTimeoutTime" BU_SG_REL_ NEMS SG_ 1099 CR_Bms_Nev_Soc 10000;
BA_REL_ "GenSigTimeoutTime" BU_SG_REL_ CGW SG_ 1099 CR_Bms_Nev_IsolRes 10000;
BA_REL_ "GenSigTimeoutTime" BU_SG_REL_ NEMS SG_ 1099 CR_Bms_Nev_IsolRes 10000;
BA_REL_ "GenSigTimeoutTime" BU_SG_REL_ DATC SG_ 1364 HU_DATC_DrTempSetC 0;
BA_REL_ "GenSigTimeoutTime" BU_SG_REL_ DATC SG_ 1364 HU_DATC_DrTempSetF 0;
BA_REL_ "GenSigTimeoutTime" BU_SG_REL_ DATC SG_ 1364 HU_MTC_RlTempLevelReq 0;
BA_REL_ "GenSigTimeoutTime" BU_SG_REL_ DATC SG_ 1364 HU_DATC_RlBlowerUpDn 0;
BA_REL_ "GenSigTimeoutTime" BU_SG_REL_ DATC SG_ 1364 CF_Datc_DefLogic_USM_Set 0;
BA_REL_ "GenSigTimeoutTime" BU_SG_REL_ DATC SG_ 1364 CF_Datc_AutoFresh_USM_Set 0;
BA_REL_ "GenSigTimeoutTime" BU_SG_REL_ DATC SG_ 1364 DATC_AutoArClnUSMSet 0;
BA_REL_ "GenSigTimeoutTime" BU_SG_REL_ DATC SG_ 1364 HU_DATC_SyncSet 0;
BA_REL_ "GenSigTimeoutTime" BU_SG_REL_ DATC SG_ 1364 C_DATC_DTC_Mode 0;
BA_REL_ "GenSigTimeoutTime" BU_SG_REL_ DATC SG_ 1364 HU_DATC_RlTempSetC 0;
BA_REL_ "GenSigTimeoutTime" BU_SG_REL_ DATC SG_ 1364 HU_DATC_RlTempSetF 0;
BA_REL_ "GenSigTimeoutTime" BU_SG_REL_ CDM SG_ 1363 CF_ChaDrSwFrt 1500;
BA_REL_ "GenSigTimeoutTime" BU_SG_REL_ VCU SG_ 1363 CF_ChaDrSwFrt 1500;
BA_REL_ "GenSigTimeoutTime" BU_SG_REL_ CDM SG_ 1363 CF_ChaDrSwRr 1500;
BA_REL_ "GenSigTimeoutTime" BU_SG_REL_ VCU SG_ 1363 CF_ChaDrSwRr 1500;
BA_REL_ "GenSigTimeoutTime" BU_SG_REL_ TMU SG_ 1363 C_BAlarmState 1000;
BA_REL_ "GenSigTimeoutTime" BU_SG_REL_ VCU SG_ 1363 C_BAlarmState 1000;
BA_REL_ "GenSigTimeoutTime" BU_SG_REL_ DATC SG_ 1363 CF_Gway_AutoLightValue 1500;
BA_REL_ "GenSigTimeoutTime" BU_SG_REL_ BMS SG_ 1363 CF_Gway_RRDrSw 1000;
BA_REL_ "GenSigTimeoutTime" BU_SG_REL_ vBDM SG_ 1363 CF_Gway_RRDrSw 1000;
BA_REL_ "GenSigTimeoutTime" BU_SG_REL_ BMS SG_ 1363 CF_Gway_RLDrSw 1000;
BA_REL_ "GenSigTimeoutTime" BU_SG_REL_ CLU SG_ 1363 CF_Gway_IntTailAct 1000;
BA_REL_ "GenSigTimeoutTime" BU_SG_REL_ LVR SG_ 1363 CF_Gway_IntTailAct 1000;
BA_REL_ "GenSigTimeoutTime" BU_SG_REL_ VESS SG_ 1363 CF_Gway_IntTailAct 1000;
BA_REL_ "GenSigTimeoutTime" BU_SG_REL_ LVR SG_ 1363 CF_Gway_SMKRKECmd 1000;
BA_REL_ "GenSigTimeoutTime" BU_SG_REL_ H_U SG_ 1363 CF_Gway_SJBDeliveryMode 1000;
BA_REL_ "GenSigTimeoutTime" BU_SG_REL_ LDC SG_ 1363 CF_Gway_SJBDeliveryMode 1000;
BA_REL_ "GenSigTimeoutTime" BU_SG_REL_ TMU SG_ 1363 CF_Gway_SJBDeliveryMode 1000;
BA_REL_ "GenSigTimeoutTime" BU_SG_REL_ VCU SG_ 1358 NV_EstDist_F 2000;
BA_REL_ "GenSigTimeoutTime" BU_SG_REL_ VCU SG_ 1358 NV_EstDist_Unit 2000;
BA_REL_ "GenSigTimeoutTime" BU_SG_REL_ VCU SG_ 1358 NV_EstDist_I 2000;
BA_REL_ "GenSigTimeoutTime" BU_SG_REL_ VCU SG_ 1117 CR_Tmu_DrvDistance1 2000;
BA_REL_ "GenSigTimeoutTime" BU_SG_REL_ VCU SG_ 1117 CR_Tmu_DrvDistance2 2000;
BA_REL_ "GenSigTimeoutTime" BU_SG_REL_ VCU SG_ 1117 CR_Tmu_DrvDistance3 2000;
BA_REL_ "GenSigTimeoutTime" BU_SG_REL_ VCU SG_ 1117 CR_Tmu_DrvDistance4 2000;
BA_REL_ "GenSigTimeoutTime" BU_SG_REL_ VCU SG_ 1117 CR_Tmu_DrvDistance5 2000;
BA_REL_ "GenSigTimeoutTime" BU_SG_REL_ VCU SG_ 1117 CR_Tmu_DrvDistance6 2000;
BA_REL_ "GenSigTimeoutTime" BU_SG_REL_ CGW SG_ 1116 CR_Datc_BatteryCompPwrCon_W 2000;
BA_REL_ "GenSigTimeoutTime" BU_SG_REL_ TMU SG_ 1116 CR_Datc_BatteryCompPwrCon_W 2000;
BA_REL_ "GenSigTimeoutTime" BU_SG_REL_ VCU SG_ 1116 CR_Datc_BatteryCompPwrCon_W 2000;
BA_REL_ "GenSigTimeoutTime" BU_SG_REL_ CGW SG_ 1116 DATC_RrDefSw 1500;
BA_REL_ "GenSigTimeoutTime" BU_SG_REL_ CGW SG_ 1116 C_SteeringWheelHeaterSW 15000;
BA_REL_ "GenSigTimeoutTime" BU_SG_REL_ IBU SG_ 1116 C_SteeringWheelHeaterSW 15000;
BA_REL_ "GenSigTimeoutTime" BU_SG_REL_ CGW SG_ 1116 CR_Datc_DRSeatWheel_USM_State 1500;
BA_REL_ "GenSigTimeoutTime" BU_SG_REL_ CGW SG_ 1116 CR_Datc_DRSeatHeat_USM_State 1500;
BA_REL_ "GenSigTimeoutTime" BU_SG_REL_ CGW SG_ 1116 DATC_WdwClsReq 1500;
BA_REL_ "GenSigTimeoutTime" BU_SG_REL_ IBU SG_ 1116 DATC_WdwClsReq 1500;
BA_REL_ "GenSigTimeoutTime" BU_SG_REL_ CGW SG_ 1116 DATC_ArClnSmblTyp 1500;
BA_REL_ "GenSigTimeoutTime" BU_SG_REL_ CGW SG_ 1116 DATC_ArClnStepClr 1500;
BA_REL_ "GenSigTimeoutTime" BU_SG_REL_ CGW SG_ 1116 DATC_ArClnSysOSD 1500;
BA_REL_ "GenSigTimeoutTime" BU_SG_REL_ BMS SG_ 16 CF_Acu_CshAct 0;
BA_REL_ "GenSigTimeoutTime" BU_SG_REL_ CGW SG_ 16 CF_Acu_CshAct 0;
BA_REL_ "GenSigTimeoutTime" BU_SG_REL_ DATC SG_ 16 CF_Acu_CshAct 0;
BA_REL_ "GenSigTimeoutTime" BU_SG_REL_ H_U SG_ 16 CF_Acu_CshAct 0;
BA_REL_ "GenSigTimeoutTime" BU_SG_REL_ LDC SG_ 16 CF_Acu_CshAct 0;
BA_REL_ "GenSigTimeoutTime" BU_SG_REL_ MCU SG_ 16 CF_Acu_CshAct 0;
BA_REL_ "GenSigTimeoutTime" BU_SG_REL_ ODS SG_ 16 CF_Acu_CshAct 0;
BA_REL_ "GenSigTimeoutTime" BU_SG_REL_ TMU SG_ 16 CF_Acu_CshAct 0;
BA_REL_ "GenSigTimeoutTime" BU_SG_REL_ eCall SG_ 16 CF_Acu_CshAct 0;
BA_REL_ "GenSigTimeoutTime" BU_SG_REL_ ESC SG_ 16 ACU_CrshInfo 0;
BA_REL_ "GenSigTimeoutTime" BU_SG_REL_ iBAU SG_ 16 ACU_CrshInfo 0;
BA_REL_ "GenSigTimeoutTime" BU_SG_REL_ iBAU SG_ 16 Acu_TypOfCrash 0;
BA_REL_ "GenSigTimeoutTime" BU_SG_REL_ vBDM SG_ 16 Acu_TypOfCrash 0;
BA_REL_ "GenSigTimeoutTime" BU_SG_REL_ DATC SG_ 1359 HU_DATC_DrTempUpDn 0;
BA_REL_ "GenSigTimeoutTime" BU_SG_REL_ DATC SG_ 1359 HU_DATC_PsTempUpDn 0;
BA_REL_ "GenSigTimeoutTime" BU_SG_REL_ DATC SG_ 1359 HU_DATC_RLTempUpDn 0;
BA_REL_ "GenSigTimeoutTime" BU_SG_REL_ DATC SG_ 1359 HU_DATC_RrTempUpDn 0;
BA_REL_ "GenSigTimeoutTime" BU_SG_REL_ DATC SG_ 1359 HU_DATC_MainBlower 0;
BA_REL_ "GenSigTimeoutTime" BU_SG_REL_ DATC SG_ 1359 HU_DATC_RearBlower 0;
BA_REL_ "GenSigTimeoutTime" BU_SG_REL_ DATC SG_ 1359 HU_DATCRearPsModeSet 0;
BA_REL_ "GenSigTimeoutTime" BU_SG_REL_ DATC SG_ 1359 HU_DATC_FrontModeSet 0;
BA_REL_ "GenSigTimeoutTime" BU_SG_REL_ DATC SG_ 1359 HU_DATC_RearModeSet 0;
BA_REL_ "GenSigTimeoutTime" BU_SG_REL_ DATC SG_ 1359 HU_DATC_AutoSet 0;
BA_REL_ "GenSigTimeoutTime" BU_SG_REL_ DATC SG_ 1359 HU_DATC_OffReq 0;
BA_REL_ "GenSigTimeoutTime" BU_SG_REL_ DATC SG_ 1359 HU_DATC_IntakeSet 0;
BA_REL_ "GenSigTimeoutTime" BU_SG_REL_ DATC SG_ 1359 HU_DATC_RearOnOffSet 0;
BA_REL_ "GenSigTimeoutTime" BU_SG_REL_ DATC SG_ 1359 HU_DATC_AcSet 0;
BA_REL_ "GenSigTimeoutTime" BU_SG_REL_ DATC SG_ 1359 HU_DATC_FrontDefog 0;
BA_REL_ "GenSigTimeoutTime" BU_SG_REL_ DATC SG_ 1359 HU_DATC_RearDefog 0;
BA_REL_ "GenSigTimeoutTime" BU_SG_REL_ DATC SG_ 1359 HU_DATC_CO2Set 0;
BA_REL_ "GenSigTimeoutTime" BU_SG_REL_ DATC SG_ 1359 DATC_SmartVentOnOffSet 0;
BA_REL_ "GenSigTimeoutTime" BU_SG_REL_ DATC SG_ 1359 DATC_ADSOnOffSet 0;
BA_REL_ "GenSigTimeoutTime" BU_SG_REL_ DATC SG_ 1359 HU_Datc_RearAutoDisp 0;
BA_REL_ "GenSigTimeoutTime" BU_SG_REL_ DATC SG_ 1359 HU_Datc_RearOffDisp 0;
BA_REL_ "GenSigTimeoutTime" BU_SG_REL_ DATC SG_ 1359 HU_DATC_MainBlowerUpDn 0;
BA_REL_ "GenSigTimeoutTime" BU_SG_REL_ DATC SG_ 1359 HU_DATC_AirCleaningSet 0;
BA_REL_ "GenSigTimeoutTime" BU_SG_REL_ VCU SG_ 1118 CR_Tmu_DrvDistance7 2000;
BA_REL_ "GenSigTimeoutTime" BU_SG_REL_ VCU SG_ 1118 CR_Tmu_DrvDistance8 2000;
BA_REL_ "GenSigTimeoutTime" BU_SG_REL_ VCU SG_ 1118 CR_Tmu_DrvDistance9 2000;
BA_REL_ "GenSigTimeoutTime" BU_SG_REL_ VCU SG_ 1118 CR_Tmu_DrvDistance10 2000;
BA_REL_ "GenSigTimeoutTime" BU_SG_REL_ Dummy SG_ 1354 CF_BMS_Ewp1_FaultStatus 20000;
BA_REL_ "GenSigTimeoutTime" BU_SG_REL_ Dummy SG_ 1354 CF_BMS_Ewp1_ProtectMode 20000;
BA_REL_ "GenSigTimeoutTime" BU_SG_REL_ Dummy SG_ 1354 CR_BMS_Ewp1_ActRotSpdrpm 20000;
BA_REL_ "GenSigTimeoutTime" BU_SG_REL_ CGW SG_ 1354 CR_BMS_Ewp1_Version 20000;
BA_REL_ "GenSigTimeoutTime" BU_SG_REL_ Dummy SG_ 1354 CR_BMS_Ewp1_Version 20000;
BA_REL_ "GenSigTimeoutTime" BU_SG_REL_ vBDM SG_ 1354 CR_BMS_Ewp1_Version 20000;
BA_REL_ "GenSigTimeoutTime" BU_SG_REL_ Dummy SG_ 1354 CR_BMS_Ewp1_EepRomPopup 20000;
BA_REL_ "GenSigTimeoutTime" BU_SG_REL_ Dummy SG_ 1354 CR_BMS_Ewp1_Current_DC 20000;
BA_REL_ "GenSigTimeoutTime" BU_SG_REL_ Dummy SG_ 1354 CR_BMS_Ewp1_Current_Iq 20000;
BA_REL_ "GenSigTimeoutTime" BU_SG_REL_ Dummy SG_ 1354 CF_BMS_Ewp1_Short_Circuit 20000;
BA_REL_ "GenSigTimeoutTime" BU_SG_REL_ Dummy SG_ 1354 CF_BMS_Ewp1_GateDrvUVOV 20000;
BA_REL_ "GenSigTimeoutTime" BU_SG_REL_ Dummy SG_ 1354 CF_BMS_Ewp1_SpeedError 20000;
BA_REL_ "GenSigTimeoutTime" BU_SG_REL_ Dummy SG_ 1354 CF_BMS_Ewp1_OverTemp 20000;
BA_REL_ "GenSigTimeoutTime" BU_SG_REL_ Dummy SG_ 1354 CF_BMS_Ewp1_WarnTemp 20000;
BA_REL_ "GenSigTimeoutTime" BU_SG_REL_ Dummy SG_ 1354 CF_BMS_Ewp1_LowCurrent 20000;
BA_REL_ "GenSigTimeoutTime" BU_SG_REL_ Dummy SG_ 1354 CF_BMS_Ewp1_OverCurrent 20000;
BA_REL_ "GenSigTimeoutTime" BU_SG_REL_ Dummy SG_ 1354 CF_BMS_Ewp1_UnderVoltage 20000;
BA_REL_ "GenSigTimeoutTime" BU_SG_REL_ Dummy SG_ 1354 CF_BMS_Ewp1_OverVoltage 20000;
BA_REL_ "GenSigTimeoutTime" BU_SG_REL_ CGW SG_ 1115 CR_Vcu_DistEmpty_km 2000;
BA_REL_ "GenSigTimeoutTime" BU_SG_REL_ H_U SG_ 1115 CR_Vcu_DistEmpty_km 2000;
BA_REL_ "GenSigTimeoutTime" BU_SG_REL_ TMU SG_ 1115 CR_Vcu_DistEmpty_km 2000;
BA_REL_ "GenSigTimeoutTime" BU_SG_REL_ CGW SG_ 1115 CF_Vcu_AvnDteCalc 2000;
BA_REL_ "GenSigTimeoutTime" BU_SG_REL_ CGW SG_ 1115 CF_Vcu_DriveMode 2000;
BA_REL_ "GenSigTimeoutTime" BU_SG_REL_ DATC SG_ 1115 CF_Vcu_DriveMode 2000;
BA_REL_ "GenSigTimeoutTime" BU_SG_REL_ MCU SG_ 1115 CF_Vcu_DriveMode 2000;
BA_REL_ "GenSigTimeoutTime" BU_SG_REL_ iBAU SG_ 1115 CF_Vcu_DriveMode 2000;
BA_REL_ "GenSigTimeoutTime" BU_SG_REL_ CGW SG_ 1115 CR_Vcu_DistEmptyAdd_km 2000;
BA_REL_ "GenSigTimeoutTime" BU_SG_REL_ TMU SG_ 1115 CR_Vcu_DistEmptyAdd_km 2000;
BA_REL_ "GenSigTimeoutTime" BU_SG_REL_ EVP1 SG_ 1115 CF_Vcu_BrkLampSta 0;
BA_REL_ "GenSigTimeoutTime" BU_SG_REL_ EVP2 SG_ 1115 CF_Vcu_BrkLampSta 0;
BA_REL_ "GenSigTimeoutTime" BU_SG_REL_ CGW SG_ 1115 CR_Vcu_TgSocDteExt_AcChg 0;
BA_REL_ "GenSigTimeoutTime" BU_SG_REL_ CGW SG_ 1115 CR_Vcu_TgSocDteExt_DcChg 0;
BA_REL_ "GenSigTimeoutTime" BU_SG_REL_ CGW SG_ 1346 CR_Bms_DisplaySoc 2000;
BA_REL_ "GenSigTimeoutTime" BU_SG_REL_ TMU SG_ 1346 CR_Bms_DisplaySoc 2000;
BA_REL_ "GenSigTimeoutTime" BU_SG_REL_ vBDM SG_ 1346 CR_Bms_DisplaySoc 2000;
BA_REL_ "GenSigTimeoutTime" BU_SG_REL_ Dummy SG_ 1346 CR_Bms_BatMaxTemp_C 2000;
BA_REL_ "GenSigTimeoutTime" BU_SG_REL_ CGW SG_ 1346 CR_Bms_HeatPwrSum_Wh 2000;
BA_REL_ "GenSigTimeoutTime" BU_SG_REL_ TMU SG_ 1346 CR_Bms_HeatPwrSum_Wh 2000;
BA_REL_ "GenSigTimeoutTime" BU_SG_REL_ CGW SG_ 1346 CF_Bms_Notify_Pilotfail 2000;
BA_REL_ "GenSigTimeoutTime" BU_SG_REL_ TMU SG_ 1346 CF_Bms_Notify_Pilotfail 2000;
BA_REL_ "GenSigTimeoutTime" BU_SG_REL_ CGW SG_ 1346 CF_Bms_PShiftForCharging 2000;
BA_REL_ "GenSigTimeoutTime" BU_SG_REL_ TMU SG_ 1346 CF_Bms_PShiftForCharging 2000;
BA_REL_ "GenSigTimeoutTime" BU_SG_REL_ CGW SG_ 1346 CF_Bms_FstEvseFltAlram 2000;
BA_REL_ "GenSigTimeoutTime" BU_SG_REL_ TMU SG_ 1346 CF_Bms_FstEvseFltAlram 2000;
BA_REL_ "GenSigTimeoutTime" BU_SG_REL_ Dummy SG_ 1346 CR_Bms_CoolantLeakage2_V 2000;
BA_REL_ "GenSigTimeoutTime" BU_SG_REL_ VCU SG_ 1346 CR_Bms_ObcMainsVol 2000;
BA_REL_ "GenSigTimeoutTime" BU_SG_REL_ VCU SG_ 1346 CR_Bms_ObcOutCur 2000;
BA_REL_ "GenSigTimeoutTime" BU_SG_REL_ MCU SG_ 1346 CR_Bms_QcOutputVolt 2000;
BA_REL_ "GenSigTimeoutTime" BU_SG_REL_ VCU SG_ 1346 CR_Bms_QcOutputVolt 2000;
BA_REL_ "GenSigTimeoutTime" BU_SG_REL_ CGW SG_ 1344 CR_Mcu_VCRM_Rsv_Mag_Diff 2000;
BA_REL_ "GenSigTimeoutTime" BU_SG_REL_ TMU SG_ 1344 CR_Mcu_VCRM_Rsv_Mag_Diff 2000;
BA_REL_ "GenSigTimeoutTime" BU_SG_REL_ vBDM SG_ 1344 CR_Mcu_VCRM_Rsv_Mag_Diff 2000;
BA_REL_ "GenSigTimeoutTime" BU_SG_REL_ CGW SG_ 1344 CR_Mcu_VCRM_Idc_A 2000;
BA_REL_ "GenSigTimeoutTime" BU_SG_REL_ NEMS SG_ 1344 CR_Mcu_VCRM_Idc_A 2000;
BA_REL_ "GenSigTimeoutTime" BU_SG_REL_ TMU SG_ 1344 CR_Mcu_VCRM_Imag_A 2000;
BA_REL_ "GenSigTimeoutTime" BU_SG_REL_ CGW SG_ 1344 CR_Mcu_Mot_Power_wh 2000;
BA_REL_ "GenSigTimeoutTime" BU_SG_REL_ LVR SG_ 1345 CF_Gway_LightSwState 1000;
BA_REL_ "GenSigTimeoutTime" BU_SG_REL_ Dummy SG_ 1345 CF_Gway_TSigLHSw 1000;
BA_REL_ "GenSigTimeoutTime" BU_SG_REL_ Dummy SG_ 1345 CF_Gway_TSigRHSw 1000;
BA_REL_ "GenSigTimeoutTime" BU_SG_REL_ Dummy SG_ 1345 CF_Gway_StarterRlyState 1000;
BA_REL_ "GenSigTimeoutTime" BU_SG_REL_ Dummy SG_ 1345 CF_Gway_PassiveAccessLock 1000;
BA_REL_ "GenSigTimeoutTime" BU_SG_REL_ LDC SG_ 1345 CF_Gway_RearFogAct 1000;
BA_REL_ "GenSigTimeoutTime" BU_SG_REL_ Dummy SG_ 1345 CF_Gway_PassiveAccessUnlock 1000;
BA_REL_ "GenSigTimeoutTime" BU_SG_REL_ ACU SG_ 1345 CF_Gway_Ign1 1000;
BA_REL_ "GenSigTimeoutTime" BU_SG_REL_ CDM SG_ 1345 CF_Gway_Ign1 1000;
BA_REL_ "GenSigTimeoutTime" BU_SG_REL_ Dummy SG_ 1345 CF_Gway_Ign1 1000;
BA_REL_ "GenSigTimeoutTime" BU_SG_REL_ VCU SG_ 1345 CF_Gway_Ign1 1000;
BA_REL_ "GenSigTimeoutTime" BU_SG_REL_ iBAU SG_ 1345 CF_Gway_Ign1 1000;
BA_REL_ "GenSigTimeoutTime" BU_SG_REL_ ACU SG_ 1345 CF_Gway_Ign2 1000;
BA_REL_ "GenSigTimeoutTime" BU_SG_REL_ Dummy SG_ 1345 CF_Gway_Ign2 1000;
BA_REL_ "GenSigTimeoutTime" BU_SG_REL_ VCU SG_ 1345 CF_Gway_Ign2 1000;
BA_REL_ "GenSigTimeoutTime" BU_SG_REL_ VCU SG_ 1405 Msg_Group_Num4 2000;
BA_REL_ "GenSigTimeoutTime" BU_SG_REL_ VCU SG_ 1405 FrontPos_Info_Lat_1 2000;
BA_REL_ "GenSigTimeoutTime" BU_SG_REL_ VCU SG_ 1405 FrontPos_Info_Long_1 2000;
BA_REL_ "GenSigTimeoutTime" BU_SG_REL_ VCU SG_ 1405 FrontPos_Info_Lat_2 2000;
BA_REL_ "GenSigTimeoutTime" BU_SG_REL_ VCU SG_ 1405 FrontPos_Info_Long_2 2000;
BA_REL_ "GenSigTimeoutTime" BU_SG_REL_ VCU SG_ 1405 FrontPos_Info_Lat_3 2000;
BA_REL_ "GenSigTimeoutTime" BU_SG_REL_ VCU SG_ 1405 FrontPos_Info_Long_3 2000;
BA_REL_ "GenSigTimeoutTime" BU_SG_REL_ VCU SG_ 1404 Msg_Group_Num3 2000;
BA_REL_ "GenSigTimeoutTime" BU_SG_REL_ VCU SG_ 1404 CurPos_Info_Lat 2000;
BA_REL_ "GenSigTimeoutTime" BU_SG_REL_ VCU SG_ 1404 CurPos_Info_Long 2000;
BA_REL_ "GenSigTimeoutTime" BU_SG_REL_ BMS SG_ 1407 CF_OBC_CONTRAB 2000;
BA_REL_ "GenSigTimeoutTime" BU_SG_REL_ TMU SG_ 1407 CF_OBC_CONTRAB 2000;
BA_REL_ "GenSigTimeoutTime" BU_SG_REL_ BMS SG_ 1407 CF_OBC_PD_Stat 2000;
BA_REL_ "GenSigTimeoutTime" BU_SG_REL_ CCM SG_ 1407 CF_OBC_PD_Stat 2000;
BA_REL_ "GenSigTimeoutTime" BU_SG_REL_ CGW SG_ 1407 CF_OBC_PD_Stat 2000;
BA_REL_ "GenSigTimeoutTime" BU_SG_REL_ H_U SG_ 1407 CF_OBC_PD_Stat 2000;
BA_REL_ "GenSigTimeoutTime" BU_SG_REL_ SMK SG_ 1407 CF_OBC_PD_Stat 2000;
BA_REL_ "GenSigTimeoutTime" BU_SG_REL_ TMU SG_ 1407 CF_OBC_PD_Stat 2000;
BA_REL_ "GenSigTimeoutTime" BU_SG_REL_ BMS SG_ 1407 CF_OBC_Chg_Finished 2000;
BA_REL_ "GenSigTimeoutTime" BU_SG_REL_ CCM SG_ 1407 CF_OBC_Chg_Finished 2000;
BA_REL_ "GenSigTimeoutTime" BU_SG_REL_ TMU SG_ 1407 CF_OBC_Chg_Finished 2000;
BA_REL_ "GenSigTimeoutTime" BU_SG_REL_ BMS SG_ 1407 CF_OBC_EVSE_RDY_STATE 2000;
BA_REL_ "GenSigTimeoutTime" BU_SG_REL_ CDM SG_ 1407 CF_OBC_EVSE_RDY_STATE 2000;
BA_REL_ "GenSigTimeoutTime" BU_SG_REL_ CGW SG_ 1407 CF_OBC_EVSE_RDY_STATE 2000;
BA_REL_ "GenSigTimeoutTime" BU_SG_REL_ H_U SG_ 1407 CF_OBC_EVSE_RDY_STATE 2000;
BA_REL_ "GenSigTimeoutTime" BU_SG_REL_ TMU SG_ 1407 CF_OBC_EVSE_RDY_STATE 2000;
BA_REL_ "GenSigTimeoutTime" BU_SG_REL_ VCU SG_ 1407 CF_OBC_EVSE_RDY_STATE 2000;
BA_REL_ "GenSigTimeoutTime" BU_SG_REL_ BMS SG_ 1407 CF_OBC_WRN 2000;
BA_REL_ "GenSigTimeoutTime" BU_SG_REL_ TMU SG_ 1407 CF_OBC_WRN 2000;
BA_REL_ "GenSigTimeoutTime" BU_SG_REL_ BMS SG_ 1407 CF_OBC_FLT 2000;
BA_REL_ "GenSigTimeoutTime" BU_SG_REL_ CGW SG_ 1407 CF_OBC_FLT 2000;
BA_REL_ "GenSigTimeoutTime" BU_SG_REL_ H_U SG_ 1407 CF_OBC_FLT 2000;
BA_REL_ "GenSigTimeoutTime" BU_SG_REL_ TMU SG_ 1407 CF_OBC_FLT 2000;
BA_REL_ "GenSigTimeoutTime" BU_SG_REL_ VCU SG_ 1407 CF_OBC_FLT 2000;
BA_REL_ "GenSigTimeoutTime" BU_SG_REL_ BMS SG_ 1407 CF_OBC_RDY 2000;
BA_REL_ "GenSigTimeoutTime" BU_SG_REL_ CGW SG_ 1407 CF_OBC_RDY 2000;
BA_REL_ "GenSigTimeoutTime" BU_SG_REL_ TMU SG_ 1407 CF_OBC_RDY 2000;
BA_REL_ "GenSigTimeoutTime" BU_SG_REL_ VCU SG_ 1407 CF_OBC_RDY 2000;
BA_REL_ "GenSigTimeoutTime" BU_SG_REL_ BMS SG_ 1407 CF_OBC_AC_DETECT_FLAG 2000;
BA_REL_ "GenSigTimeoutTime" BU_SG_REL_ CDM SG_ 1407 CF_OBC_AC_DETECT_FLAG 2000;
BA_REL_ "GenSigTimeoutTime" BU_SG_REL_ DATC SG_ 1407 CF_OBC_AC_DETECT_FLAG 2000;
BA_REL_ "GenSigTimeoutTime" BU_SG_REL_ TMU SG_ 1407 CF_OBC_AC_DETECT_FLAG 2000;
BA_REL_ "GenSigTimeoutTime" BU_SG_REL_ BMS SG_ 1407 CR_OBC_CP_Volt 2000;
BA_REL_ "GenSigTimeoutTime" BU_SG_REL_ TMU SG_ 1407 CR_OBC_CP_Volt 2000;
BA_REL_ "GenSigTimeoutTime" BU_SG_REL_ VCU SG_ 1407 CR_OBC_CP_Volt 2000;
BA_REL_ "GenSigTimeoutTime" BU_SG_REL_ AAF SG_ 1407 CR_OBC_TEMP 2000;
BA_REL_ "GenSigTimeoutTime" BU_SG_REL_ MCU SG_ 1407 CR_OBC_TEMP 2000;
BA_REL_ "GenSigTimeoutTime" BU_SG_REL_ TMU SG_ 1407 CR_OBC_TEMP 2000;
BA_REL_ "GenSigTimeoutTime" BU_SG_REL_ VCU SG_ 1407 CR_OBC_TEMP 2000;
BA_REL_ "GenSigTimeoutTime" BU_SG_REL_ MCU SG_ 1407 CR_OBC_RadFanReq_Duty 2000;
BA_REL_ "GenSigTimeoutTime" BU_SG_REL_ TMU SG_ 1407 CR_OBC_RadFanReq_Duty 2000;
BA_REL_ "GenSigTimeoutTime" BU_SG_REL_ VCU SG_ 1407 CR_OBC_RadFanReq_Duty 2000;
BA_REL_ "GenSigTimeoutTime" BU_SG_REL_ BMS SG_ 1407 CF_OBC_IG3_DRV_STATE 2000;
BA_REL_ "GenSigTimeoutTime" BU_SG_REL_ CDM SG_ 1407 CF_OBC_IG3_DRV_STATE 2000;
BA_REL_ "GenSigTimeoutTime" BU_SG_REL_ TMU SG_ 1407 CF_OBC_IG3_DRV_STATE 2000;
BA_REL_ "GenSigTimeoutTime" BU_SG_REL_ VCU SG_ 1407 CF_OBC_IG3_DRV_STATE 2000;
BA_REL_ "GenSigTimeoutTime" BU_SG_REL_ BMS SG_ 1407 CF_OBC_AC_CONNECT 2000;
BA_REL_ "GenSigTimeoutTime" BU_SG_REL_ CCM SG_ 1407 CF_OBC_AC_CONNECT 2000;
BA_REL_ "GenSigTimeoutTime" BU_SG_REL_ CDM SG_ 1407 CF_OBC_AC_CONNECT 2000;
BA_REL_ "GenSigTimeoutTime" BU_SG_REL_ CGW SG_ 1407 CF_OBC_AC_CONNECT 2000;
BA_REL_ "GenSigTimeoutTime" BU_SG_REL_ IBU SG_ 1407 CF_OBC_AC_CONNECT 2000;
BA_REL_ "GenSigTimeoutTime" BU_SG_REL_ SMK SG_ 1407 CF_OBC_AC_CONNECT 2000;
BA_REL_ "GenSigTimeoutTime" BU_SG_REL_ TMU SG_ 1407 CF_OBC_AC_CONNECT 2000;
BA_REL_ "GenSigTimeoutTime" BU_SG_REL_ VCU SG_ 1407 CF_OBC_AC_CONNECT 2000;
BA_REL_ "GenSigTimeoutTime" BU_SG_REL_ BMS SG_ 1407 CF_OBC_S2_SW_ON_FLAG 2000;
BA_REL_ "GenSigTimeoutTime" BU_SG_REL_ CCM SG_ 1407 CF_OBC_S2_SW_ON_FLAG 2000;
BA_REL_ "GenSigTimeoutTime" BU_SG_REL_ TMU SG_ 1407 CF_OBC_S2_SW_ON_FLAG 2000;
BA_REL_ "GenSigTimeoutTime" BU_SG_REL_ BMS SG_ 1407 CF_OBC_MainRlyOn_Req 2000;
BA_REL_ "GenSigTimeoutTime" BU_SG_REL_ TMU SG_ 1407 CF_OBC_MainRlyOn_Req 2000;
BA_REL_ "GenSigTimeoutTime" BU_SG_REL_ BMS SG_ 1407 CF_OBC_OBCRlyOn_Req 2000;
BA_REL_ "GenSigTimeoutTime" BU_SG_REL_ TMU SG_ 1407 CF_OBC_OBCRlyOn_Req 2000;
BA_REL_ "GenSigTimeoutTime" BU_SG_REL_ CGW SG_ 1407 CF_OBC_MILReq 2000;
BA_REL_ "GenSigTimeoutTime" BU_SG_REL_ H_U SG_ 1407 CF_OBC_MILReq 2000;
BA_REL_ "GenSigTimeoutTime" BU_SG_REL_ TMU SG_ 1407 CF_OBC_MILReq 2000;
BA_REL_ "GenSigTimeoutTime" BU_SG_REL_ VCU SG_ 1407 CF_OBC_MILReq 2000;
BA_REL_ "GenSigTimeoutTime" BU_SG_REL_ CGW SG_ 1407 CF_OBC_VCRM_Req 2000;
BA_REL_ "GenSigTimeoutTime" BU_SG_REL_ H_U SG_ 1407 CF_OBC_VCRM_Req 2000;
BA_REL_ "GenSigTimeoutTime" BU_SG_REL_ TMU SG_ 1407 CF_OBC_VCRM_Req 2000;
BA_REL_ "GenSigTimeoutTime" BU_SG_REL_ vBDM SG_ 1407 CF_OBC_VCRM_Req 2000;
BA_REL_ "GenSigTimeoutTime" BU_SG_REL_ MCU SG_ 1407 CF_OBC_RAD_Fan_Req 2000;
BA_REL_ "GenSigTimeoutTime" BU_SG_REL_ TMU SG_ 1407 CF_OBC_RAD_Fan_Req 2000;
BA_REL_ "GenSigTimeoutTime" BU_SG_REL_ VCU SG_ 1407 CF_OBC_RAD_Fan_Req 2000;
BA_REL_ "GenSigTimeoutTime" BU_SG_REL_ CGW SG_ 1407 CF_OBC_SERVICE_LAMP_Req 2000;
BA_REL_ "GenSigTimeoutTime" BU_SG_REL_ H_U SG_ 1407 CF_OBC_SERVICE_LAMP_Req 2000;
BA_REL_ "GenSigTimeoutTime" BU_SG_REL_ TMU SG_ 1407 CF_OBC_SERVICE_LAMP_Req 2000;
BA_REL_ "GenSigTimeoutTime" BU_SG_REL_ BMS SG_ 1407 CF_OBC_HvIntlockReq 2000;
BA_REL_ "GenSigTimeoutTime" BU_SG_REL_ DATC SG_ 1407 CF_OBC_HvIntlockReq 2000;
BA_REL_ "GenSigTimeoutTime" BU_SG_REL_ LDC SG_ 1407 CF_OBC_HvIntlockReq 2000;
BA_REL_ "GenSigTimeoutTime" BU_SG_REL_ MCU SG_ 1407 CF_OBC_HvIntlockReq 2000;
BA_REL_ "GenSigTimeoutTime" BU_SG_REL_ TMU SG_ 1407 CF_OBC_HvIntlockReq 2000;
BA_REL_ "GenSigTimeoutTime" BU_SG_REL_ CCM SG_ 1407 CF_EVSE_FAULT_FLAG 2000;
BA_REL_ "GenSigTimeoutTime" BU_SG_REL_ CGW SG_ 1407 CF_EVSE_FAULT_FLAG 2000;
BA_REL_ "GenSigTimeoutTime" BU_SG_REL_ TMU SG_ 1407 CF_EVSE_FAULT_FLAG 2000;
BA_REL_ "GenSigTimeoutTime" BU_SG_REL_ BMS SG_ 1407 CF_OBC_DCChargingStat 2000;
BA_REL_ "GenSigTimeoutTime" BU_SG_REL_ CCM SG_ 1407 CF_OBC_DCChargingStat 2000;
BA_REL_ "GenSigTimeoutTime" BU_SG_REL_ CDM SG_ 1407 CF_OBC_DCChargingStat 2000;
BA_REL_ "GenSigTimeoutTime" BU_SG_REL_ CGW SG_ 1407 CF_OBC_DCChargingStat 2000;
BA_REL_ "GenSigTimeoutTime" BU_SG_REL_ H_U SG_ 1407 CF_OBC_DCChargingStat 2000;
BA_REL_ "GenSigTimeoutTime" BU_SG_REL_ TMU SG_ 1407 CF_OBC_DCChargingStat 2000;
BA_REL_ "GenSigTimeoutTime" BU_SG_REL_ CDM SG_ 1407 CF_OBC_ACChargingStat 2000;
BA_REL_ "GenSigTimeoutTime" BU_SG_REL_ CGW SG_ 1407 CF_OBC_ACChargingStat 2000;
BA_REL_ "GenSigTimeoutTime" BU_SG_REL_ H_U SG_ 1407 CF_OBC_ACChargingStat 2000;
BA_REL_ "GenSigTimeoutTime" BU_SG_REL_ TMU SG_ 1407 CF_OBC_ACChargingStat 2000;
BA_REL_ "GenSigTimeoutTime" BU_SG_REL_ VCU SG_ 1407 CF_OBC_ACChargingStat 2000;
BA_REL_ "GenSigTimeoutTime" BU_SG_REL_ VCU SG_ 1407 CF_OBC_ImmeChgSwState 2000;
BA_REL_ "GenSigTimeoutTime" BU_SG_REL_ MCU SG_ 1407 CR_OBC_EWP_Rpm_Req 2000;
BA_REL_ "GenSigTimeoutTime" BU_SG_REL_ TMU SG_ 1407 CR_OBC_EWP_Rpm_Req 2000;
BA_REL_ "GenSigTimeoutTime" BU_SG_REL_ VCU SG_ 1407 CR_OBC_EWP_Rpm_Req 2000;
BA_REL_ "GenSigTimeoutTime" BU_SG_REL_ AAF SG_ 1407 CR_OBC_TEMP_B 2000;
BA_REL_ "GenSigTimeoutTime" BU_SG_REL_ MCU SG_ 1407 CR_OBC_TEMP_B 2000;
BA_REL_ "GenSigTimeoutTime" BU_SG_REL_ TMU SG_ 1407 CR_OBC_TEMP_B 2000;
BA_REL_ "GenSigTimeoutTime" BU_SG_REL_ VCU SG_ 1407 CR_OBC_TEMP_B 2000;
BA_REL_ "GenSigTimeoutTime" BU_SG_REL_ VCU SG_ 1406 Msg_Group_Num5 2000;
BA_REL_ "GenSigTimeoutTime" BU_SG_REL_ VCU SG_ 1406 FrontPos_Info_Lat_4 2000;
BA_REL_ "GenSigTimeoutTime" BU_SG_REL_ VCU SG_ 1406 FrontPos_Info_Long_4 2000;
BA_REL_ "GenSigTimeoutTime" BU_SG_REL_ VCU SG_ 1406 FrontPos_Info_Lat_5 2000;
BA_REL_ "GenSigTimeoutTime" BU_SG_REL_ VCU SG_ 1406 FrontPos_Info_Long_5 2000;
BA_REL_ "GenSigTimeoutTime" BU_SG_REL_ VCU SG_ 1406 FrontPos_Info_Update 2000;
BA_REL_ "GenSigTimeoutTime" BU_SG_REL_ Dummy SG_ 1133 CF_Ctm_TrailerAct 1500;
BA_REL_ "GenSigTimeoutTime" BU_SG_REL_ VCU SG_ 1133 CF_Ctm_TrailerAct 1500;
BA_REL_ "GenSigTimeoutTime" BU_SG_REL_ Dummy SG_ 1133 CF_Ctm_RearfogAct 0;
BA_REL_ "GenSigTimeoutTime" BU_SG_REL_ CGW SG_ 1401 CF_Vcu_SchedChgMode 2000;
BA_REL_ "GenSigTimeoutTime" BU_SG_REL_ OBC SG_ 1401 CF_Vcu_SchedChgMode 2000;
BA_REL_ "GenSigTimeoutTime" BU_SG_REL_ TMU SG_ 1401 CF_Vcu_SchedChgMode 2000;
BA_REL_ "GenSigTimeoutTime" BU_SG_REL_ vBDM SG_ 1401 CF_Vcu_SchedChgMode 2000;
BA_REL_ "GenSigTimeoutTime" BU_SG_REL_ CGW SG_ 1401 CR_Vcu_OffPeakTimeStHr 2000;
BA_REL_ "GenSigTimeoutTime" BU_SG_REL_ TMU SG_ 1401 CR_Vcu_OffPeakTimeStHr 2000;
BA_REL_ "GenSigTimeoutTime" BU_SG_REL_ CGW SG_ 1401 CR_Vcu_OffPeakTimeStMin 2000;
BA_REL_ "GenSigTimeoutTime" BU_SG_REL_ TMU SG_ 1401 CR_Vcu_OffPeakTimeStMin 2000;
BA_REL_ "GenSigTimeoutTime" BU_SG_REL_ CGW SG_ 1401 CR_Vcu_OffPeakTimeEndHr 2000;
BA_REL_ "GenSigTimeoutTime" BU_SG_REL_ TMU SG_ 1401 CR_Vcu_OffPeakTimeEndHr 2000;
BA_REL_ "GenSigTimeoutTime" BU_SG_REL_ CGW SG_ 1401 CR_Vcu_OffPeakTimeEndMin 2000;
BA_REL_ "GenSigTimeoutTime" BU_SG_REL_ TMU SG_ 1401 CR_Vcu_OffPeakTimeEndMin 2000;
BA_REL_ "GenSigTimeoutTime" BU_SG_REL_ CGW SG_ 1401 CF_Vcu_RestModeRValueSet 2000;
BA_REL_ "GenSigTimeoutTime" BU_SG_REL_ CGW SG_ 1401 CF_Vcu_RestModeWarn 2000;
BA_REL_ "GenSigTimeoutTime" BU_SG_REL_ CGW SG_ 1401 CF_Vcu_RestModeVehCond 2000;
BA_REL_ "GenSigTimeoutTime" BU_SG_REL_ CGW SG_ 1401 CF_Vcu_EpbRequest 2000;
BA_REL_ "GenSigTimeoutTime" BU_SG_REL_ CGW SG_ 1401 CF_Vcu_GpsSched_State 2000;
BA_REL_ "GenSigTimeoutTime" BU_SG_REL_ CGW SG_ 1401 CF_Vcu_GpsSched_ChgAir 2000;
BA_REL_ "GenSigTimeoutTime" BU_SG_REL_ CGW SG_ 1401 CF_Vcu_GpsSchedUpdateRq 2000;
BA_REL_ "GenSigTimeoutTime" BU_SG_REL_ Dummy SG_ 1401 CF_Vcu_MainBattType 0;
BA_REL_ "GenSigTimeoutTime" BU_SG_REL_ Dummy SG_ 1401 CF_Vcu_MainBattTypeLrnSts 0;
BA_REL_ "GenSigTimeoutTime" BU_SG_REL_ CGW SG_ 1401 CF_Vcu_RegenLevel_Eco 2000;
BA_REL_ "GenSigTimeoutTime" BU_SG_REL_ TMU SG_ 1401 CF_Vcu_RegenLevel_Eco 2000;
BA_REL_ "GenSigTimeoutTime" BU_SG_REL_ CGW SG_ 1401 CF_Vcu_RegenLevel_Normal 2000;
BA_REL_ "GenSigTimeoutTime" BU_SG_REL_ TMU SG_ 1401 CF_Vcu_RegenLevel_Normal 2000;
BA_REL_ "GenSigTimeoutTime" BU_SG_REL_ CGW SG_ 1401 CF_Vcu_RegenLevel_Sport 2000;
BA_REL_ "GenSigTimeoutTime" BU_SG_REL_ TMU SG_ 1401 CF_Vcu_RegenLevel_Sport 2000;
BA_REL_ "GenSigTimeoutTime" BU_SG_REL_ CGW SG_ 1401 CF_Vcu_SmartRegen_RValueSet 2000;
BA_REL_ "GenSigTimeoutTime" BU_SG_REL_ CGW SG_ 1401 CF_Vcu_SmartRegen_Disp 2000;
BA_REL_ "GenSigTimeoutTime" BU_SG_REL_ CGW SG_ 1401 CF_Vcu_SmartRegen_Step 2000;
BA_REL_ "GenSigTimeoutTime" BU_SG_REL_ CGW SG_ 1401 CF_Vcu_SmartRegen_WarnMsg 2000;
BA_REL_ "GenSigTimeoutTime" BU_SG_REL_ BMS SG_ 1401 CF_Vcu_DriveMode 2000;
BA_REL_ "GenSigTimeoutTime" BU_SG_REL_ CGW SG_ 1401 CF_Vcu_DriveMode 2000;
BA_REL_ "GenSigTimeoutTime" BU_SG_REL_ DATC SG_ 1401 CF_Vcu_DriveMode 2000;
BA_REL_ "GenSigTimeoutTime" BU_SG_REL_ LDC SG_ 1401 CF_Vcu_DriveMode 2000;
BA_REL_ "GenSigTimeoutTime" BU_SG_REL_ MCU SG_ 1401 CF_Vcu_DriveMode 2000;
BA_REL_ "GenSigTimeoutTime" BU_SG_REL_ CGW SG_ 1401 CF_Vcu_SpdLmt 2000;
BA_REL_ "GenSigTimeoutTime" BU_SG_REL_ TMU SG_ 1401 CF_Vcu_SpdLmt 2000;
BA_REL_ "GenSigTimeoutTime" BU_SG_REL_ CGW SG_ 1401 CR_Vcu_MaxSpd 2000;
BA_REL_ "GenSigTimeoutTime" BU_SG_REL_ TMU SG_ 1401 CR_Vcu_MaxSpd 2000;
BA_REL_ "GenSigTimeoutTime" BU_SG_REL_ Dummy SG_ 1400 CF_Clu_LowfuelWarn 1000;
BA_REL_ "GenSigTimeoutTime" BU_SG_REL_ NEMS SG_ 1400 CF_Ahb_Def 1000;
BA_REL_ "GenSigTimeoutTime" BU_SG_REL_ TMU SG_ 1400 CF_Ahb_Def 1000;
BA_REL_ "GenSigTimeoutTime" BU_SG_REL_ VCU SG_ 1400 CF_Ahb_Def 1000;
BA_REL_ "GenSigTimeoutTime" BU_SG_REL_ TMU SG_ 1400 CF_Clu_ActiveEcoSW 1000;
BA_REL_ "GenSigTimeoutTime" BU_SG_REL_ VCU SG_ 1400 CF_Clu_ActiveEcoSW 1000;
BA_REL_ "GenSigTimeoutTime" BU_SG_REL_ H_U SG_ 1400 POS_FL_W_LAMP 2000;
BA_REL_ "GenSigTimeoutTime" BU_SG_REL_ TMU SG_ 1400 POS_FL_W_LAMP 2000;
BA_REL_ "GenSigTimeoutTime" BU_SG_REL_ H_U SG_ 1400 POS_FR_W_LAMP 2000;
BA_REL_ "GenSigTimeoutTime" BU_SG_REL_ TMU SG_ 1400 POS_FR_W_LAMP 2000;
BA_REL_ "GenSigTimeoutTime" BU_SG_REL_ H_U SG_ 1400 POS_RL_W_LAMP 2000;
BA_REL_ "GenSigTimeoutTime" BU_SG_REL_ TMU SG_ 1400 POS_RL_W_LAMP 2000;
BA_REL_ "GenSigTimeoutTime" BU_SG_REL_ H_U SG_ 1400 POS_RR_W_LAMP 2000;
BA_REL_ "GenSigTimeoutTime" BU_SG_REL_ TMU SG_ 1400 POS_RR_W_LAMP 2000;
BA_REL_ "GenSigTimeoutTime" BU_SG_REL_ H_U SG_ 1400 TPMS_W_LAMP 2000;
BA_REL_ "GenSigTimeoutTime" BU_SG_REL_ TMU SG_ 1400 TPMS_W_LAMP 2000;
BA_REL_ "GenSigTimeoutTime" BU_SG_REL_ H_U SG_ 1400 TREAD_W_LAMP 2000;
BA_REL_ "GenSigTimeoutTime" BU_SG_REL_ TMU SG_ 1400 TREAD_W_LAMP 2000;
BA_REL_ "GenSigTimeoutTime" BU_SG_REL_ VCU SG_ 1400 CF_Clu_SmartRegen_NValueSet 0;
BA_REL_ "GenSigTimeoutTime" BU_SG_REL_ VCU SG_ 1400 CF_Clu_NCC_CameraNValueSet 0;
BA_REL_ "GenSigTimeoutTime" BU_SG_REL_ H_U SG_ 1400 CF_DAW_Warn 2000;
BA_REL_ "GenSigTimeoutTime" BU_SG_REL_ TMU SG_ 1400 CF_DAW_Warn 2000;
BA_REL_ "GenSigTimeoutTime" BU_SG_REL_ H_U SG_ 1400 CF_Clu_DAWLastBreakTime 1000;
BA_REL_ "GenSigTimeoutTime" BU_SG_REL_ TMU SG_ 1400 CF_Clu_DAWLastBreakTime 1000;
BA_REL_ "GenSigTimeoutTime" BU_SG_REL_ VCU SG_ 1400 CF_Clu_RefDetMod 1000;
BA_REL_ "GenSigTimeoutTime" BU_SG_REL_ TMU SG_ 1400 CF_Clu_DriveModeSW 2000;
BA_REL_ "GenSigTimeoutTime" BU_SG_REL_ VCU SG_ 1400 CF_Clu_DriveModeSW 2000;
BA_REL_ "GenSigTimeoutTime" BU_SG_REL_ OBC SG_ 1403 CF_Vcu_CharInh 2000;
BA_REL_ "GenSigTimeoutTime" BU_SG_REL_ BMS SG_ 1403 CF_Vcu_CharStopOpt 2000;
BA_REL_ "GenSigTimeoutTime" BU_SG_REL_ BMS SG_ 1403 CF_Vcu_CharStopData 2000;
BA_REL_ "GenSigTimeoutTime" BU_SG_REL_ BMS SG_ 1403 CF_Vcu_ClimateOperPerm 2000;
BA_REL_ "GenSigTimeoutTime" BU_SG_REL_ CGW SG_ 1403 CF_Vcu_ClimateOperPerm 2000;
BA_REL_ "GenSigTimeoutTime" BU_SG_REL_ DATC SG_ 1403 CF_Vcu_ClimateOperPerm 2000;
BA_REL_ "GenSigTimeoutTime" BU_SG_REL_ TMU SG_ 1403 CF_Vcu_ClimateOperPerm 2000;
BA_REL_ "GenSigTimeoutTime" BU_SG_REL_ CGW SG_ 1403 CF_Vcu_Aircon_Finish 2000;
BA_REL_ "GenSigTimeoutTime" BU_SG_REL_ H_U SG_ 1403 CF_Vcu_Aircon_Finish 2000;
BA_REL_ "GenSigTimeoutTime" BU_SG_REL_ TMU SG_ 1403 CF_Vcu_Aircon_Finish 2000;
BA_REL_ "GenSigTimeoutTime" BU_SG_REL_ CGW SG_ 1403 CF_Vcu_AVN_Wakeup 2000;
BA_REL_ "GenSigTimeoutTime" BU_SG_REL_ DATC SG_ 1403 CF_Vcu_AVN_Wakeup 2000;
BA_REL_ "GenSigTimeoutTime" BU_SG_REL_ TMU SG_ 1403 CF_Vcu_AVN_Wakeup 2000;
BA_REL_ "GenSigTimeoutTime" BU_SG_REL_ BMS SG_ 1403 CF_Vcu_IG3RlyMd 2000;
BA_REL_ "GenSigTimeoutTime" BU_SG_REL_ CGW SG_ 1403 CF_Vcu_IG3RlyMd 2000;
BA_REL_ "GenSigTimeoutTime" BU_SG_REL_ DATC SG_ 1403 CF_Vcu_IG3RlyMd 2000;
BA_REL_ "GenSigTimeoutTime" BU_SG_REL_ H_U SG_ 1403 CF_Vcu_IG3RlyMd 2000;
BA_REL_ "GenSigTimeoutTime" BU_SG_REL_ LDC SG_ 1403 CF_Vcu_IG3RlyMd 2000;
BA_REL_ "GenSigTimeoutTime" BU_SG_REL_ OBC SG_ 1403 CF_Vcu_IG3RlyMd 2000;
BA_REL_ "GenSigTimeoutTime" BU_SG_REL_ TMU SG_ 1403 CF_Vcu_IG3RlyMd 2000;
BA_REL_ "GenSigTimeoutTime" BU_SG_REL_ BMS SG_ 1403 CF_Vcu_FailComfirmed 2000;
BA_REL_ "GenSigTimeoutTime" BU_SG_REL_ CGW SG_ 1403 CF_Vcu_FailComfirmed 2000;
BA_REL_ "GenSigTimeoutTime" BU_SG_REL_ DATC SG_ 1403 CF_Vcu_FailComfirmed 2000;
BA_REL_ "GenSigTimeoutTime" BU_SG_REL_ H_U SG_ 1403 CF_Vcu_FailComfirmed 2000;
BA_REL_ "GenSigTimeoutTime" BU_SG_REL_ OBC SG_ 1403 CF_Vcu_FailComfirmed 2000;
BA_REL_ "GenSigTimeoutTime" BU_SG_REL_ TMU SG_ 1403 CF_Vcu_FailComfirmed 2000;
BA_REL_ "GenSigTimeoutTime" BU_SG_REL_ BMS SG_ 1403 CF_Vcu_NoramlAriconCtr 2000;
BA_REL_ "GenSigTimeoutTime" BU_SG_REL_ CGW SG_ 1403 CF_Vcu_NoramlAriconCtr 2000;
BA_REL_ "GenSigTimeoutTime" BU_SG_REL_ DATC SG_ 1403 CF_Vcu_NoramlAriconCtr 2000;
BA_REL_ "GenSigTimeoutTime" BU_SG_REL_ H_U SG_ 1403 CF_Vcu_NoramlAriconCtr 2000;
BA_REL_ "GenSigTimeoutTime" BU_SG_REL_ OBC SG_ 1403 CF_Vcu_NoramlAriconCtr 2000;
BA_REL_ "GenSigTimeoutTime" BU_SG_REL_ TMU SG_ 1403 CF_Vcu_NoramlAriconCtr 2000;
BA_REL_ "GenSigTimeoutTime" BU_SG_REL_ BMS SG_ 1403 CF_Vcu_ProgCharInfo 2000;
BA_REL_ "GenSigTimeoutTime" BU_SG_REL_ CGW SG_ 1403 CF_Vcu_ProgCharInfo 2000;
BA_REL_ "GenSigTimeoutTime" BU_SG_REL_ BMS SG_ 1403 CF_Vuc_ProgCharWaitForCharInd 2000;
BA_REL_ "GenSigTimeoutTime" BU_SG_REL_ BMS SG_ 1403 CF_Vcu_CharCancel 2000;
BA_REL_ "GenSigTimeoutTime" BU_SG_REL_ BMS SG_ 1403 CF_Vcu_AirconCtr 2000;
BA_REL_ "GenSigTimeoutTime" BU_SG_REL_ CGW SG_ 1403 CF_Vcu_AirconCtr 2000;
BA_REL_ "GenSigTimeoutTime" BU_SG_REL_ DATC SG_ 1403 CF_Vcu_AirconCtr 2000;
BA_REL_ "GenSigTimeoutTime" BU_SG_REL_ DATC SG_ 1403 CF_Vcu_TempUnit4FATC 2000;
BA_REL_ "GenSigTimeoutTime" BU_SG_REL_ DATC SG_ 1403 CR_Vcu_TempSet4FATC 2000;
BA_REL_ "GenSigTimeoutTime" BU_SG_REL_ BMS SG_ 1403 CF_Vcu_MainRelayOnReq 2000;
BA_REL_ "GenSigTimeoutTime" BU_SG_REL_ BMS SG_ 1403 CF_Vcu_IG3Only 2000;
BA_REL_ "GenSigTimeoutTime" BU_SG_REL_ CGW SG_ 1403 CF_Vcu_IG3Only 2000;
BA_REL_ "GenSigTimeoutTime" BU_SG_REL_ H_U SG_ 1403 CF_Vcu_IG3Only 2000;
BA_REL_ "GenSigTimeoutTime" BU_SG_REL_ LDC SG_ 1403 CF_Vcu_IG3Only 2000;
BA_REL_ "GenSigTimeoutTime" BU_SG_REL_ MCU SG_ 1403 CF_Vcu_IG3Only 2000;
BA_REL_ "GenSigTimeoutTime" BU_SG_REL_ TMU SG_ 1403 CF_Vcu_IG3Only 2000;
BA_REL_ "GenSigTimeoutTime" BU_SG_REL_ BMS SG_ 1403 CF_Vcu_ProgCharStop 2000;
BA_REL_ "GenSigTimeoutTime" BU_SG_REL_ BMS SG_ 1403 CF_Vcu_ProgAirConInfo 2000;
BA_REL_ "GenSigTimeoutTime" BU_SG_REL_ CGW SG_ 1403 CF_Vcu_ProgAirConInfo 2000;
BA_REL_ "GenSigTimeoutTime" BU_SG_REL_ DATC SG_ 1403 CF_Vcu_ProgAirConInfo 2000;
BA_REL_ "GenSigTimeoutTime" BU_SG_REL_ CGW SG_ 1403 CF_Vcu_SbwWarnMsg 2000;
BA_REL_ "GenSigTimeoutTime" BU_SG_REL_ CGW SG_ 1403 CF_Vcu_SbwWarnSnd 2000;
BA_REL_ "GenSigTimeoutTime" BU_SG_REL_ CGW SG_ 1403 CF_Vcu_Invalid 2000;
BA_REL_ "GenSigTimeoutTime" BU_SG_REL_ CGW SG_ 1403 CR_Vcu_EcoPotential_Sport 2000;
BA_REL_ "GenSigTimeoutTime" BU_SG_REL_ TMU SG_ 1403 CR_Vcu_EcoPotential_Sport 2000;
BA_REL_ "GenSigTimeoutTime" BU_SG_REL_ CGW SG_ 1403 CR_Vcu_EcoPotential_Normal 2000;
BA_REL_ "GenSigTimeoutTime" BU_SG_REL_ TMU SG_ 1403 CR_Vcu_EcoPotential_Normal 2000;
BA_REL_ "GenSigTimeoutTime" BU_SG_REL_ CGW SG_ 1403 CR_Vcu_EcoPotential_Eco 2000;
BA_REL_ "GenSigTimeoutTime" BU_SG_REL_ TMU SG_ 1403 CR_Vcu_EcoPotential_Eco 2000;
BA_REL_ "GenSigTimeoutTime" BU_SG_REL_ CGW SG_ 1402 CR_Vcu_DepartSet1_Hour 2000;
BA_REL_ "GenSigTimeoutTime" BU_SG_REL_ TMU SG_ 1402 CR_Vcu_DepartSet1_Hour 2000;
BA_REL_ "GenSigTimeoutTime" BU_SG_REL_ CGW SG_ 1402 CR_Vcu_DepartSet1_Min 2000;
BA_REL_ "GenSigTimeoutTime" BU_SG_REL_ TMU SG_ 1402 CR_Vcu_DepartSet1_Min 2000;
BA_REL_ "GenSigTimeoutTime" BU_SG_REL_ CGW SG_ 1402 CF_Vcu_DepartSet1_Mon 2000;
BA_REL_ "GenSigTimeoutTime" BU_SG_REL_ TMU SG_ 1402 CF_Vcu_DepartSet1_Mon 2000;
BA_REL_ "GenSigTimeoutTime" BU_SG_REL_ CGW SG_ 1402 CF_Vcu_DepartSet1_Tue 2000;
BA_REL_ "GenSigTimeoutTime" BU_SG_REL_ TMU SG_ 1402 CF_Vcu_DepartSet1_Tue 2000;
BA_REL_ "GenSigTimeoutTime" BU_SG_REL_ CGW SG_ 1402 CF_Vcu_DepartSet1_Wed 2000;
BA_REL_ "GenSigTimeoutTime" BU_SG_REL_ TMU SG_ 1402 CF_Vcu_DepartSet1_Wed 2000;
BA_REL_ "GenSigTimeoutTime" BU_SG_REL_ CGW SG_ 1402 CF_Vcu_DepartSet1_Thu 2000;
BA_REL_ "GenSigTimeoutTime" BU_SG_REL_ TMU SG_ 1402 CF_Vcu_DepartSet1_Thu 2000;
BA_REL_ "GenSigTimeoutTime" BU_SG_REL_ CGW SG_ 1402 CF_Vcu_DepartSet1_Fri 2000;
BA_REL_ "GenSigTimeoutTime" BU_SG_REL_ TMU SG_ 1402 CF_Vcu_DepartSet1_Fri 2000;
BA_REL_ "GenSigTimeoutTime" BU_SG_REL_ CGW SG_ 1402 CF_Vcu_DepartSet1_Sat 2000;
BA_REL_ "GenSigTimeoutTime" BU_SG_REL_ TMU SG_ 1402 CF_Vcu_DepartSet1_Sat 2000;
BA_REL_ "GenSigTimeoutTime" BU_SG_REL_ CGW SG_ 1402 CF_Vcu_DepartSet1_Sun 2000;
BA_REL_ "GenSigTimeoutTime" BU_SG_REL_ TMU SG_ 1402 CF_Vcu_DepartSet1_Sun 2000;
BA_REL_ "GenSigTimeoutTime" BU_SG_REL_ CGW SG_ 1402 CF_Vcu_DepartSet1_PreCondSet 2000;
BA_REL_ "GenSigTimeoutTime" BU_SG_REL_ DATC SG_ 1402 CF_Vcu_DepartSet1_PreCondSet 2000;
BA_REL_ "GenSigTimeoutTime" BU_SG_REL_ TMU SG_ 1402 CF_Vcu_DepartSet1_PreCondSet 2000;
BA_REL_ "GenSigTimeoutTime" BU_SG_REL_ CGW SG_ 1402 CR_Vcu_DepartSet1_TempSet 2000;
BA_REL_ "GenSigTimeoutTime" BU_SG_REL_ TMU SG_ 1402 CR_Vcu_DepartSet1_TempSet 2000;
BA_REL_ "GenSigTimeoutTime" BU_SG_REL_ CGW SG_ 1402 CF_Vcu_DepartSet1_TempUnit 2000;
BA_REL_ "GenSigTimeoutTime" BU_SG_REL_ TMU SG_ 1402 CF_Vcu_DepartSet1_TempUnit 2000;
BA_REL_ "GenSigTimeoutTime" BU_SG_REL_ CGW SG_ 1402 CF_Vcu_DepartSet1_DefrostCtr 2000;
BA_REL_ "GenSigTimeoutTime" BU_SG_REL_ TMU SG_ 1402 CF_Vcu_DepartSet1_DefrostCtr 2000;
BA_REL_ "GenSigTimeoutTime" BU_SG_REL_ CGW SG_ 1402 CF_Vcu_DepartSet1_Enable 2000;
BA_REL_ "GenSigTimeoutTime" BU_SG_REL_ TMU SG_ 1402 CF_Vcu_DepartSet1_Enable 2000;
BA_REL_ "GenSigTimeoutTime" BU_SG_REL_ CGW SG_ 1402 CR_Vcu_DepartSet2_Hour 2000;
BA_REL_ "GenSigTimeoutTime" BU_SG_REL_ TMU SG_ 1402 CR_Vcu_DepartSet2_Hour 2000;
BA_REL_ "GenSigTimeoutTime" BU_SG_REL_ CGW SG_ 1402 CR_Vcu_DepartSet2_Min 2000;
BA_REL_ "GenSigTimeoutTime" BU_SG_REL_ TMU SG_ 1402 CR_Vcu_DepartSet2_Min 2000;
BA_REL_ "GenSigTimeoutTime" BU_SG_REL_ CGW SG_ 1402 CF_Vcu_DepartSet2_Mon 2000;
BA_REL_ "GenSigTimeoutTime" BU_SG_REL_ TMU SG_ 1402 CF_Vcu_DepartSet2_Mon 2000;
BA_REL_ "GenSigTimeoutTime" BU_SG_REL_ CGW SG_ 1402 CF_Vcu_DepartSet2_Tue 2000;
BA_REL_ "GenSigTimeoutTime" BU_SG_REL_ TMU SG_ 1402 CF_Vcu_DepartSet2_Tue 2000;
BA_REL_ "GenSigTimeoutTime" BU_SG_REL_ CGW SG_ 1402 CF_Vcu_DepartSet2_Wed 2000;
BA_REL_ "GenSigTimeoutTime" BU_SG_REL_ TMU SG_ 1402 CF_Vcu_DepartSet2_Wed 2000;
BA_REL_ "GenSigTimeoutTime" BU_SG_REL_ CGW SG_ 1402 CF_Vcu_DepartSet2_Thu 2000;
BA_REL_ "GenSigTimeoutTime" BU_SG_REL_ TMU SG_ 1402 CF_Vcu_DepartSet2_Thu 2000;
BA_REL_ "GenSigTimeoutTime" BU_SG_REL_ CGW SG_ 1402 CF_Vcu_DepartSet2_Fri 2000;
BA_REL_ "GenSigTimeoutTime" BU_SG_REL_ TMU SG_ 1402 CF_Vcu_DepartSet2_Fri 2000;
BA_REL_ "GenSigTimeoutTime" BU_SG_REL_ CGW SG_ 1402 CF_Vcu_DepartSet2_Sat 2000;
BA_REL_ "GenSigTimeoutTime" BU_SG_REL_ TMU SG_ 1402 CF_Vcu_DepartSet2_Sat 2000;
BA_REL_ "GenSigTimeoutTime" BU_SG_REL_ CGW SG_ 1402 CF_Vcu_DepartSet2_Sun 2000;
BA_REL_ "GenSigTimeoutTime" BU_SG_REL_ TMU SG_ 1402 CF_Vcu_DepartSet2_Sun 2000;
BA_REL_ "GenSigTimeoutTime" BU_SG_REL_ CGW SG_ 1402 CF_Vcu_DepartSet2_PreCondSet 2000;
BA_REL_ "GenSigTimeoutTime" BU_SG_REL_ DATC SG_ 1402 CF_Vcu_DepartSet2_PreCondSet 2000;
BA_REL_ "GenSigTimeoutTime" BU_SG_REL_ TMU SG_ 1402 CF_Vcu_DepartSet2_PreCondSet 2000;
BA_REL_ "GenSigTimeoutTime" BU_SG_REL_ CGW SG_ 1402 CR_Vcu_DepartSet2_TempSet 2000;
BA_REL_ "GenSigTimeoutTime" BU_SG_REL_ TMU SG_ 1402 CR_Vcu_DepartSet2_TempSet 2000;
BA_REL_ "GenSigTimeoutTime" BU_SG_REL_ CGW SG_ 1402 CF_Vcu_DepartSet2_TempUnit 2000;
BA_REL_ "GenSigTimeoutTime" BU_SG_REL_ TMU SG_ 1402 CF_Vcu_DepartSet2_TempUnit 2000;
BA_REL_ "GenSigTimeoutTime" BU_SG_REL_ CGW SG_ 1402 CF_Vcu_DepartSet2_DefrostCtr 2000;
BA_REL_ "GenSigTimeoutTime" BU_SG_REL_ TMU SG_ 1402 CF_Vcu_DepartSet2_DefrostCtr 2000;
BA_REL_ "GenSigTimeoutTime" BU_SG_REL_ CGW SG_ 1402 CF_Vcu_DepartSet2_Enable 2000;
BA_REL_ "GenSigTimeoutTime" BU_SG_REL_ TMU SG_ 1402 CF_Vcu_DepartSet2_Enable 2000;
BA_REL_ "GenSigTimeoutTime" BU_SG_REL_ LDC SG_ 1402 CF_VCU_IG3DrvSts 2000;
BA_REL_ "GenSigTimeoutTime" BU_SG_REL_ CGW SG_ 1402 CF_VCU_AuxBattChgUsmSts 2000;
BA_REL_ "GenSigTimeoutTime" BU_SG_REL_ LDC SG_ 1402 CF_VCU_AuxBattChgUsmSts 2000;
BA_REL_ "GenSigTimeoutTime" BU_SG_REL_ VCU SG_ 1399 Msg_Group_Num2 2000;
BA_REL_ "GenSigTimeoutTime" BU_SG_REL_ VCU SG_ 1399 Sect_NextWarn_Info 2000;
BA_REL_ "GenSigTimeoutTime" BU_SG_REL_ VCU SG_ 1399 NextWarn_Dist 2000;
BA_REL_ "GenSigTimeoutTime" BU_SG_REL_ VCU SG_ 1399 NextWarn_Type 2000;
BA_REL_ "GenSigTimeoutTime" BU_SG_REL_ VCU SG_ 1399 NextWarn_Spd 2000;
BA_REL_ "GenSigTimeoutTime" BU_SG_REL_ VCU SG_ 1399 Sect_NextWarn_AvgSpd 2000;
BA_REL_ "GenSigTimeoutTime" BU_SG_REL_ VCU SG_ 1399 Sect_NextWarn_Dist 2000;
BA_REL_ "GenSigTimeoutTime" BU_SG_REL_ VCU SG_ 1399 Sect_NextWarn_Spd 2000;
BA_REL_ "GenSigTimeoutTime" BU_SG_REL_ VCU SG_ 1398 Msg_Group_Num1 2000;
BA_REL_ "GenSigTimeoutTime" BU_SG_REL_ VCU SG_ 1398 SetDest_Status 2000;
BA_REL_ "GenSigTimeoutTime" BU_SG_REL_ VCU SG_ 1398 OffRoute_Status 2000;
BA_REL_ "GenSigTimeoutTime" BU_SG_REL_ VCU SG_ 1398 NextTurn_Type1 2000;
BA_REL_ "GenSigTimeoutTime" BU_SG_REL_ VCU SG_ 1398 NaviValidity 2000;
BA_REL_ "GenSigTimeoutTime" BU_SG_REL_ VCU SG_ 1398 NextTurn_Type2 2000;
BA_REL_ "GenSigTimeoutTime" BU_SG_REL_ VCU SG_ 1398 NextTurn_Dist1 2000;
BA_REL_ "GenSigTimeoutTime" BU_SG_REL_ VCU SG_ 1398 NextTurn_Dist2 2000;
BA_REL_ "GenSigTimeoutTime" BU_SG_REL_ VCU SG_ 1398 CurLink_Class 2000;
BA_REL_ "GenSigTimeoutTime" BU_SG_REL_ VCU SG_ 1398 CurRoad_Class 2000;
BA_REL_ "GenSigTimeoutTime" BU_SG_REL_ VCU SG_ 1398 CurLink_CntLane 2000;
BA_REL_ "GenSigTimeoutTime" BU_SG_REL_ VCU SG_ 1122 ISLA_SpdwOffst 0;
BA_REL_ "GenSigTimeoutTime" BU_SG_REL_ VCU SG_ 1122 ISLA_SwIgnoreReq 0;
BA_REL_ "GenSigTimeoutTime" BU_SG_REL_ VCU SG_ 1122 ISLA_SpdChgReq 0;
BA_REL_ "GenSigTimeoutTime" BU_SG_REL_ DATC SG_ 1392 CF_Ewp_FltStatus 2000;
BA_REL_ "GenSigTimeoutTime" BU_SG_REL_ MCU SG_ 1392 CF_Ewp_FltStatus 2000;
BA_REL_ "GenSigTimeoutTime" BU_SG_REL_ TMU SG_ 1392 CF_Ewp_FltStatus 2000;
BA_REL_ "GenSigTimeoutTime" BU_SG_REL_ VCU SG_ 1392 CF_Ewp_FltStatus 2000;
BA_REL_ "GenSigTimeoutTime" BU_SG_REL_ DATC SG_ 1392 CF_Ewp_ProtectMode 2000;
BA_REL_ "GenSigTimeoutTime" BU_SG_REL_ MCU SG_ 1392 CF_Ewp_ProtectMode 2000;
BA_REL_ "GenSigTimeoutTime" BU_SG_REL_ TMU SG_ 1392 CF_Ewp_ProtectMode 2000;
BA_REL_ "GenSigTimeoutTime" BU_SG_REL_ VCU SG_ 1392 CF_Ewp_ProtectMode 2000;
BA_REL_ "GenSigTimeoutTime" BU_SG_REL_ DATC SG_ 1392 CR_Ewp_ActRotSpd_rpm 2000;
BA_REL_ "GenSigTimeoutTime" BU_SG_REL_ MCU SG_ 1392 CR_Ewp_ActRotSpd_rpm 2000;
BA_REL_ "GenSigTimeoutTime" BU_SG_REL_ OBC SG_ 1392 CR_Ewp_ActRotSpd_rpm 2000;
BA_REL_ "GenSigTimeoutTime" BU_SG_REL_ TMU SG_ 1392 CR_Ewp_ActRotSpd_rpm 2000;
BA_REL_ "GenSigTimeoutTime" BU_SG_REL_ VCU SG_ 1392 CR_Ewp_ActRotSpd_rpm 2000;
BA_REL_ "GenSigTimeoutTime" BU_SG_REL_ LDC SG_ 1388 CF_OLdc_Rdy 2000;
BA_REL_ "GenSigTimeoutTime" BU_SG_REL_ TMU SG_ 1388 CF_OLdc_Rdy 2000;
BA_REL_ "GenSigTimeoutTime" BU_SG_REL_ VCU SG_ 1388 CF_OLdc_Rdy 2000;
BA_REL_ "GenSigTimeoutTime" BU_SG_REL_ LDC SG_ 1388 CF_OLdc_Controllable 2000;
BA_REL_ "GenSigTimeoutTime" BU_SG_REL_ TMU SG_ 1388 CF_OLdc_Controllable 2000;
BA_REL_ "GenSigTimeoutTime" BU_SG_REL_ VCU SG_ 1388 CF_OLdc_Controllable 2000;
BA_REL_ "GenSigTimeoutTime" BU_SG_REL_ CGW SG_ 1388 CF_OLdc_12VCharge 2000;
BA_REL_ "GenSigTimeoutTime" BU_SG_REL_ LDC SG_ 1388 CF_OLdc_12VCharge 2000;
BA_REL_ "GenSigTimeoutTime" BU_SG_REL_ NEMS SG_ 1388 CF_OLdc_12VCharge 2000;
BA_REL_ "GenSigTimeoutTime" BU_SG_REL_ TMU SG_ 1388 CF_OLdc_12VCharge 2000;
BA_REL_ "GenSigTimeoutTime" BU_SG_REL_ VCU SG_ 1388 CF_OLdc_12VCharge 2000;
BA_REL_ "GenSigTimeoutTime" BU_SG_REL_ CGW SG_ 1388 CF_OLdc_Pd_Stat 2000;
BA_REL_ "GenSigTimeoutTime" BU_SG_REL_ LDC SG_ 1388 CF_OLdc_Pd_Stat 2000;
BA_REL_ "GenSigTimeoutTime" BU_SG_REL_ MCU SG_ 1388 CF_OLdc_Pd_Stat 2000;
BA_REL_ "GenSigTimeoutTime" BU_SG_REL_ NEMS SG_ 1388 CF_OLdc_Pd_Stat 2000;
BA_REL_ "GenSigTimeoutTime" BU_SG_REL_ TMU SG_ 1388 CF_OLdc_Pd_Stat 2000;
BA_REL_ "GenSigTimeoutTime" BU_SG_REL_ MCU SG_ 1388 CF_Ldc_TmpLmt 2000;
BA_REL_ "GenSigTimeoutTime" BU_SG_REL_ CGW SG_ 1388 CF_OLdc_Srvlamp_Rqst 2000;
BA_REL_ "GenSigTimeoutTime" BU_SG_REL_ H_U SG_ 1388 CF_OLdc_Srvlamp_Rqst 2000;
BA_REL_ "GenSigTimeoutTime" BU_SG_REL_ LDC SG_ 1388 CF_OLdc_Srvlamp_Rqst 2000;
BA_REL_ "GenSigTimeoutTime" BU_SG_REL_ TMU SG_ 1388 CF_OLdc_Srvlamp_Rqst 2000;
BA_REL_ "GenSigTimeoutTime" BU_SG_REL_ vBDM SG_ 1388 CF_OLdc_Srvlamp_Rqst 2000;
BA_REL_ "GenSigTimeoutTime" BU_SG_REL_ AAF SG_ 1388 CF_OLdc_Flt 2000;
BA_REL_ "GenSigTimeoutTime" BU_SG_REL_ BMS SG_ 1388 CF_OLdc_Flt 2000;
BA_REL_ "GenSigTimeoutTime" BU_SG_REL_ CGW SG_ 1388 CF_OLdc_Flt 2000;
BA_REL_ "GenSigTimeoutTime" BU_SG_REL_ H_U SG_ 1388 CF_OLdc_Flt 2000;
BA_REL_ "GenSigTimeoutTime" BU_SG_REL_ LDC SG_ 1388 CF_OLdc_Flt 2000;
BA_REL_ "GenSigTimeoutTime" BU_SG_REL_ MCU SG_ 1388 CF_OLdc_Flt 2000;
BA_REL_ "GenSigTimeoutTime" BU_SG_REL_ NEMS SG_ 1388 CF_OLdc_Flt 2000;
BA_REL_ "GenSigTimeoutTime" BU_SG_REL_ OBC SG_ 1388 CF_OLdc_Flt 2000;
BA_REL_ "GenSigTimeoutTime" BU_SG_REL_ TMU SG_ 1388 CF_OLdc_Flt 2000;
BA_REL_ "GenSigTimeoutTime" BU_SG_REL_ VCU SG_ 1388 CF_OLdc_Flt 2000;
BA_REL_ "GenSigTimeoutTime" BU_SG_REL_ LDC SG_ 1388 CR_OLdc_ActCur_LS_A 2000;
BA_REL_ "GenSigTimeoutTime" BU_SG_REL_ MCU SG_ 1388 CR_OLdc_ActCur_LS_A 2000;
BA_REL_ "GenSigTimeoutTime" BU_SG_REL_ TMU SG_ 1388 CR_OLdc_ActCur_LS_A 2000;
BA_REL_ "GenSigTimeoutTime" BU_SG_REL_ CGW SG_ 1388 CR_OLdc_ActVol_LS_V 2000;
BA_REL_ "GenSigTimeoutTime" BU_SG_REL_ LDC SG_ 1388 CR_OLdc_ActVol_LS_V 2000;
BA_REL_ "GenSigTimeoutTime" BU_SG_REL_ MCU SG_ 1388 CR_OLdc_ActVol_LS_V 2000;
BA_REL_ "GenSigTimeoutTime" BU_SG_REL_ OBC SG_ 1388 CR_OLdc_ActVol_LS_V 2000;
BA_REL_ "GenSigTimeoutTime" BU_SG_REL_ TMU SG_ 1388 CR_OLdc_ActVol_LS_V 2000;
BA_REL_ "GenSigTimeoutTime" BU_SG_REL_ AAF SG_ 1388 CR_OLdc_Tmp 2000;
BA_REL_ "GenSigTimeoutTime" BU_SG_REL_ LDC SG_ 1388 CR_OLdc_Tmp 2000;
BA_REL_ "GenSigTimeoutTime" BU_SG_REL_ TMU SG_ 1388 CR_OLdc_Tmp 2000;
BA_REL_ "GenSigTimeoutTime" BU_SG_REL_ VCU SG_ 1388 CR_OLdc_Tmp 2000;
BA_REL_ "GenSigTimeoutTime" BU_SG_REL_ BMS SG_ 1148 CR_OBC_EWP_Rpm_Req_ForBMS 0;
BA_REL_ "GenSigTimeoutTime" BU_SG_REL_ CGW SG_ 1148 CR_OBC_EWP_Rpm_Req_ForBMS 0;
BA_REL_ "GenSigTimeoutTime" BU_SG_REL_ vBDM SG_ 1148 CR_OBC_EWP_Rpm_Req_ForBMS 0;
BA_REL_ "GenSigTimeoutTime" BU_SG_REL_ CGW SG_ 1148 CF_OBC_ChgStop_Alram 2000;
BA_REL_ "GenSigTimeoutTime" BU_SG_REL_ Dummy SG_ 1148 CF_OBC_ChrgRdySta 2000;
BA_REL_ "GenSigTimeoutTime" BU_SG_REL_ LDC SG_ 1148 CF_OBC_PwrLmtStatus 0;
BA_REL_ "GenSigTimeoutTime" BU_SG_REL_ BMS SG_ 1148 CF_OBC_InletFailStatus 2000;
BA_REL_ "GenSigTimeoutTime" BU_SG_REL_ CGW SG_ 1148 CF_OBC_InletFailStatus 2000;
BA_REL_ "GenSigTimeoutTime" BU_SG_REL_ TMU SG_ 1148 CF_OBC_InletFailStatus 2000;
BA_REL_ "GenSigTimeoutTime" BU_SG_REL_ VCU SG_ 1148 CF_OBC_InletFailStatus 2000;
BA_REL_ "GenSigTimeoutTime" BU_SG_REL_ BMS SG_ 1148 CF_OBC_InletLockStatus 2000;
BA_REL_ "GenSigTimeoutTime" BU_SG_REL_ CGW SG_ 1148 CF_OBC_InletLockStatus 2000;
BA_REL_ "GenSigTimeoutTime" BU_SG_REL_ TMU SG_ 1148 CF_OBC_InletLockStatus 2000;
BA_REL_ "GenSigTimeoutTime" BU_SG_REL_ VCU SG_ 1148 CF_OBC_InletLockStatus 2000;
BA_REL_ "GenSigTimeoutTime" BU_SG_REL_ CGW SG_ 1148 CF_OBC_InletAutoLockMode 0;
BA_REL_ "GenSigTimeoutTime" BU_SG_REL_ Dummy SG_ 1148 CF_OBC_PwmOnSta 2000;
BA_REL_ "GenSigTimeoutTime" BU_SG_REL_ BMS SG_ 1148 CF_OBC_EVSE_CluInCurMode 2000;
BA_REL_ "GenSigTimeoutTime" BU_SG_REL_ CGW SG_ 1148 CF_OBC_EVSE_CluInCurMode 2000;
BA_REL_ "GenSigTimeoutTime" BU_SG_REL_ BMS SG_ 1148 CF_OBC_ICCB_CluInCurMode 2000;
BA_REL_ "GenSigTimeoutTime" BU_SG_REL_ CGW SG_ 1148 CF_OBC_ICCB_CluInCurMode 2000;
BA_REL_ "GenSigTimeoutTime" BU_SG_REL_ BMS SG_ 1148 CF_OBC_AcPwrSysTyp 0;
BA_REL_ "GenSigTimeoutTime" BU_SG_REL_ BMS SG_ 1148 CR_Obc_DcMaxCurr 2000;
BA_REL_ "GenSigTimeoutTime" BU_SG_REL_ BMS SG_ 1148 CR_Obc_DCEstMaxPwr 20000;
BA_REL_ "GenSigTimeoutTime" BU_SG_REL_ CGW SG_ 1148 CR_OBC_Mains_Pwr 2000;
BA_REL_ "GenSigTimeoutTime" BU_SG_REL_ H_U SG_ 1148 CR_OBC_Mains_Pwr 2000;
BA_REL_ "GenSigTimeoutTime" BU_SG_REL_ TMU SG_ 1148 CR_OBC_Mains_Pwr 2000;
BA_REL_ "GenSigTimeoutTime" BU_SG_REL_ BMS SG_ 1378 HU_EV_WinterMode 0;
BA_REL_ "GenSigTimeoutTime" BU_SG_REL_ BMS SG_ 1378 HU_TgSoc_ScChg_Set 0;
BA_REL_ "GenSigTimeoutTime" BU_SG_REL_ BMS SG_ 1378 HU_TgSoc_QcChg_Set 0;
BA_REL_ "GenSigTimeoutTime" BU_SG_REL_ BMS SG_ 1378 HU_TgSoc_GPSChg_Set 0;
BA_REL_ "GenSigTimeoutTime" BU_SG_REL_ CCM SG_ 1032 CR_Cms_EVTransferType 2000;
BA_REL_ "GenSigTimeoutTime" BU_SG_REL_ BMS SG_ 1032 CR_Cms_PLCChgFaultSubCode 2000;
BA_REL_ "GenSigTimeoutTime" BU_SG_REL_ CCM SG_ 1032 CR_Cms_PLCChgFaultSubCode 2000;
BA_REL_ "GenSigTimeoutTime" BU_SG_REL_ MCU SG_ 1032 CR_Cms_PLCChgFaultSubCode 2000;
BA_REL_ "GenSigTimeoutTime" BU_SG_REL_ BMS SG_ 1032 CR_Cms_ChgEstPwr 2000;
BA_REL_ "GenSigTimeoutTime" BU_SG_REL_ CCM SG_ 1032 CR_Cms_ChgEstPwr 2000;
BA_REL_ "GenSigTimeoutTime" BU_SG_REL_ OBC SG_ 1032 CR_Cms_ChgEstPwr 2000;
BA_REL_ "GenSigTimeoutTime" BU_SG_REL_ IBU SG_ 1307 CF_Clu_TirePressUnitNValueSet 0;
BA_REL_ "GenSigTimeoutTime" BU_SG_REL_ vBDM SG_ 1307 CF_Clu_TirePressUnitNValueSet 0;
BA_REL_ "GenSigTimeoutTime" BU_SG_REL_ VCU SG_ 1307 CF_Clu_FuelGuideReset 0;
BA_REL_ "GenSigTimeoutTime" BU_SG_REL_ VCU SG_ 1307 CF_Clu_ECoastingNvalueSet 0;
BA_REL_ "GenSigTimeoutTime" BU_SG_REL_ DATC SG_ 1307 CF_Clu_USMReset 0;
BA_REL_ "GenSigTimeoutTime" BU_SG_REL_ IBU SG_ 1307 CF_Clu_USMReset 0;
BA_REL_ "GenSigTimeoutTime" BU_SG_REL_ SMK SG_ 1307 CF_Clu_USMReset 0;
BA_REL_ "GenSigTimeoutTime" BU_SG_REL_ TMU SG_ 1307 CF_Clu_USMReset 0;
BA_REL_ "GenSigTimeoutTime" BU_SG_REL_ VCU SG_ 1307 CF_Clu_USMReset 0;
BA_REL_ "GenSigTimeoutTime" BU_SG_REL_ iBAU SG_ 1307 CF_Clu_USMReset 0;
BA_REL_ "GenSigTimeoutTime" BU_SG_REL_ VCU SG_ 1307 CF_Clu_ECoastWarnNValueSet 0;
BA_REL_ "GenSigTimeoutTime" BU_SG_REL_ VCU SG_ 1307 CF_Clu_AuxBatChargeNValueSet 0;
BA_REL_ "GenSigTimeoutTime" BU_SG_REL_ VCU SG_ 1307 CF_Clu_ECoastCtrlNValueSet 0;
BA_REL_ "GenSigTimeoutTime" BU_SG_REL_ BMS SG_ 1029 CF_Cms_EvReady 0;
BA_REL_ "GenSigTimeoutTime" BU_SG_REL_ CCM SG_ 1029 CF_Cms_EvReady 0;
BA_REL_ "GenSigTimeoutTime" BU_SG_REL_ OBC SG_ 1029 CF_Cms_EvReady 0;
BA_REL_ "GenSigTimeoutTime" BU_SG_REL_ BMS SG_ 1029 CF_Cms_ReadyToCharge 2000;
BA_REL_ "GenSigTimeoutTime" BU_SG_REL_ CCM SG_ 1029 CF_Cms_ReadyToCharge 2000;
BA_REL_ "GenSigTimeoutTime" BU_SG_REL_ MCU SG_ 1029 CF_Cms_ReadyToCharge 2000;
BA_REL_ "GenSigTimeoutTime" BU_SG_REL_ OBC SG_ 1029 CF_Cms_ReadyToCharge 2000;
BA_REL_ "GenSigTimeoutTime" BU_SG_REL_ BMS SG_ 1029 CF_Cms_ChgComplete 2000;
BA_REL_ "GenSigTimeoutTime" BU_SG_REL_ CCM SG_ 1029 CF_Cms_ChgComplete 2000;
BA_REL_ "GenSigTimeoutTime" BU_SG_REL_ MCU SG_ 1029 CF_Cms_ChgComplete 2000;
BA_REL_ "GenSigTimeoutTime" BU_SG_REL_ OBC SG_ 1029 CF_Cms_ChgComplete 2000;
BA_REL_ "GenSigTimeoutTime" BU_SG_REL_ BMS SG_ 1029 CF_Cms_ChgFinished 2000;
BA_REL_ "GenSigTimeoutTime" BU_SG_REL_ CCM SG_ 1029 CF_Cms_ChgFinished 2000;
BA_REL_ "GenSigTimeoutTime" BU_SG_REL_ MCU SG_ 1029 CF_Cms_ChgFinished 2000;
BA_REL_ "GenSigTimeoutTime" BU_SG_REL_ OBC SG_ 1029 CF_Cms_ChgFinished 2000;
BA_REL_ "GenSigTimeoutTime" BU_SG_REL_ BMS SG_ 1029 CR_Cms_EVmaxCurrent 2000;
BA_REL_ "GenSigTimeoutTime" BU_SG_REL_ CCM SG_ 1029 CR_Cms_EVmaxCurrent 2000;
BA_REL_ "GenSigTimeoutTime" BU_SG_REL_ OBC SG_ 1029 CR_Cms_EVmaxCurrent 2000;
BA_REL_ "GenSigTimeoutTime" BU_SG_REL_ BMS SG_ 1029 CR_Cms_EVmaxVolt 2000;
BA_REL_ "GenSigTimeoutTime" BU_SG_REL_ CCM SG_ 1029 CR_Cms_EVmaxVolt 2000;
BA_REL_ "GenSigTimeoutTime" BU_SG_REL_ MCU SG_ 1029 CR_Cms_EVmaxVolt 2000;
BA_REL_ "GenSigTimeoutTime" BU_SG_REL_ OBC SG_ 1029 CR_Cms_EVmaxVolt 2000;
BA_REL_ "GenSigTimeoutTime" BU_SG_REL_ CCM SG_ 1029 CF_Cms_PreparationStatusForPLC 2000;
BA_REL_ "GenSigTimeoutTime" BU_SG_REL_ CCM SG_ 1029 CF_Cms_ReadyForCurDem 2000;
BA_REL_ "GenSigTimeoutTime" BU_SG_REL_ CCM SG_ 1029 CF_Cms_RlyWeldDetectionReq 2000;
BA_REL_ "GenSigTimeoutTime" BU_SG_REL_ CCM SG_ 1029 CF_Cms_WeldDctFinish 2000;
BA_REL_ "GenSigTimeoutTime" BU_SG_REL_ CCM SG_ 1029 CF_Cms_SessionStopReq 2000;
BA_REL_ "GenSigTimeoutTime" BU_SG_REL_ BMS SG_ 1030 CR_Cms_EVTargetVolt 2000;
BA_REL_ "GenSigTimeoutTime" BU_SG_REL_ CCM SG_ 1030 CR_Cms_EVTargetVolt 2000;
BA_REL_ "GenSigTimeoutTime" BU_SG_REL_ MCU SG_ 1030 CR_Cms_EVTargetVolt 2000;
BA_REL_ "GenSigTimeoutTime" BU_SG_REL_ BMS SG_ 1030 CR_Cms_EVTargetCurrent 2000;
BA_REL_ "GenSigTimeoutTime" BU_SG_REL_ CCM SG_ 1030 CR_Cms_EVTargetCurrent 2000;
BA_REL_ "GenSigTimeoutTime" BU_SG_REL_ MCU SG_ 1030 CR_Cms_EVTargetCurrent 2000;
VAL_ 1375 CF_Tmu_RoadType1 0 "No Data" 1 "Highway" 2 "Urban Highway" 3 "Route" 4 "National Support Local Road" 5 "Local Road" 6 "City Street" 7 "New Road" 8 "Ferry" 9 "Reserved" 10 "Reserved" 11 "Reserved" 12 "Reserved" 13 "Reserved" 14 "Reserved" 15 "Invalid" ;
VAL_ 1375 CF_Tmu_RoadType2 0 "No Data" 1 "Highway" 2 "Urban Highway" 3 "Route" 4 "National Support Local Road" 5 "Local Road" 6 "City Street" 7 "New Road" 8 "Ferry" 9 "Reserved" 10 "Reserved" 11 "Reserved" 12 "Reserved" 13 "Reserved" 14 "Reserved" 15 "Invalid" ;
VAL_ 1375 CF_Tmu_RoadType3 0 "No Data" 1 "Highway" 2 "Urban Highway" 3 "Route" 4 "National Support Local Road" 5 "Local Road" 6 "City Street" 7 "New Road" 8 "Ferry" 9 "Reserved" 10 "Reserved" 11 "Reserved" 12 "Reserved" 13 "Reserved" 14 "Reserved" 15 "Invalid" ;
VAL_ 1375 CF_Tmu_RoadType4 0 "No Data" 1 "Highway" 2 "Urban Highway" 3 "Route" 4 "National Support Local Road" 5 "Local Road" 6 "City Street" 7 "New Road" 8 "Ferry" 9 "Reserved" 10 "Reserved" 11 "Reserved" 12 "Reserved" 13 "Reserved" 14 "Reserved" 15 "Invalid" ;
VAL_ 1375 CF_Tmu_RoadType5 0 "No Data" 1 "Highway" 2 "Urban Highway" 3 "Route" 4 "National Support Local Road" 5 "Local Road" 6 "City Street" 7 "New Road" 8 "Ferry" 9 "Reserved" 10 "Reserved" 11 "Reserved" 12 "Reserved" 13 "Reserved" 14 "Reserved" 15 "Invalid" ;
VAL_ 820 MCB_CtlSta 0 "Not Activation" 1 "Activation" ;
VAL_ 820 MCB_DefSta 0 "Normal State" 1 "Fail" ;
VAL_ 1103 DATC_SwVer1 0 "0x00~0x7E:ASCII code value" 126 "0x00~0x7E:ASCII code value" 126 "Invalid" ;
VAL_ 1103 DATC_SwVer2 0 "0x00~0x7E:ASCII code value" 126 "0x00~0x7E:ASCII code value" 127 "Invalid" ;
VAL_ 1103 DATC_SwVer3 0 "0x00~0x7E:ASCII code value" 126 "0x00~0x7E:ASCII code value" 127 "Invalid" ;
VAL_ 1103 CF_Datc_Type2 255 "Error Indicator" ;
VAL_ 817 CF_Brk_Est_StkValid 0 "valid" 1 "invalid" ;
VAL_ 817 CF_Brk_DrvWhlSlipFlg 0 "No slip occurred at the driving wheels" 1 "Slip occurred at the driving wheels" ;
VAL_ 544 LAT_ACCEL_STAT 0 "Lateral acceleration signal is valid" 1 "Lateral acceleration signal is invalid" ;
VAL_ 544 LAT_ACCEL_DIAG 0 "Lateral acceleration signal is available" 1 "Lateral acceleration signal is not available temporarily" ;
VAL_ 544 LONG_ACCEL_STAT 0 "Longitudinal acceleration signal is valid" 1 "Longitudinal acceleration signal is invalid" ;
VAL_ 544 LONG_ACCEL_DIAG 0 "Longitudinal acceleration signal is available" 1 "Longitudinal acceleration signal is not available temporarily" ;
VAL_ 544 CYL_PRES_STAT 0 "Master cylinder pressure signal is valid" 1 "Master cylinder pressure signal is invalid" ;
VAL_ 544 CYL_PRESS_DIAG 0 "Master cylinder pressure signal is available" 1 "Master cylinder pressure is not available temporarily" ;
VAL_ 544 YAW_RATE_STAT 0 "Yaw rate sensor signal is valid" 1 "Yaw rate sensor signal is invalid" ;
VAL_ 544 YAW_RATE_DIAG 0 "Yaw rate signal is available" 1 "Yaw rate signal is not available temporarily" ;
VAL_ 544 CYL_PRES_FLAG 0 "Off" 1 "On" ;
VAL_ 1098 CF_Evp2_Stat 0 "EVP is not defective" 1 "EVP is defective" ;
VAL_ 1098 CF_Evp2_DefMode 0 "Nomal" 1 "Under Vacuum" 2 "Over Current" 3 "Low Current" 4 "Motor Short" 5 "Overrun" 6 "Reserved" 7 "Reserved" ;
VAL_ 1098 CF_Evp2_RunChk 0 "None" 1 "Master Running" 2 "Slave Running" 3 "Dual Running" 4 "Reserved" 5 "Reserved" 6 "Reserved" 7 "Reserved" ;
VAL_ 1369 CF_Gway_MemoryP1Cmd 0 "None" 1 "P1" ;
VAL_ 1369 CF_Gway_MemoryP2Cmd 0 "None" 1 "P2" ;
VAL_ 1369 CF_Gway_PBackP1Cmd 0 "None" 1 "P1" ;
VAL_ 1369 CF_Gway_PBackP2Cmd 0 "None" 1 "P2" ;
VAL_ 1369 CF_Gway_StrgWhlHeatedState 0 "Off" 1 "On" ;
VAL_ 1369 CF_Gway_PBackStopCmd 0 "Off" 1 "Stop" ;
VAL_ 1369 CF_Gway_StaticBendLhAct 0 "Off" 1 "On" ;
VAL_ 1369 CF_Gway_StaticBendRhAct 0 "Off" 1 "On" ;
VAL_ 1369 CF_Gway_DrvWdwStat 0 "Window Close" 1 "Window Open" ;
VAL_ 1369 CF_Gway_RLWdwState 0 "Window Close" 1 "Window Open" ;
VAL_ 1369 CF_Gway_RRWdwState 0 "Window Close" 1 "Window Open" ;
VAL_ 1369 CF_Gway_AstWdwStat 0 "Window Close" 1 "Window Open" ;
VAL_ 1369 CF_Gway_MemoryEnable 0 "Disable" 1 "Enable" ;
VAL_ 1369 CF_Gway_DrvUnlockState 0 "Lock" 1 "Unlock" ;
VAL_ 1369 CF_Gway_IMSBuzzer 0 "Off" 1 "On" ;
VAL_ 1369 C_HSWSSysStat 0 "Normal" 1 "System Fail" 2 "Reserved" 3 "Invalid" ;
VAL_ 1369 CF_Gway_WiperSwState 0 "Wiper Sw Off" 1 "Wiper Int or Auto Sw On (Refer to CF_Gway_RainSnsOption)" 2 "Wiper Low Sw On" 3 "Wiper High Sw On" ;
VAL_ 1369 CF_Gway_HCIMSPBackCmd 0 "None" 1 "0x001~0x97E:Health Care IMS DB Number(1~2430)" 2430 "0x001~0x97E:Health Care IMS DB Number(1~2430)" 4095 "Invalid" ;
VAL_ 1369 CF_Gway_DrvSeatBeltIND 0 "Off" 1 "Blinking" 2 "On" ;
VAL_ 1369 CF_Gway_AstSeatBeltIND 0 "Off" 1 "Blinking" 2 "On" ;
VAL_ 1369 CF_Gway_RCSeatBeltIND 0 "Off" 1 "Blinking" 2 "On" ;
VAL_ 1369 CF_Gway_RLSeatBeltIND 0 "Off" 1 "Blinking" 2 "On" ;
VAL_ 1369 CF_Gway_RRSeatBeltIND 0 "Off" 1 "Blinking" 2 "On" ;
VAL_ 1369 CF_Gway_RrWiperHighSw 0 "Off" 1 "On" ;
VAL_ 1369 CF_Gway_RrWiperLowSw 0 "Off" 1 "On" ;
VAL_ 1369 CF_Gway_Navigation_On_Off 0 "Off" 1 "On" 2 "Reserved" 3 "Invalid" ;
VAL_ 1369 CF_Gway_LanguageInfo 0 "Off" 1 "Korean" 2 "English(US)" 3 "English(UK)" 4 "Chinese(Mandarin)" 5 "Chinese(Cantonese)" 6 "French(EU)" 7 "Spanish(EU)" 8 "Arabic" 9 "Czech" 10 "Danish" 11 "German" 12 "Italian" 13 "Dutch" 14 "Polish" 15 "Portuguese" 16 "Russian" 17 "Slovak" 18 "Swedish" 19 "Turkish" 20 "French(US)" 21 "Spanish(US)" 22 "Reserved" 23 "Reserved" 24 "Reserved" 25 "Reserved" 26 "Reserved" 27 "Reserved" 28 "Reserved" 29 "Reserved" 30 "Reserved" 31 "Invalid" ;
VAL_ 1369 CF_Gway_Navi_On_Off 0 "OFF" 1 "ON" ;
VAL_ 1369 CF_Gway_WPCWarning 0 "Off" 1 "Phone Left Warning" 2 "Charging" 3 "Charging complete" 4 "Reserved" 5 "Reserved" 6 "Reserved" 7 "Invalid" ;
VAL_ 1369 CF_Gway_RWPCWarning 0 "Off" 1 "Phone Left Warning" 2 "Reserved" 3 "Reserved" 4 "Reserved" 5 "Reserved" 6 "Reserved" 7 "Invalid" ;
VAL_ 1369 CF_Gway_DedicatedDRLState 0 "Off" 1 "On(Dedicated DRL Option)" ;
VAL_ 1369 CF_Gway_SeatBeltWngBuz 0 "Off" 1 "On" ;
VAL_ 1364 HU_DATC_DrTempSetC 0 "Blank" 1 "LO" 2 "PHY=HEX*0.5 + 14" 3 "PHY=HEX*0.5 + 14" 4 "PHY=HEX*0.5 + 14" 5 "PHY=HEX*0.5 + 14" 6 "PHY=HEX*0.5 + 14" 7 "PHY=HEX*0.5 + 14" 8 "PHY=HEX*0.5 + 14" 9 "PHY=HEX*0.5 + 14" 10 "PHY=HEX*0.5 + 14" 11 "PHY=HEX*0.5 + 14" 12 "PHY=HEX*0.5 + 14" 13 "PHY=HEX*0.5 + 14" 14 "PHY=HEX*0.5 + 14" 15 "PHY=HEX*0.5 + 14" 16 "PHY=HEX*0.5 + 14" 17 "PHY=HEX*0.5 + 14" 18 "PHY=HEX*0.5 + 14" 19 "PHY=HEX*0.5 + 14" 20 "PHY=HEX*0.5 + 14" 21 "PHY=HEX*0.5 + 14" 22 "PHY=HEX*0.5 + 14" 23 "PHY=HEX*0.5 + 14" 24 "PHY=HEX*0.5 + 14" 25 "PHY=HEX*0.5 + 14" 26 "PHY=HEX*0.5 + 14" 27 "PHY=HEX*0.5 + 14" 28 "PHY=HEX*0.5 + 14" 29 "PHY=HEX*0.5 + 14" 30 "PHY=HEX*0.5 + 14" 31 "PHY=HEX*0.5 + 14" 32 "PHY=HEX*0.5 + 14" 33 "PHY=HEX*0.5 + 14" 34 "PHY=HEX*0.5 + 14" 35 "PHY=HEX*0.5 + 14" 36 "PHY=HEX*0.5 + 14" 37 "0x25~0xFD:Reserved" 253 "0x25~0xFD:Reserved" 254 "HI" 255 "Invalid" ;
VAL_ 1364 HU_DATC_DrTempSetF 0 "Blank" 1 "LO" 2 "PHY=HEX*1 + 56" 3 "PHY=HEX*1 + 56" 4 "PHY=HEX*1 + 56" 5 "PHY=HEX*1 + 56" 6 "PHY=HEX*1 + 56" 7 "PHY=HEX*1 + 56" 8 "PHY=HEX*1 + 56" 9 "PHY=HEX*1 + 56" 10 "PHY=HEX*1 + 56" 11 "PHY=HEX*1 + 56" 12 "PHY=HEX*1 + 56" 13 "PHY=HEX*1 + 56" 14 "PHY=HEX*1 + 56" 15 "PHY=HEX*1 + 56" 16 "PHY=HEX*1 + 56" 17 "PHY=HEX*1 + 56" 18 "PHY=HEX*1 + 56" 19 "PHY=HEX*1 + 56" 20 "PHY=HEX*1 + 56" 21 "PHY=HEX*1 + 56" 22 "PHY=HEX*1 + 56" 23 "PHY=HEX*1 + 56" 24 "PHY=HEX*1 + 56" 25 "PHY=HEX*1 + 56" 26 "PHY=HEX*1 + 56" 27 "PHY=HEX*1 + 56" 28 "PHY=HEX*1 + 56" 29 "PHY=HEX*1 + 56" 30 "PHY=HEX*1 + 56" 31 "PHY=HEX*1 + 56" 32 "PHY=HEX*1 + 56" 33 "PHY=HEX*1 + 56" 34 "PHY=HEX*1 + 56" 35 "PHY=HEX*1 + 56" 36 "PHY=HEX*1 + 56" 37 "0x25~0xFD:Reserved" 253 "0x25~0xFD:Reserved" 254 "HI" 255 "Invalid" ;
VAL_ 1364 HU_MTC_RlTempLevelReq 0 "Off Display" 1 "0 Level" 2 "1 Level" 3 "2 Level" 4 "3 Level" 5 "4 Level" 6 "5 Level" 7 "6 Level" 8 "Reserved" 9 "Reserved" 10 "Reserved" 11 "Reserved" 12 "Reserved" 13 "Reserved" 14 "Reserved" 9 "Invalid" ;
VAL_ 1364 HU_DATC_RlBlowerUpDn 0 "Reserved" 1 "Blower Up" 2 "Blower Down" 3 "Invalid" ;
VAL_ 1364 CF_Datc_DefLogic_USM_Set 0 "Default" 1 "Def Logic USM OFF" 2 "Def Logic USM ON" 3 "Invalid" ;
VAL_ 1364 CF_Datc_AutoFresh_USM_Set 0 "Default" 1 "Auto Ventilatioin USM OFF" 2 "Auto Ventilation USM ON" 3 "Invalid" ;
VAL_ 1364 DATC_AutoArClnUSMSet 0 "Default" 1 "Auto AirCleaning USM OFF" 2 "Auto AirCleaning USM ON" 3 "Invalid" ;
VAL_ 1364 HU_DATC_SyncSet 0 "Reserved" 1 "NOT SYNC" 2 "SYNC" 3 "Invalid" ;
VAL_ 1364 C_DATC_DTC_Mode 0 "OFF(Default)" 1 "Diagnosis Code Display" 2 "Reserved" 3 "Invalid" ;
VAL_ 1364 HU_DATC_RlTempSetC 0 "Blank" 1 "LO" 2 "PHY=HEX*0.5+14" 3 "PHY=HEX*0.5+14" 4 "PHY=HEX*0.5+14" 5 "PHY=HEX*0.5+14" 6 "PHY=HEX*0.5+14" 7 "PHY=HEX*0.5+14" 8 "PHY=HEX*0.5+14" 9 "PHY=HEX*0.5+14" 10 "PHY=HEX*0.5+14" 11 "PHY=HEX*0.5+14" 12 "PHY=HEX*0.5+14" 13 "PHY=HEX*0.5+14" 14 "PHY=HEX*0.5+14" 15 "PHY=HEX*0.5+14" 16 "PHY=HEX*0.5+14" 17 "PHY=HEX*0.5+14" 18 "PHY=HEX*0.5+14" 19 "PHY=HEX*0.5+14" 20 "PHY=HEX*0.5+14" 21 "PHY=HEX*0.5+14" 22 "PHY=HEX*0.5+14" 23 "PHY=HEX*0.5+14" 24 "PHY=HEX*0.5+14" 25 "PHY=HEX*0.5+14" 26 "PHY=HEX*0.5+14" 27 "PHY=HEX*0.5+14" 28 "PHY=HEX*0.5+14" 29 "PHY=HEX*0.5+14" 30 "PHY=HEX*0.5+14" 31 "PHY=HEX*0.5+14" 32 "PHY=HEX*0.5+14" 33 "PHY=HEX*0.5+14" 34 "PHY=HEX*0.5+14" 35 "PHY=HEX*0.5+14" 36 "PHY=HEX*0.5+14" 37 "0x25~0xFC:Reserved" 252 "0x25~0xFC:Reserved" 254 "HI" 255 "Invalid" ;
VAL_ 1364 HU_DATC_RlTempSetF 0 "Blank" 1 "LO" 2 "PHY=HEX*1+56" 3 "PHY=HEX*1+56" 4 "PHY=HEX*1+56" 5 "PHY=HEX*1+56" 6 "PHY=HEX*1+56" 7 "PHY=HEX*1+56" 8 "PHY=HEX*1+56" 9 "PHY=HEX*1+56" 10 "PHY=HEX*1+56" 11 "PHY=HEX*1+56" 12 "PHY=HEX*1+56" 13 "PHY=HEX*1+56" 14 "PHY=HEX*1+56" 15 "PHY=HEX*1+56" 16 "PHY=HEX*1+56" 17 "PHY=HEX*1+56" 18 "PHY=HEX*1+56" 19 "PHY=HEX*1+56" 20 "PHY=HEX*1+56" 21 "PHY=HEX*1+56" 22 "PHY=HEX*1+56" 23 "PHY=HEX*1+56" 24 "PHY=HEX*1+56" 25 "PHY=HEX*1+56" 26 "PHY=HEX*1+56" 27 "PHY=HEX*1+56" 28 "PHY=HEX*1+56" 29 "PHY=HEX*1+56" 30 "PHY=HEX*1+56" 31 "PHY=HEX*1+56" 32 "PHY=HEX*1+56" 33 "PHY=HEX*1+56" 34 "PHY=HEX*1+56" 35 "PHY=HEX*1+56" 36 "PHY=HEX*1+56" 37 "0x25~0xFC:Reserved" 252 "0x25~0xFC:Reserved" 254 "HI" 255 "Invalid" ;
VAL_ 1363 CF_ChaDrSwFrt 0 "Close" 1 "Open" ;
VAL_ 1363 CF_ChaDrSwRr 0 "Close" 1 "Open" ;
VAL_ 1363 C_BAlarmState 0 "Off" 1 "DisArm" 2 "Arm" 3 "PreArm" 4 "ArmWait" 5 "ArmHold(Trunk)" 6 "ReArm" 7 "AutoLockTimer1" 8 "AutoLockTimer2" 9 "Alarm" 10 "Default" 11 "AutoLockTimer3(Tailgate)" ;
VAL_ 1363 CF_Gway_AutoLightValue 0 "Off" 1 "Night" ;
VAL_ 1363 CF_Gway_RRDrSw 0 "Close" 1 "Open" ;
VAL_ 1363 CF_Gway_RLDrSw 0 "Close" 1 "Open" ;
VAL_ 1363 CF_Gway_IntTailAct 0 "Off" 1 "On" ;
VAL_ 1363 CF_Gway_SMKRKECmd 0 "None" 1 "Lock" 2 "Unlock" 3 "Trunk(or Tail Gate)" 4 "Panic" 5 "Panic Stop" 6 "Two Step Unlock Warning" ;
VAL_ 1363 CF_Gway_SJBDeliveryMode 0 "Before Delivery(Welcome Off)" 1 "After Delivery(Welcome On)" ;
VAL_ 1358 NV_EstDist_F 0 "Physical distance" 1 "Physical distance" 2 "Physical distance" 3 "Physical distance" 4 "Physical distance" 5 "Physical distance" 6 "Physical distance" 7 "Physical distance" 8 "Physical distance" 9 "Physical distance" 10 "Reserved" 11 "Reserved" 12 "Reserved" 13 "Reserved" 14 "Reserved" 15 "Invalid" ;
VAL_ 1358 NV_EstDist_Unit 0 "Meter" 1 "Kilometer" 2 "Mile" 3 "Feet" 4 "Yard" 5 "Reserved" 6 "Reserved" 7 "Reserved" 8 "Reserved" 9 "Reserved" 10 "Reserved" 11 "Reserved" 12 "Reserved" 13 "Reserved" 14 "Reserved" 15 "Invalid" ;
VAL_ 1358 NV_EstDist_I 0 "0" 65534 "65534" 65535 "Invalid" ;
VAL_ 1117 CR_Tmu_DrvDistance1 0 "0x0~0x3FE:Refer to Fomula" 1022 "0x0~0x3FE:Refer to Fomula" 1023 "Invalid" ;
VAL_ 1117 CR_Tmu_DrvDistance2 0 "0x0~0x3FE:Refer to Fomula" 1022 "0x0~0x3FE:Refer to Fomula" 1023 "Invalid" ;
VAL_ 1117 CR_Tmu_DrvDistance3 0 "0x0~0x3FE:Refer to Fomula" 1022 "0x0~0x3FE:Refer to Fomula" 1023 "Invalid" ;
VAL_ 1117 CR_Tmu_DrvDistance4 0 "0x0~0x3FE:Refer to Fomula" 1022 "0x0~0x3FE:Refer to Fomula" 1023 "Invalid" ;
VAL_ 1117 CR_Tmu_DrvDistance5 0 "0x0~0x3FE:Refer to Fomula" 1022 "0x0~0x3FE:Refer to Fomula" 1023 "Invalid" ;
VAL_ 1117 CR_Tmu_DrvDistance6 0 "0x0~0x3FE:Refer to Fomula" 1022 "0x0~0x3FE:Refer to Fomula" 1023 "Invalid" ;
VAL_ 1116 DATC_RrDefSw 0 "Off" 1 "On" ;
VAL_ 1116 C_SteeringWheelHeaterSW 0 "OFF" 1 "ON" ;
VAL_ 1116 CR_Datc_DRSeatWheel_USM_State 0 "NOT APPLY" 1 "OFF" 2 "ON" 3 "Invalid" ;
VAL_ 1116 CR_Datc_DRSeatHeat_USM_State 0 "NOT APPLY" 1 "OFF" 2 "ON" 3 "Invalid" ;
VAL_ 1116 DATC_WdwClsReq 0 "Default" 1 "Close Request" 2 "Reserved" 3 "Invalid" ;
VAL_ 1116 DATC_ArClnSmblTyp 0 "Default" 1 "Blank (Initial Display)" 2 "Wood" 3 "Wood & Fixed Arrow" 4 "Wood & Rotating Arrow" 5 "White Wood & Fixed Arrow" 6 "White Wood & Rotating Arrow" 7 "Invalid" ;
VAL_ 1116 DATC_ArClnStepClr 0 "Default (Initial Value)" 1 "Mono Color" 2 "Blue Color" 3 "Green Color" 4 "Orange Color" 5 "Red Color" 6 "Yellow Color" 7 "Reserved" 8 "Reserved" 9 "Reserved" 10 "Reserved" 11 "Reserved" 12 "Reserved" 13 "Reserved" 14 "Gray Color (Deactivate)" 15 "Invalid" ;
VAL_ 1116 DATC_ArClnSysOSD 0 "Default (Initial Value)" 1 "AirCleaning SYS ON" 2 "AirCleaning SYS OFF" 3 "High Dust AirCleaning ON" 4 "High Dust AirCleaning OFF" 5 "Sensor AirCleaning SYS ON & Closing Window" 6 "Opening Warning" 7 "Reserved" 8 "Reserved" 9 "Reserved" 10 "Reserved" 11 "Reserved" 12 "Reserved" 13 "Reserved" 14 "Reserved" 15 "Invalid" ;
VAL_ 16 CF_Acu_CshAct 0 "Crash Active time is expired (Crash is Inactive)" 1 "Crash Active time started (Crash Detected)" ;
VAL_ 16 ACU_CrshInfo 0 "Received ESC feedback signal" 1 "Crash output signal not issued" 2 "Crash output signal issued" ;
VAL_ 1359 HU_DATC_DrTempUpDn 0 "Reserved" 1 "Temp Up" 2 "Temp Down" 3 "Invalid" ;
VAL_ 1359 HU_DATC_PsTempUpDn 0 "Off" 1 "Temp Up" 2 "Temp Down" 3 "Invalid" ;
VAL_ 1359 HU_DATC_RLTempUpDn 0 "Reserved" 1 "Temp Up" 2 "Temp Down" 3 "Invalid" ;
VAL_ 1359 HU_DATC_RrTempUpDn 0 "Off" 1 "Temp Up" 2 "Temp Down" 3 "Invalid" ;
VAL_ 1359 HU_DATC_MainBlower 0 "DATC off" 1 "0 level" 2 "1 level" 3 "2 level" 4 "3 level" 5 "4 level" 6 "5 level" 7 "6 level" 8 "7 level" 9 "8 level" 15 "Invalid" ;
VAL_ 1359 HU_DATC_RearBlower 0 "OFF" 1 "0 Level" 2 "1 Level" 3 "2 Level" 4 "3 Level" 5 "4 Level" 6 "5 Level" 7 "6 Level" 8 "7 Level" 9 "8 Level" 15 "Invalid" ;
VAL_ 1359 HU_DATCRearPsModeSet 0 "OFF" 1 "VENT" 2 "B/L" 3 "FLOOR" ;
VAL_ 1359 HU_DATC_FrontModeSet 0 "reserved" 1 "VENT" 2 "BL" 3 "FLOOR" 4 "MIX" 15 "Invalid" ;
VAL_ 1359 HU_DATC_RearModeSet 0 "OFF" 1 "VENT" 2 "B/L" 3 "FLOOR" ;
VAL_ 1359 HU_DATC_AutoSet 0 "reserved" 1 "AUTO ON" 2 "reserved" 3 "Invalid" ;
VAL_ 1359 HU_DATC_OffReq 0 "None" 1 "Request (OFF)" 2 "Reserved" 3 "Invalid" ;
VAL_ 1359 HU_DATC_IntakeSet 0 "REC Off(Fresh On)" 1 "REC ON(Fresh Off)" 2 "reserved" 3 "Invalid" ;
VAL_ 1359 HU_DATC_RearOnOffSet 0 "Rear Off" 1 "Rear On" 2 "reserved" 3 "Invalid" ;
VAL_ 1359 HU_DATC_AcSet 0 "AC Off" 1 "AC ON" 2 "reserved" 3 "Invalid" ;
VAL_ 1359 HU_DATC_FrontDefog 0 "Defog Off" 1 "Defog On" 2 "reserved" 3 "Invalid" ;
VAL_ 1359 HU_DATC_RearDefog 0 "Off" 1 "Defog On" 2 "reserved" 3 "Invalid" ;
VAL_ 1359 HU_DATC_CO2Set 0 "Function Off" 1 "Function On" 2 "reserved" 3 "Invalid" ;
VAL_ 1359 DATC_SmartVentOnOffSet 0 "Function Off" 1 "Function On" 2 "reserved" 3 "Invalid" ;
VAL_ 1359 DATC_ADSOnOffSet 0 "Function Off" 1 "Function On" 2 "reserved" 3 "Invalid" ;
VAL_ 1359 HU_Datc_RearAutoDisp 0 "AUTO Off" 1 "AUTO On" 2 "Not Used" 3 "Invalid" ;
VAL_ 1359 HU_Datc_RearOffDisp 0 "OFF" 1 "REAR Normal Display" 2 "REAR OFF Display" 3 "Invalid" ;
VAL_ 1359 HU_DATC_MainBlowerUpDn 0 "reserved" 1 "Up" 2 "Down" 3 "Invalid" ;
VAL_ 1359 HU_DATC_AirCleaningSet 0 "Air Cleaning System Off" 1 "Air Cleaning System On" 2 "Air Cleaning System Not Support" 3 "Invalid" ;
VAL_ 1118 CR_Tmu_DrvDistance7 0 "0x0~0x3FE:Refer to Fomula" 1022 "0x0~0x3FE:Refer to Fomula" 1023 "Invalid" ;
VAL_ 1118 CR_Tmu_DrvDistance8 0 "0x0~0x3FE:Refer to Fomula" 1022 "0x0~0x3FE:Refer to Fomula" 1023 "Invalid" ;
VAL_ 1118 CR_Tmu_DrvDistance9 0 "0x0~0x3FE:Refer to the Fomular" 1022 "0x0~0x3FE:Refer to the Fomular" 1023 "Invalid" ;
VAL_ 1118 CR_Tmu_DrvDistance10 0 "0x0~0x3FE:Refer to Fomula" 1022 "0x0~0x3FE:Refer to Fomula" 1023 "Invalid" ;
VAL_ 1354 CF_BMS_Ewp1_FaultStatus 0 "Normal" 1 "Fault Status" ;
VAL_ 1354 CF_BMS_Ewp1_ProtectMode 0 "Normal" 1 "EWP Protection Mode" ;
VAL_ 1354 CF_BMS_Ewp1_Short_Circuit 0 "Normal" 1 "Abnormal" ;
VAL_ 1354 CF_BMS_Ewp1_GateDrvUVOV 0 "Normal" 1 "Abnormal" ;
VAL_ 1354 CF_BMS_Ewp1_SpeedError 0 "Normal" 1 "Abnormal" ;
VAL_ 1354 CF_BMS_Ewp1_OverTemp 0 "Normal" 1 "Abnormal" ;
VAL_ 1354 CF_BMS_Ewp1_WarnTemp 0 "Normal" 1 "Abnormal" ;
VAL_ 1354 CF_BMS_Ewp1_LowCurrent 0 "Normal" 1 "Abnormal" ;
VAL_ 1354 CF_BMS_Ewp1_OverCurrent 0 "Normal" 1 "Abnormal" ;
VAL_ 1354 CF_BMS_Ewp1_UnderVoltage 0 "Normal" 1 "Abnormal" ;
VAL_ 1354 CF_BMS_Ewp1_OverVoltage 0 "Normal" 1 "Abnormal" ;
VAL_ 1115 CF_Vcu_AvnDteCalc 0 "Display DTE value" 1 "Display 'Recalculating'" ;
VAL_ 1115 CF_Vcu_DriveMode 0 "Eco mode" 1 "Normal mode" 2 "Sport mode" 3 "Eco+ mode" 4 "Rest mode" 5 "Reserved" 6 "Reserved" 7 "Invalid" ;
VAL_ 1115 CF_Vcu_BrkLampSta 0 "Brake Lamp Switch Off" 1 "Brake Lamp Switch On" ;
VAL_ 1353 BAT_SNSR_State 0 "Nomal State" 1 "Implausible State" ;
VAL_ 1353 BAT_SNSR_Invalid 0 "Valid Condition" 1 "Invalid Condition" ;
VAL_ 1353 BAT_SNSR_Error 0 "Operating correctly" 1 "Response error" ;
VAL_ 265 CF_Vcu_WakeupReq 0 "Not Reques" 1 "Requested" ;
VAL_ 265 CF_Vcu_HvIntlock_Req 0 "HVIL Reaction Not Request" 1 "HVIL Reaction Request" ;
VAL_ 265 CF_Vcu_BmsEwpOpReq 0 "EWP Operation Not Request" 1 "EWP Operation Request" ;
VAL_ 265 CR_Vcu_SchedChgSt_Day 0 "Sun" 1 "Mon" 2 "Tue" 3 "Wed" 4 "Thu" 5 "Fri" 6 "Sat" 7 "Invalid" ;
VAL_ 265 CR_Vcu_SchedChgSt_Hr 0 "0~23" 1 "0~23" 2 "0~23" 3 "0~23" 4 "0~23" 5 "0~23" 6 "0~23" 7 "0~23" 8 "0~23" 9 "0~23" 10 "0~23" 11 "0~23" 12 "0~23" 13 "0~23" 14 "0~23" 15 "0~23" 16 "0~23" 17 "0~23" 18 "0~23" 19 "0~23" 20 "0~23" 21 "0~23" 22 "0~23" 23 "0~23" 24 "Reserved" 25 "Reserved" 26 "Reserved" 27 "Reserved" 28 "Reserved" 29 "Reserved" 30 "Reserved" 31 "Invalid" ;
VAL_ 265 CR_Vcu_SchedChgSt_Min 0 "0~59" 1 "0~59" 2 "0~59" 3 "0~59" 4 "0~59" 5 "0~59" 6 "0~59" 7 "0~59" 8 "0~59" 9 "0~59" 10 "0~59" 11 "0~59" 12 "0~59" 13 "0~59" 14 "0~59" 15 "0~59" 16 "0~59" 17 "0~59" 18 "0~59" 19 "0~59" 20 "0~59" 21 "0~59" 22 "0~59" 23 "0~59" 24 "0~59" 25 "0~59" 26 "0~59" 27 "0~59" 28 "0~59" 29 "0~59" 30 "0~59" 31 "0~59" 32 "0~59" 33 "0~59" 34 "0~59" 35 "0~59" 36 "0~59" 37 "0~59" 38 "0~59" 39 "0~59" 40 "0~59" 41 "0~59" 42 "0~59" 43 "0~59" 44 "0~59" 45 "0~59" 46 "0~59" 47 "0~59" 48 "0~59" 49 "0~59" 50 "0~59" 51 "0~59" 52 "0~59" 53 "0~59" 54 "0~59" 55 "0~59" 56 "0~59" 57 "0~59" 58 "0~59" 59 "0~59" 60 "Reserved" 61 "Reserved" 62 "Reserved" 63 "Invalid" ;
VAL_ 265 CR_Vcu_SchedChgEnd_Day 0 "Sun" 1 "Mon" 2 "Tue" 3 "Wed" 4 "Thu" 5 "Fri" 6 "Sat" 7 "Invalid" ;
VAL_ 265 CR_Vcu_SchedChgEnd_Hr 0 "0~23" 1 "0~23" 2 "0~23" 3 "0~23" 4 "0~23" 5 "0~23" 6 "0~23" 7 "0~23" 8 "0~23" 9 "0~23" 10 "0~23" 11 "0~23" 12 "0~23" 13 "0~23" 14 "0~23" 15 "0~23" 16 "0~23" 17 "0~23" 18 "0~23" 19 "0~23" 20 "0~23" 21 "0~23" 22 "0~23" 23 "0~23" 24 "Reserved" 25 "Reserved" 26 "Reserved" 27 "Reserved" 28 "Reserved" 29 "Reserved" 30 "Reserved" 31 "Invalid" ;
VAL_ 265 CR_Vcu_SchedChgEnd_Min 0 "0~59" 1 "0~59" 2 "0~59" 3 "0~59" 4 "0~59" 5 "0~59" 6 "0~59" 7 "0~59" 8 "0~59" 9 "0~59" 10 "0~59" 11 "0~59" 12 "0~59" 13 "0~59" 14 "0~59" 15 "0~59" 16 "0~59" 17 "0~59" 18 "0~59" 19 "0~59" 20 "0~59" 21 "0~59" 22 "0~59" 23 "0~59" 24 "0~59" 25 "0~59" 26 "0~59" 27 "0~59" 28 "0~59" 29 "0~59" 30 "0~59" 31 "0~59" 32 "0~59" 33 "0~59" 34 "0~59" 35 "0~59" 36 "0~59" 37 "0~59" 38 "0~59" 39 "0~59" 40 "0~59" 41 "0~59" 42 "0~59" 43 "0~59" 44 "0~59" 45 "0~59" 46 "0~59" 47 "0~59" 48 "0~59" 49 "0~59" 50 "0~59" 51 "0~59" 52 "0~59" 53 "0~59" 54 "0~59" 55 "0~59" 56 "0~59" 57 "0~59" 58 "0~59" 59 "0~59" 59 "Reserved" 60 "Reserved" 61 "Reserved" 62 "Reserved" 63 "Inavlid" ;
VAL_ 265 CF_Vcu_3WayValInhibitToMcu 0 "Disable" 1 "Enable" ;
VAL_ 265 CF_Vcu_EwpForcedOperToMcu 0 "OFF" 1 "EWP Forced Operating" ;
VAL_ 265 CF_Vcu_EwpCoolantDiagEnbToMcu 0 "Disable" 1 "Enable" ;
VAL_ 265 CF_Vcu_EwpCoolantDispToMcu 0 "Normal" 1 "Insufficient" ;
VAL_ 265 CF_Vcu_PARKCMD 0 "Wait command" 1 "Park command" 2 "NotPark command" 3 "Reserved" ;
VAL_ 1346 CR_Bms_HeatPwrSum_Wh 255 "Error" ;
VAL_ 1346 CF_Bms_Notify_Pilotfail 0 "Normal" 1 "Notify Pilotline Fail" ;
VAL_ 1346 CF_Bms_PShiftForCharging 0 "Normal" 1 "P Shift For Charging" ;
VAL_ 1346 CF_Bms_FstEvseFltAlram 0 "Normal" 1 "Alraming By QCS Fault" ;
VAL_ 1104 CF_Clu_RheostatLevel 0 "Reserved" 1 "Step 1" 2 "Step 2" 3 "Step 3" 4 "Step 4" 5 "Step 5" 6 "Step 6" 7 "Step 7" 8 "Step 8" 9 "Step 9" 10 "Step 10" 11 "Step 11" 12 "Step 12" 13 "Step 13" 14 "Step 14" 15 "Step 15" 16 "Step 16" 17 "Step 17" 18 "Step 18" 19 "Step 19" 20 "Step 20 (Reset Value)" 21 "Step 21 (Detent)" ;
VAL_ 1104 CF_Clu_CruiseSwState 0 "Idle Position" 1 "Resume/Plus" 2 "Set/Minus" 3 "Time gap (Distance, SCC only)" 4 "ACC/SCC cancel" 7 "Reserved" ;
VAL_ 1104 CF_Clu_CruiseSwMain 0 "Off" 1 "On" ;
VAL_ 1104 CF_GWAY_Detentout 0 "Detent Off" 1 "Detent On" ;
VAL_ 1104 CF_Clu_SldMainSW 0 "Off" 1 "On" ;
VAL_ 1104 CF_Clu_SPEED_UNIT 0 "km/h" 1 "MPH" ;
VAL_ 1104 AVH_STAT 0 "No apply" 1 "Vehicle is held by the service brake" 2 "Being released" 3 "Reserved" ;
VAL_ 1345 CF_Gway_IGNSw 0 "Key Off" 1 "Key In" 2 "ACC" 3 "IGN" 4 "Start" 7 "B-CAN Time-out" ;
VAL_ 1345 CF_Gway_RKECmd 0 "None" 1 "Lock" 2 "Unlock" 3 "Panic" 4 "Panic Stop" 5 "Trunk(Or Tail Gate)" 6 "Reserved" 7 "Reserved" ;
VAL_ 1345 CF_Gway_DrvKeyLockSw 0 "Off" 1 "lock" ;
VAL_ 1345 CF_Gway_DrvKeyUnlockSw 0 "Off" 1 "Unlock" ;
VAL_ 1345 CF_Gway_DrvDrSw 0 "Close" 1 "Open" 3 "B-CAN Time-out" ;
VAL_ 1345 CF_Gway_DrvSeatBeltSw 0 "Unbelted" 1 "Belted" 3 "B-CAN Time-out" ;
VAL_ 1345 CF_Gway_TrunkTgSw 0 "Trunk Close" 1 "Trunk Open" 3 "B-CAN Time-out" ;
VAL_ 1345 CF_Gway_AstSeatBeltSw 0 "Unbelted" 1 "Belted" 3 "B-CAN Time-out" ;
VAL_ 1345 CF_Gway_SMKOption 0 "Non SMK Option" 1 "SMK Option" ;
VAL_ 1345 CF_Gway_HoodSw 0 "Hood Close" 1 "Hood Open" 3 "B-CAN Time-out" ;
VAL_ 1345 CF_Gway_TurnSigLh 0 "Off" 1 "On" 3 "B-CAN Time-out" ;
VAL_ 1345 CF_Gway_WiperIntT 0 "Step1(SLOW)" 1 "Step2" 2 "Step3" 3 "Step4" 4 "Step5(FAST)" ;
VAL_ 1345 CF_Gway_WiperIntSw 0 "Off" 1 "On" ;
VAL_ 1345 CF_Gway_WiperLowSw 0 "Off" 1 "On" ;
VAL_ 1345 CF_Gway_WiperHighSw 0 "Off" 1 "On" ;
VAL_ 1345 CF_Gway_WiperAutoSw 0 "Off" 1 "On" ;
VAL_ 1345 CF_Gway_RainSnsState 0 "OFF" 1 "Rain Detected" 2 "Low" 3 "High" 4 "Fault 1" 5 "Fault 2" 6 "Fault 3" 7 "Reserved" ;
VAL_ 1345 CF_Gway_HeadLampLow 0 "Off" 1 "On" ;
VAL_ 1345 CF_Gway_HeadLampHigh 0 "Off" 1 "On" ;
VAL_ 1345 CF_Gway_HazardSw 0 "Off" 1 "On" 3 "B-CAN Time-out" ;
VAL_ 1345 CF_Gway_AstDrSw 0 "Close" 1 "Open" ;
VAL_ 1345 CF_Gway_DefoggerRly 0 "Off" 1 "On" ;
VAL_ 1345 CF_Gway_ALightStat 0 "OFF" 1 "ON" ;
VAL_ 1345 CF_Gway_LightSwState 0 "Light Sw Off" 1 "Tail Sw On" 2 "HeadLamp Low Sw On" 3 "AutoLight Sw On" ;
VAL_ 1345 CF_Gway_Frt_Fog_Act 0 "OFF" 1 "ON" ;
VAL_ 1345 CF_Gway_TSigLHSw 0 "Off" 1 "On" ;
VAL_ 1345 CF_Gway_TSigRHSw 0 "Off" 1 "On" ;
VAL_ 1345 CF_Gway_DriveTypeOption 0 "LHD" 1 "RHD" ;
VAL_ 1345 CF_Gway_StarterRlyState 0 "Starter Relay Output Off" 1 "Starter Relay Output On" ;
VAL_ 1345 CF_Gway_PassiveAccessLock 0 "None" 1 "Lock" 2 "PassiveTrunkLock" ;
VAL_ 1345 CF_Gway_RearFogAct 0 "Off" 1 "On" ;
VAL_ 1345 CF_Gway_PassiveAccessUnlock 0 "None" 1 "UnLock" 2 "Unlock only DRV Door" 3 "PIC_Key_Reminder" ;
VAL_ 1345 CF_Gway_PassingSW 0 "SW Off" 1 "SW On" ;
VAL_ 1345 CF_Gway_HBAControlMode 0 "HLamp High Control Mode by BCM" 1 "HLamp High Control Mode by HBA" ;
VAL_ 1345 CF_Gway_HLpHighSw 0 "Off" 1 "On" ;
VAL_ 1345 CF_Gway_InhibitRMT 0 "Gear_R Switch Off" 1 "Gear_R Switch On" 3 "B-CAN Time-out" ;
VAL_ 1345 CF_Gway_Ign1 0 "IGN1 Off" 1 "IGN1 On" ;
VAL_ 1345 CF_Gway_Ign2 0 "IGN2 Off" 1 "IGN2 On" ;
VAL_ 1345 CF_Gway_ParkBrakeSw 0 "Off" 1 "On" 3 "B-CAN Time-out" ;
VAL_ 1345 CF_Gway_TurnSigRh 0 "Off" 1 "On" 3 "B-CAN Time-out" ;
VAL_ 1405 Msg_Group_Num4 0 "Cyclic count every 1 frame" 1 "Cyclic count every 1 frame" 2 "Cyclic count every 1 frame" 3 "Cyclic count every 1 frame" 4 "Cyclic count every 1 frame" 5 "Cyclic count every 1 frame" 6 "Time out" 7 "Invalid" ;
VAL_ 1404 Msg_Group_Num3 0 "Cyclic count every 1 frame" 1 "Cyclic count every 1 frame" 2 "Cyclic count every 1 frame" 3 "Cyclic count every 1 frame" 4 "Cyclic count every 1 frame" 5 "Cyclic count every 1 frame" 6 "Time out" 7 "Invalid" ;
VAL_ 1407 CF_OBC_CONTRAB 0 "OFF" 1 "ON" ;
VAL_ 1407 CF_OBC_PD_Stat 0 "AC Charging Plug OFF" 1 "AC Charging Plug Switch(S3) Open" 2 "PD Normal Status" 3 "PD Circuit Fault Status" ;
VAL_ 1407 CF_OBC_Chg_Finished 0 "Not Finish" 1 "Finished" ;
VAL_ 1407 CF_OBC_EVSE_RDY_STATE 0 "Not Wake up" 1 "Wake up" ;
VAL_ 1407 CF_OBC_WRN 0 "No Warning" 1 "Warning" ;
VAL_ 1407 CF_OBC_FLT 0 "Initial value(Normal)" 1 "OBC Fault Status" ;
VAL_ 1407 CF_OBC_RDY 0 "Not Wake up" 1 "Wake up" ;
VAL_ 1407 CF_OBC_AC_DETECT_FLAG 0 "AC non detect" 1 "AC detect" ;
VAL_ 1407 CF_OBC_IG3_DRV_STATE 0 "Chargeing/IG3 OFF" 1 "Chargeing/IG3 ON" ;
VAL_ 1407 CF_OBC_AC_CONNECT 0 "AC Plug Disconnected" 1 "AC Plug Connected" ;
VAL_ 1407 CF_OBC_S2_SW_ON_FLAG 0 "S2 Switch Off" 1 "S2 Switch On" ;
VAL_ 1407 CF_OBC_MainRlyOn_Req 0 "off" 1 "on" ;
VAL_ 1407 CF_OBC_OBCRlyOn_Req 0 "Off" 1 "On" ;
VAL_ 1407 CF_OBC_MILReq 0 "off" 1 "on" ;
VAL_ 1407 CF_OBC_VCRM_Req 0 "No request" 1 "Ser./MIL Lamp" 2 "Warning" 3 "reserved" ;
VAL_ 1407 CF_OBC_RAD_Fan_Req 0 "FAN OFF" 1 "FAN LOW" 2 "FAN HIGH" ;
VAL_ 1407 CF_OBC_SERVICE_LAMP_Req 0 "OFF" 1 "ON" ;
VAL_ 1407 CF_OBC_HvIntlockReq 0 "OFF" 1 "ON" ;
VAL_ 1407 CF_EVSE_FAULT_FLAG 0 "Normal" 1 "Fault" ;
VAL_ 1407 CF_OBC_DCChargingStat 0 "Initial value" 1 "DC Chargin Staus" ;
VAL_ 1407 CF_OBC_ACChargingStat 0 "Not Determined" 1 "AC Charging" ;
VAL_ 1407 CF_OBC_ImmeChgSwState 0 "Switch off" 1 "Switch on" ;
VAL_ 1406 Msg_Group_Num5 0 "Cyclic count every 1 frame" 1 "Cyclic count every 1 frame" 2 "Cyclic count every 1 frame" 3 "Cyclic count every 1 frame" 4 "Cyclic count every 1 frame" 5 "Cyclic count every 1 frame" 6 "Time out" 7 "Invalid" ;
VAL_ 1406 FrontPos_Info_Update 0 "No update" 1 "Update" 2 "Reserved" 3 "Invalid" ;
VAL_ 1133 CF_Ctm_TrailerAct 0 "Not connected" 1 "Connected" ;
VAL_ 1133 CF_Ctm_RearfogAct 0 "Off" 1 "On" ;
VAL_ 1401 CF_Vcu_SchedChgMode 0 "Manual Chg" 1 "Undefined" 2 "SchedChg_PeakTimeUse" 3 "SchedChg_PeakTimeOnly" ;
VAL_ 1401 CF_Vcu_RestModeRValueSet 0 "Disable" 1 "RestMode Off" 2 "RestMode On" 3 "Invalid" ;
VAL_ 1401 CF_Vcu_RestModeWarn 0 "Default" 1 "Warn" 2 "Fail" ;
VAL_ 1401 CF_Vcu_RestModeVehCond 0 "Disable" 1 "Enable" ;
VAL_ 1401 CF_Vcu_EpbRequest 0 "Default" 1 "EPB Request" ;
VAL_ 1401 CF_Vcu_GpsSched_State 0 "Off" 1 "On&(¼³Á¤À§Ä¡ÀÌÅ»)" 2 "On&(¼³Á¤À§Ä¡ÁøÀÔ)" 3 "Invalid" ;
VAL_ 1401 CF_Vcu_GpsSched_ChgAir 0 "Not Use" 1 "Use" ;
VAL_ 1401 CF_Vcu_GpsSchedUpdateRq 0 "None" 1 "Request" ;
VAL_ 1401 CF_Vcu_MainBattType 0 "Low-cost type" 1 "Standard type" ;
VAL_ 1401 CF_Vcu_MainBattTypeLrnSts 0 "Unlerarnt" 1 "Learnt" ;
VAL_ 1401 CF_Vcu_RegenLevel_Eco 0 "Level1" 1 "Level2" 2 "Level3" 3 "Invaild" ;
VAL_ 1401 CF_Vcu_RegenLevel_Normal 0 "Level1" 1 "Level2" 2 "Level3" 3 "Invaild" ;
VAL_ 1401 CF_Vcu_RegenLevel_Sport 0 "Level1" 1 "Level2" 2 "Level3" 3 "Invaild" ;
VAL_ 1401 CF_Vcu_SmartRegen_RValueSet 0 "Default(USM ¹Ì±¸¼º)" 1 "Disabled (Off)" 2 "Enabled (On)" 3 "Invalid(USM ºñÈ°¼º)" ;
VAL_ 1401 CF_Vcu_SmartRegen_Disp 0 "Smart Regeneration Display inactivated (Display Off)" 1 "Smart Regeneration Display activated (Display On)" ;
VAL_ 1401 CF_Vcu_SmartRegen_Step 0 "Smart Regeneration front vehicle recognition (step1)" 1 "Smart Regeneration front vehicle non-recognition(step2)" ;
VAL_ 1401 CF_Vcu_SmartRegen_WarnMsg 0 "None" 1 "Smart Regeneration System warning" 2 "Smart Regeneration System temporary unavailable" 3 "Reserved" ;
VAL_ 1401 CF_Vcu_DriveMode 0 "Eco mode" 1 "Normal mode" 2 "Sport mode" 3 "Eco+ mode" 4 "Rest mode" 5 "Reserved" 6 "Reserved" 7 "Invalid" ;
VAL_ 1401 CF_Vcu_SpdLmt 0 "None" 1 "Limited" ;
VAL_ 512 CF_Vcu_ChgStat 1 "None" 1 "Normal" 2 "Reservation" 3 "Fault" 4 "AUX" ;
VAL_ 512 CF_Vcu_GarSelDisp 0 "P" 1 "B" 2 "Not used" 3 "Not used" 4 "Not used" 5 "D" 6 "N" 7 "R" 8 "Not used" 9 "Not Display at Cluster" 10 "reserved" 11 "reserved" 12 "reserved" 13 "reserved" 14 "Intermediate Position" 15 "Fault" ;
VAL_ 512 CF_Vcu_ChargeCycle 0 "None" 1 "Charge Cycle" ;
VAL_ 512 CF_Vcu_IGONStatus 0 "IG OFF" 1 "IGON_RDY" 2 "IGON_WAIT" 3 "IGON_RETRY" 4 "IGON_RUN_NORMAL" 5 "IGON_RUN_LIMPHOME" 6 "BATTERY PLUG_IN" 7 "BATTERY CHARGING" 8 "MAIN RLY OFF SEQUENCE" 9 "MAIN RLY OFF REQUEST" 10 "EV RDY FAIL" 11 "IG1 BREAK" ;
VAL_ 512 CF_Vcu_AvnDteCalc 0 "Display DTE value" 1 "Display 'Recalculating'" ;
VAL_ 512 CF_Vcu_EstApsSel 0 "VCU Real APS use" 1 "VCU Estimated APS use" ;
VAL_ 512 CF_Vcu_Veh_DC 0 "No driving cycle active" 1 "Driving cycle active" ;
VAL_ 512 CF_Vcu_WarmupCyc 0 "None" 1 "Warm-up Cycle Completed" ;
VAL_ 512 CF_Vcu_Key_ST 0 "None" 1 "Start" ;
VAL_ 512 CF_Vcu_EvRdyClu 0 "Ready Lamp Off" 1 "Ready Lamp On" ;
VAL_ 512 CF_Vcu_Rdy 0 "None" 1 "VCU Control Board Ready" ;
VAL_ 512 CF_Vcu_EvRdy 0 "None" 1 "EV Drivable" ;
VAL_ 512 CF_Vcu_RelayOffReq 0 "None" 1 "Relay Cut Off" ;
VAL_ 512 CF_Vcu_EcoMdOff 0 "Normal" 1 "Eco Off Mode" ;
VAL_ 513 CF_Vcu_RegenEna 0 "None" 1 "Regen Brake Possible" ;
VAL_ 513 CF_Vcu_TqRedStat 0 "None" 1 "Torque Reduction State" ;
VAL_ 513 CF_Vcu_TqIncStat 0 "None" 1 "Torque Increase Stae" ;
VAL_ 513 CF_Vcu_ServiceMod 0 "Normal mode" 1 "2WD Test mode" ;
VAL_ 513 CF_Vcu_SccEna 0 "SCC Impossible" 1 "SCC Possible" ;
VAL_ 513 CF_Vcu_Ovrride 0 "Override clear" 1 "Override set" ;
VAL_ 1400 CF_Clu_LowfuelWarn 0 "Low fuel Warning is off" 1 "Low fuel Warning is on" 2 "Not used" 3 "Invalid" ;
VAL_ 1400 CF_Ahb_Def 0 "AHB is normal mode" 1 "AHB is degraded mode" 2 "AHB is defective mode" 3 "Reserved" ;
VAL_ 1400 CF_LKA_SysState 0 "System OFF" 1 "Low Vehicle Speed" 2 "System Unavailable" 3 "MDPS Control_Full Lane Recognized" 4 "Full Lane Recognized" 5 "Left Line Recognized" 6 "Right Line Recognized" 7 "MDPS Control_Left Line Recognized" 8 "MDPS Control_Right Line Recognized" 14 "System Not Calibrated" 15 "System Failure" ;
VAL_ 1400 CF_Mdps_WLmp 0 "MDPS Malfunction Warning lamp OFF" 1 "MDPS Malfunciton Warning lamp BLANKING(2Hz)" 2 "MDPS Malfunction Warning lamp ON" 3 "MDPS Malfunction Warning lamp BLANKING(1Hz)" ;
VAL_ 1400 SCCFailInfo 0 "System without error" 1 "Performance degredation" 2 "System temporairy unavailable" 3 "SCC Service Required" ;
VAL_ 1400 SCCMode 0 "Off" 1 "Engaged" 2 "Override" 3 "Shutoff" ;
VAL_ 1400 CF_Clu_ActiveEcoSW 0 "Off" 1 "On" ;
VAL_ 1400 POS_FL_W_LAMP 0 "FL POSITION Warning lamp OFF" 1 "FL POSITION Warning lamp ON" ;
VAL_ 1400 POS_FR_W_LAMP 0 "FR POSITION Warning lamp OFF" 1 "FR POSITION Warning lamp ON" ;
VAL_ 1400 POS_RL_W_LAMP 0 "RL POSITION Warning lamp OFF" 1 "RL POSITION Warning lamp ON" ;
VAL_ 1400 POS_RR_W_LAMP 0 "RR POSITION Warning lamp OFF" 1 "RR POSITION Warning lamp ON" ;
VAL_ 1400 TPMS_W_LAMP 0 "TPMS Malfunction Warning lamp OFF" 1 "TPMS Malfunction Warning lamp ON" 2 "TPMS Malfunction Warning lamp BLINKING(2Hz)" 3 "Reserved" ;
VAL_ 1400 TREAD_W_LAMP 0 "TREAD Warning lamp OFF" 1 "TREAD Warning lamp ON" 2 "TREAD Warning lamp BLINKING(2Hz)" 3 "Reserved" ;
VAL_ 1400 CF_Clu_SmartRegen_NValueSet 0 "Default(USM ¹Ì±¸¼º)" 1 "Disabled (Off)" 2 "Enabled (On)" 3 "Invalid(USM ºñÈ°¼º)" ;
VAL_ 1400 CF_Clu_NCC_CameraNValueSet 0 "Not Applied" 1 "Function Off" 2 "Function On - Manual Resume" 3 "Function On - Automatic Resume" 4 "Reserved" 5 "Reserved" 6 "Reserved" 7 "Invalid" ;
VAL_ 1400 CF_DAW_Warn 0 "No Warning" 1 "Rest Recommend Warning" 2 "Reserved" 3 "Reserved" ;
VAL_ 1400 CF_Clu_DAWLastBreakTime 0 "Value x 30min (0~6.5hr)" 1 "Value x 30min (0~6.5hr)" 2 "Value x 30min (0~6.5hr)" 3 "Value x 30min (0~6.5hr)" 4 "Value x 30min (0~6.5hr)" 5 "Value x 30min (0~6.5hr)" 6 "Value x 30min (0~6.5hr)" 7 "Value x 30min (0~6.5hr)" 8 "Value x 30min (0~6.5hr)" 9 "Value x 30min (0~6.5hr)" 10 "Value x 30min (0~6.5hr)" 11 "Value x 30min (0~6.5hr)" 12 "Value x 30min (0~6.5hr)" 13 "Value x 30min (0~6.5hr)" 14 "7hr or more" 15 "Invalid" ;
VAL_ 1400 CF_Clu_RefDetMod 0 "Non refuel detected" 1 "Refuel detected" ;
VAL_ 1400 CF_Clu_DriveModeSW 0 "Off" 1 "On" ;
VAL_ 514 CF_Vcu_SldAct 0 "Speed Limiter Lamp Off" 1 "Speed Limiter Lamp On" ;
VAL_ 514 CF_Vcu_MotPwrEna 0 "None" 1 "Allow Motor System to Control" ;
VAL_ 514 CF_Vcu_Vcrm_Req 0 "wait (not request logging)" 1 "Service / MIL lamp on (request logging)" 2 "Warning, abnormal IG off (request logging)" 3 "reserved" ;
VAL_ 514 CF_Vcu_Lamp_Req 0 "Lamp Not Request" 1 "Lamp Request" ;
VAL_ 514 CF_Vcu_MCUAntiJerkInh 0 "Anti-jerk not inhibit" 1 "Anti-jerk inhibit" ;
VAL_ 514 CF_Vcu_PddlSftStep 0 "None" 1 "1st" 2 "2nd" 3 "3rd" 4 "4th" 5 "5th" 6 "6th" 7 "reserved" 8 "reserved" 9 "reserved" 10 "reserved" 11 "reserved" 12 "reserved" 13 "reserved" 14 "reserved" 15 "Fault" ;
VAL_ 514 CF_Vcu_LowSocAlert 0 "No Alert" 1 "Low SOC Alert 1" 2 "Low SOC Alert 2" 3 "Low SOC Alert 3" 4 "Reserved" 5 "Reserved" 6 "Reserved" 7 "SOC Unavailable Alert" ;
VAL_ 1403 CF_Vcu_CharInh 0 "None" 1 "Set" ;
VAL_ 1403 CF_Vcu_CharStopOpt 0 "Time based" 1 "SOC based" 2 "Power based" 3 "None" ;
VAL_ 1403 CF_Vcu_CharStopData 0 "40~100[%], 0~60[KWh]" 1 "40~100[%], 0~60[KWh]" 2 "40~100[%], 0~60[KWh]" 3 "40~100[%], 0~60[KWh]" 4 "40~100[%], 0~60[KWh]" 5 "40~100[%], 0~60[KWh]" 6 "40~100[%], 0~60[KWh]" 7 "40~100[%], 0~60[KWh]" 8 "40~100[%], 0~60[KWh]" 9 "40~100[%], 0~60[KWh]" 10 "40~100[%], 0~60[KWh]" 11 "40~100[%], 0~60[KWh]" 12 "40~100[%], 0~60[KWh]" 13 "40~100[%], 0~60[KWh]" 14 "40~100[%], 0~60[KWh]" 15 "40~100[%], 0~60[KWh]" 16 "40~100[%], 0~60[KWh]" 17 "40~100[%], 0~60[KWh]" 18 "40~100[%], 0~60[KWh]" 19 "40~100[%], 0~60[KWh]" 20 "40~100[%], 0~60[KWh]" 21 "40~100[%], 0~60[KWh]" 22 "40~100[%], 0~60[KWh]" 23 "40~100[%], 0~60[KWh]" 24 "40~100[%], 0~60[KWh]" 25 "40~100[%], 0~60[KWh]" 26 "40~100[%], 0~60[KWh]" 27 "40~100[%], 0~60[KWh]" 28 "40~100[%], 0~60[KWh]" 29 "40~100[%], 0~60[KWh]" 30 "40~100[%], 0~60[KWh]" 31 "40~100[%], 0~60[KWh]" 32 "40~100[%], 0~60[KWh]" 33 "40~100[%], 0~60[KWh]" 34 "40~100[%], 0~60[KWh]" 35 "40~100[%], 0~60[KWh]" 36 "40~100[%], 0~60[KWh]" 37 "40~100[%], 0~60[KWh]" 38 "40~100[%], 0~60[KWh]" 39 "40~100[%], 0~60[KWh]" 40 "40~100[%], 0~60[KWh]" 41 "40~100[%], 0~60[KWh]" 42 "40~100[%], 0~60[KWh]" 43 "40~100[%], 0~60[KWh]" 44 "40~100[%], 0~60[KWh]" 45 "40~100[%], 0~60[KWh]" 46 "40~100[%], 0~60[KWh]" 47 "40~100[%], 0~60[KWh]" 48 "40~100[%], 0~60[KWh]" 49 "40~100[%], 0~60[KWh]" 50 "40~100[%], 0~60[KWh]" 51 "40~100[%], 0~60[KWh]" 52 "40~100[%], 0~60[KWh]" 53 "40~100[%], 0~60[KWh]" 54 "40~100[%], 0~60[KWh]" 55 "40~100[%], 0~60[KWh]" 56 "40~100[%], 0~60[KWh]" 57 "40~100[%], 0~60[KWh]" 58 "40~100[%], 0~60[KWh]" 59 "40~100[%], 0~60[KWh]" 60 "40~100[%], 0~60[KWh]" 61 "Reserved" 62 "Reserved" 63 "Reserved" ;
VAL_ 1403 CF_Vcu_ClimateOperPerm 0 "Not permiited" 1 "Permitted" ;
VAL_ 1403 CF_Vcu_Aircon_Finish 0 "None" 1 "Set" ;
VAL_ 1403 CF_Vcu_AVN_Wakeup 0 "None" 1 "Wake up" ;
VAL_ 1403 CF_Vcu_IG3RlyMd 0 "None" 1 "Monitoring mode (by AVN)" 2 "Normal charge mode (by OBC)" 3 "Prog/Imme charge start mode (by VCU/AVN)" 4 "Prog FATC mode (by VCU)" 5 "Imme FATC mode during Prog/imme charge mode (by VCU/AVN)" 6 "Prog/Imme charge mode during imme FATC mode (by VCU/AVN)" 7 "Imme FATC mode during nor charge (by AVN/OBC)" 8 "Imme FATC mode (by AVN)" 9 "Aux battery charge mode (by VCU)" 10 "Abnormal stop mode during Prog/Imme charge(by VCU)" 11 "Reserved" 12 "Reserved" 13 "Reserved" 14 "Reserved" 15 "Reserved" ;
VAL_ 1403 CF_Vcu_FailComfirmed 0 "Not confirmed Prog/imme charge failure report" 1 "Confirmed Prog/imme charge failure report" ;
VAL_ 1403 CF_Vcu_NoramlAriconCtr 0 "Normal" 1 "Abnormal stop by FATC" 2 "Abnormal stop by HCU" 3 "Abnormal stop by Others" ;
VAL_ 1403 CF_Vcu_ProgCharInfo 0 "Reservation not set" 1 "Reservation set" ;
VAL_ 1403 CF_Vuc_ProgCharWaitForCharInd 0 "None" 1 "Set" ;
VAL_ 1403 CF_Vcu_CharCancel 0 "None" 1 "Charge cancel" ;
VAL_ 1403 CF_Vcu_AirconCtr 0 "Deativatie remote air conditioner control" 1 "Activate remote air condtioner control" ;
VAL_ 1403 CF_Vcu_TempUnit4FATC 0 "Centigrade mode" 1 "Fahrenheit mode" ;
VAL_ 1403 CF_Vcu_MainRelayOnReq 0 "None" 1 "Main relay on request" ;
VAL_ 1403 CF_Vcu_IG3Only 0 "None" 1 "IG3 only" ;
VAL_ 1403 CF_Vcu_ProgCharStop 0 "None" 1 "Programmable Charging Stop request" ;
VAL_ 1403 CF_Vcu_ProgAirConInfo 0 "Reservation not set" 1 "Reservation set" ;
VAL_ 1403 CF_Vcu_SbwWarnMsg 0 "Off" 1 "Warning 1 - SCU/Parking system failure" 2 "Warning 2 - Unavailable to shift gear" 3 "Warning 3 - Brake on for gear shift" 4 "Warning 4 - Unavailable to park" 5 "Warning 5 - Auto-parked" 6 "Warning 6 - Unavailable to release park" 7 "Warning 7 - Same Button Re-entered" ;
VAL_ 1403 CF_Vcu_SbwWarnSnd 0 "Warning sound off" 1 "Warning sound on" ;
VAL_ 1403 CF_Vcu_Invalid 0 "none" 1 "Invalid" ;
VAL_ 1402 CF_Vcu_DepartSet1_Mon 0 "None" 1 "Set" ;
VAL_ 1402 CF_Vcu_DepartSet1_Tue 0 "None" 1 "Set" ;
VAL_ 1402 CF_Vcu_DepartSet1_Wed 0 "None" 1 "Set" ;
VAL_ 1402 CF_Vcu_DepartSet1_Thu 0 "None" 1 "Set" ;
VAL_ 1402 CF_Vcu_DepartSet1_Fri 0 "None" 1 "Set" ;
VAL_ 1402 CF_Vcu_DepartSet1_Sat 0 "None" 1 "Set" ;
VAL_ 1402 CF_Vcu_DepartSet1_Sun 0 "None" 1 "Set" ;
VAL_ 1402 CF_Vcu_DepartSet1_PreCondSet 0 "None" 1 "Set" ;
VAL_ 1402 CF_Vcu_DepartSet1_TempUnit 0 "Centigrade Mode" 1 "Fahrenheit Mode" ;
VAL_ 1402 CF_Vcu_DepartSet1_DefrostCtr 0 "Deactivate defrost mode" 1 "Activate defrost mode" ;
VAL_ 1402 CF_Vcu_DepartSet1_Enable 0 "None" 1 "Set" ;
VAL_ 1402 CF_Vcu_DepartSet2_Mon 0 "None" 1 "Set" ;
VAL_ 1402 CF_Vcu_DepartSet2_Tue 0 "None" 1 "Set" ;
VAL_ 1402 CF_Vcu_DepartSet2_Wed 0 "None" 1 "Set" ;
VAL_ 1402 CF_Vcu_DepartSet2_Thu 0 "None" 1 "Set" ;
VAL_ 1402 CF_Vcu_DepartSet2_Fri 0 "None" 1 "Set" ;
VAL_ 1402 CF_Vcu_DepartSet2_Sat 0 "None" 1 "Set" ;
VAL_ 1402 CF_Vcu_DepartSet2_Sun 0 "None" 1 "Set" ;
VAL_ 1402 CF_Vcu_DepartSet2_PreCondSet 0 "None" 1 "Set" ;
VAL_ 1402 CF_Vcu_DepartSet2_TempUnit 0 "Centigrade Mode" 1 "Fahrenheit Mode" ;
VAL_ 1402 CF_Vcu_DepartSet2_DefrostCtr 0 "Deactivate defrost mode" 1 "Activate defrost mode" ;
VAL_ 1402 CF_Vcu_DepartSet2_Enable 0 "None" 1 "Set" ;
VAL_ 1402 CF_VCU_IG3DrvSts 0 "Off" 1 "On" ;
VAL_ 1402 CF_VCU_AuxBattChgUsmSts 0 "Default (USM ºñÈ°¼º)" 1 "Disable (Off)" 2 "Enable (On)" 3 "Invalid (USM ºñÈ°¼º)" ;
VAL_ 1399 Msg_Group_Num2 0 "Cyclic count every 1 frame" 1 "Cyclic count every 1 frame" 2 "Cyclic count every 1 frame" 3 "Cyclic count every 1 frame" 4 "Cyclic count every 1 frame" 5 "Cyclic count every 1 frame" 6 "Time out" 7 "Invalid" ;
VAL_ 1399 Sect_NextWarn_Info 0 "Default" 1 "Enforcement section" 2 "No enforcement section" 3 "Reserved" 4 "Reserved" 5 "Reserved" 6 "Reserved" 7 "Invalid" ;
VAL_ 1399 NextWarn_Dist 0 "0x000~0x33E:Distance" 830 "0x000~0x33E:Distance" 831 "Invalid" ;
VAL_ 1399 NextWarn_Type 0 "Default" 1 "Fixed Type Speed (Include Bus Lane & Speed)" 2 "Moving Type Speed" 3 "Signal&Speed" 4 "Fixed Moving Type Speed" 5 "Etc Cam" 6 "Reserved" 7 "Reserved" 8 "Reserved" 9 "Reserved" 10 "Reserved" 11 "Reserved" 12 "Reserved" 13 "Reserved" 14 "Reserved" 15 "Invalid" ;
VAL_ 1399 Sect_NextWarn_AvgSpd 0 "Default" 1 "0x1~0xFE:Speed (Km/h)" 254 "0x1~0xFE:Speed (Km/h)" 255 "Invalid" ;
VAL_ 1399 Sect_NextWarn_Dist 0 "0x0000~0xFFFE:Distance" 65534 "0x0000~0xFFFE:Distance" 65535 "Invalid" ;
VAL_ 1398 Msg_Group_Num1 0 "Cyclic count every 1 frame" 1 "Cyclic count every 1 frame" 2 "Cyclic count every 1 frame" 3 "Cyclic count every 1 frame" 4 "Cyclic count every 1 frame" 5 "Cyclic count every 1 frame" 6 "Time out" 7 "Invalid" ;
VAL_ 1398 SetDest_Status 0 "No route setting" 1 "Route setting" 2 "Reserved" 3 "Invalid" ;
VAL_ 1398 OffRoute_Status 0 "On route" 1 "Off route status" 2 "Off route status" 3 "Off route status" 4 "Reserved" 5 "Reserved" 6 "Reserved" 7 "Invalid" ;
VAL_ 1398 NextTurn_Type1 0 "Default" 1 "Straight" 2 "Right" 3 "Left" 4 "Right side of Y branch" 5 "Left side of Y branch" 6 "U-turn" 7 "Overpass entry" 8 "Overpass" ;
VAL_ 1398 NaviValidity 0 "Normal" 1 "Navi error" 2 "No navi" 3 "Reserved" 4 "Reserved" 5 "Reserved" 6 "Reserved" 7 "Invalid" ;
VAL_ 1398 NextTurn_Type2 0 "Default" 1 "Straight" 2 "Right" 3 "Left" 4 "Right side of Y branch" 5 "Left side of Y branch" 6 "U-turn" 7 "Overpass entry" 8 "Overpass" ;
VAL_ 1398 NextTurn_Dist1 0 "0x000~0xFFE:Distance" 4094 "0x000~0xFFE:Distance" 4095 "Invalid" ;
VAL_ 1398 NextTurn_Dist2 0 "0x000~0xFFE:Distance" 4094 "0x000~0xFFE:Distance" 4095 "Invalid" ;
VAL_ 1398 CurLink_Class 0 "Default" 1 "Main line (Non-separation)" 2 "Main line (Seperation)" 3 "JC" 4 "Crossroad" 5 "IC" 6 "SA (Service area)" 7 "Link in the rotary" 8 "Etc." 9 "Reserved" 10 "Reserved" 11 "Reserved" 12 "Reserved" 13 "Reserved" 14 "Reserved" 15 "Invalid" ;
VAL_ 1398 CurRoad_Class 0 "Default" 1 "Highway" 2 "City Highway" 3 "National Road" 4 "National locality road" 5 "Locality road" 6 "General road" 7 "Narrow road" 8 "Ferry" 9 "Reserved" 10 "Reserved" 11 "Reserved" 12 "Reserved" 13 "Reserved" 14 "Reserved" 15 "Invalid" ;
VAL_ 1398 CurLink_CntLane 0 "Default" 1 "Lane counter" 2 "Lane counter" 3 "Lane counter" 4 "Lane counter" 5 "Lane counter" 6 "Lane counter" 7 "Lane counter" 8 "Lane counter" 9 "Lane counter" 10 "Lane counter" 11 "Lane counter" 12 "Lane counter" 13 "Lane counter" 14 "Lane counter" 15 "Invalid" ;
VAL_ 1122 ObjValid 0 "no in-path object detected" 1 "in-path object detected" ;
VAL_ 1122 SCC_ObjStatus 0 "No SCC object detected" 1 "SCC Object detected" 2 "Reserved" 3 "SCC Pre-Safe I/F inactive (No VI platform detected)" ;
VAL_ 1122 CF_VSM_Warn 0 "No warning" 1 "Warning level 1" 2 "Warning level 2" 3 "Warning level 3" ;
VAL_ 1122 CF_Esc_BrakeAct 0 "ECU does not support this function." 1 "Brake switch is not pressed (OFF)" 2 "Brake switch is pressed (ON)" 3 "Brake switch failure" ;
VAL_ 1122 CF_Clu_PaddDownSwState 0 "Idle position" 1 "On" ;
VAL_ 1122 CF_Clu_PaddUpSwState 0 "Idle position" 1 "On" ;
VAL_ 1122 CF_Clu_VanzDecimal 0 "0" 1 "0.125" 2 "0.250" 3 "0.375" ;
VAL_ 1122 CF_Clu_RestModeNValueSet 0 "Default" 1 "Disabled (Off)" 2 "Enabled (On)" 3 "Invalid" ;
VAL_ 1122 ISLA_SpdwOffst 0 "No Recognition" 1 "0x1~0xFC:1~252 kph or mph" 252 "0x1~0xFC:1~252 kph or mph" 253 "Unlimited Speed" 254 "Reserved" 255 "Invalid" ;
VAL_ 1122 ISLA_SwIgnoreReq 0 "Allow All Switch Inputs (default)" 1 "-(SET) Switch Input Ignore" 2 "+(SET) Switch Input Ignore" 3 "-(SET) & +(SET) Switch Inputs Ignore" ;
VAL_ 1122 ISLA_SpdChgReq 0 "Default" 1 "Speed Change Request" 2 "Reserved" 3 "Reserved" ;
VAL_ 1392 CF_Ewp_FltStatus 0 "Normal" 1 "Fault" ;
VAL_ 1392 CF_Ewp_ProtectMode 0 "Normal" 1 "EWP Protection Mode" ;
VAL_ 1388 CF_OLdc_Rdy 0 "Not Ready" 1 "Ready" ;
VAL_ 1388 CF_OLdc_Controllable 0 "Not Controllable" 1 "Controllable" ;
VAL_ 1388 CF_OLdc_12VCharge 0 "PWM off" 1 "PWM on" ;
VAL_ 1388 CF_OLdc_Pd_Stat 0 "-" 1 "LDC Power Derating Status" ;
VAL_ 1388 CF_Ldc_TmpLmt 0 "Normal Status" 1 "Tmp Limit Status" ;
VAL_ 1388 CF_OLdc_Srvlamp_Rqst 0 "Normal status" 1 "Service lamp request" ;
VAL_ 1388 CF_OLdc_Flt 0 "Normal status" 1 "Fault status" ;
VAL_ 291 CF_Cms_MainRlyOnReq 0 "off" 1 "on" ;
VAL_ 291 CF_Cms_QcNRlyOnReq 0 "default" 1 "on" ;
VAL_ 291 CF_Cms_QcPRlyOnReq 0 "default" 1 "on" ;
VAL_ 291 CF_Cms_400VRlyOnReq 0 "default" 1 "on" ;
VAL_ 291 CF_Cms_MainRlyOffReq 0 "default" 1 "on" ;
VAL_ 291 CF_Cms_InletFailStatus 0 "Normal" 1 "Fail" ;
VAL_ 291 CF_Cms_InletLockStatus 0 "Init/Fault" 1 "Lock" 2 "Unlock" 3 "Move" ;
VAL_ 291 CF_Cms_McuMultiChgStartReq 0 "default" 1 "on" ;
VAL_ 291 CF_Cms_McuPreChgStartReq 0 "default" 1 "on" ;
VAL_ 291 CF_Cms_InletAutoLockMode 0 "Default" 1 "Auto Mode" 2 "Lock Mode" 3 "Unlock Mode" 4 "reserved" 5 "reserved" 6 "reserved" 7 "Invalid" ;
VAL_ 291 CF_Cms_DChargeMode 0 "default" 1 "800V" 2 "400V" 3 "reserved" ;
VAL_ 291 CF_Cms_ObcChgStart 0 "default" 1 "on" ;
VAL_ 1148 CF_OBC_ChgStop_Alram 0 "Initial Value(Normal)" 1 "Check EVSE/Grid" 2 "Check Charge Cable Connection" 3 "Reserved" 4 "Reserved" 5 "Reserved" 6 "Reserved" 7 "Reserved" ;
VAL_ 1148 CF_OBC_ChrgRdySta 0 "OFF" 1 "ON" ;
VAL_ 1148 CF_OBC_InletAutoLockMode 0 "Default" 1 "Auto Mode" 2 "Lock Mode" 3 "Unlcok Mode" 7 "Invalid" ;
VAL_ 1148 CF_OBC_PwmOnSta 0 "OFF" 1 "ON" ;
VAL_ 1148 CF_OBC_EVSE_CluInCurMode 0 "Default (Invalid)" 1 "Maximum" 2 "Decreasing" 3 "Minimum" ;
VAL_ 1148 CF_OBC_ICCB_CluInCurMode 0 "Default (Invalid)" 1 "Maximum" 2 "Decreasing" 3 "Minimum" ;
VAL_ 1148 CF_OBC_AcPwrSysTyp 0 "Initial" 1 "1-Phase" 2 "3-Phase" 3 "Not used" 4 "Not used" 5 "Not used" 6 "Not used" 7 "Error indicator" ;
VAL_ 1145 BS2_FSOC 0 "valid" 1 "invalid" ;
VAL_ 1145 BS2_FSOH 0 "valid" 1 "invalid" ;
VAL_ 1145 BS2_FSOF 0 "valid" 1 "invalid" ;
VAL_ 1145 BS2_FQSTAT 0 "valid" 1 "invalid" ;
VAL_ 1144 BS1_BSInvalidFlag 0 "Valid condition" 1 "Invalid condition" ;
VAL_ 1144 BS1_ErrorResp 0 "opeartion correctly" 1 "response error" ;
VAL_ 1383 CF_Tmu_Cur_Mon 0 "None" 1 "Set" ;
VAL_ 1383 CF_Tmu_Cur_Tue 0 "None" 1 "Set" ;
VAL_ 1383 CF_Tmu_Cur_Wed 0 "None" 1 "Set" ;
VAL_ 1383 CF_Tmu_Cur_Thu 0 "None" 1 "Set" ;
VAL_ 1383 CF_Tmu_Cur_Fri 0 "None" 1 "Set" ;
VAL_ 1383 CF_Tmu_Cur_Sat 0 "None" 1 "Set" ;
VAL_ 1383 CF_Tmu_Cur_Sun 0 "None" 1 "Set" ;
VAL_ 1383 CF_Tmu_Rdy 1 "Ready" ;
VAL_ 1377 CF_Tmu_RoadType6 0 "No Data" 1 "Highway" 2 "Urban Highway" 3 "Route" 4 "National Support Local Road" 5 "Local Road" 6 "City Street" 7 "New Road" 8 "Ferry" 9 "Reserved" 10 "Reserved" 11 "Reserved" 12 "Reserved" 13 "Reserved" 14 "Reserved" 15 "Invalid" ;
VAL_ 1377 CF_Tmu_RoadType7 0 "No Data" 1 "Highway" 2 "Urban Highway" 3 "Route" 4 "National Support Local Road" 5 "Local Road" 6 "City Street" 7 "New Road" 8 "Ferry" 9 "Reserved" 10 "Reserved" 11 "Reserved" 12 "Reserved" 13 "Reserved" 14 "Reserved" 15 "Invalid" ;
VAL_ 1377 CF_Tmu_RoadType8 0 "No Data" 1 "Highway" 2 "Urban Highway" 3 "Route" 4 "National Support Local Road" 5 "Local Road" 6 "City Street" 7 "New Road" 8 "Ferry" 9 "Reserved" 10 "Reserved" 11 "Reserved" 12 "Reserved" 13 "Reserved" 14 "Reserved" 15 "Invalid" ;
VAL_ 1377 CF_Tmu_RoadType9 0 "No Data" 1 "Highway" 2 "Urban Highway" 3 "Route" 4 "National Support Local Road" 5 "Local Road" 6 "City Street" 7 "New Road" 8 "Ferry" 9 "Reserved" 10 "Reserved" 11 "Reserved" 12 "Reserved" 13 "Reserved" 14 "Reserved" 15 "Invalid" ;
VAL_ 1377 CF_Tmu_RoadType10 0 "No Data" 1 "Highway" 2 "Urban Highway" 3 "Route" 4 "National Support Local Road" 5 "Local Road" 6 "City Street" 7 "New Road" 8 "Ferry" 9 "Reserved" 10 "Reserved" 11 "Reserved" 12 "Reserved" 13 "Reserved" 14 "Reserved" 15 "Invalid" ;
VAL_ 1137 CLU11_STS 0 "Normal status" 1 "Not Received" 2 "Reserved" 3 "Invalid" ;
VAL_ 1137 CLU12_STS 0 "Normal status" 1 "Not Received" 2 "Reserved" 3 "Invalid" ;
VAL_ 1137 CLU14_STS 0 "Normal status" 1 "Not Received" 2 "Reserved" 3 "Invalid" ;
VAL_ 1137 EPB11_STS 0 "Normal status" 1 "Not Received" 2 "Reserved" 3 "Invalid" ;
VAL_ 1137 SAS11_STS 0 "Normal status" 1 "Not Received" 2 "Reserved" 3 "Invalid" ;
VAL_ 1137 ESP11_STS 0 "Normal status" 1 "Not Received" 2 "Reserved" 3 "Invalid" ;
VAL_ 1137 AHB1_STS 0 "Normal status" 1 "Not Received" 2 "Reserved" 3 "Invalid" ;
VAL_ 1137 CLU13_STS 0 "Normal status" 1 "Not Received" 2 "Reserved" 3 "Invalid" ;
VAL_ 1378 HU_EV_WinterMode 0 "Winter mode Off" 1 "Winter mode On" 2 "Reserved" 3 "Invalid" ;
VAL_ 1378 HU_TgSoc_ScChg_Set 0 "0x0~0xC8:PHY = HEX * 0.5" 200 "0x0~0xC8:PHY = HEX * 0.5" 201 "Reserved" 202 "Reserved" 203 "Reserved" 204 "Reserved" 205 "Reserved" 206 "Reserved" 207 "Reserved" 208 "Reserved" 209 "Reserved" 210 "Reserved" 211 "Reserved" 212 "Reserved" 213 "Reserved" 214 "Reserved" 215 "Reserved" 216 "Reserved" 217 "Reserved" 218 "Reserved" 219 "Reserved" 220 "Reserved" 221 "Reserved" 222 "Reserved" 223 "Reserved" 224 "Reserved" 225 "Reserved" 226 "Reserved" 227 "Reserved" 228 "Reserved" 229 "Reserved" 230 "Reserved" 231 "Reserved" 232 "Reserved" 233 "Reserved" 234 "Reserved" 235 "Reserved" 236 "Reserved" 237 "Reserved" 238 "Reserved" 239 "Reserved" 240 "Reserved" 241 "Reserved" 242 "Reserved" 243 "Reserved" 244 "Reserved" 245 "Reserved" 246 "Reserved" 247 "Reserved" 248 "Reserved" 249 "Reserved" 250 "Reserved" 251 "Reserved" 252 "Reserved" 253 "Reserved" 254 "Reserved" 255 "Invalid" ;
VAL_ 1378 HU_TgSoc_QcChg_Set 0 "0x0~0xC8:PHY = HEX * 0.5" 200 "0x0~0xC8:PHY = HEX * 0.5" 201 "Reserved" 202 "Reserved" 203 "Reserved" 204 "Reserved" 205 "Reserved" 206 "Reserved" 207 "Reserved" 208 "Reserved" 209 "Reserved" 210 "Reserved" 211 "Reserved" 212 "Reserved" 213 "Reserved" 214 "Reserved" 215 "Reserved" 216 "Reserved" 217 "Reserved" 218 "Reserved" 219 "Reserved" 220 "Reserved" 221 "Reserved" 222 "Reserved" 223 "Reserved" 224 "Reserved" 225 "Reserved" 226 "Reserved" 227 "Reserved" 228 "Reserved" 229 "Reserved" 230 "Reserved" 231 "Reserved" 232 "Reserved" 233 "Reserved" 234 "Reserved" 235 "Reserved" 236 "Reserved" 237 "Reserved" 238 "Reserved" 239 "Reserved" 240 "Reserved" 241 "Reserved" 242 "Reserved" 243 "Reserved" 244 "Reserved" 245 "Reserved" 246 "Reserved" 247 "Reserved" 248 "Reserved" 249 "Reserved" 250 "Reserved" 251 "Reserved" 252 "Reserved" 253 "Reserved" 254 "Reserved" 255 "Invalid" ;
VAL_ 1378 HU_TgSoc_GPSChg_Set 0 "0x0~0xC8:PHY = HEX * 0.5" 200 "0x0~0xC8:PHY = HEX * 0.5" 201 "Reserved" 202 "Reserved" 203 "Reserved" 204 "Reserved" 205 "Reserved" 206 "Reserved" 207 "Reserved" 208 "Reserved" 209 "Reserved" 210 "Reserved" 211 "Reserved" 212 "Reserved" 213 "Reserved" 214 "Reserved" 215 "Reserved" 216 "Reserved" 217 "Reserved" 218 "Reserved" 219 "Reserved" 220 "Reserved" 221 "Reserved" 222 "Reserved" 223 "Reserved" 224 "Reserved" 225 "Reserved" 226 "Reserved" 227 "Reserved" 228 "Reserved" 229 "Reserved" 230 "Reserved" 231 "Reserved" 232 "Reserved" 233 "Reserved" 234 "Reserved" 235 "Reserved" 236 "Reserved" 237 "Reserved" 238 "Reserved" 239 "Reserved" 240 "Reserved" 241 "Reserved" 242 "Reserved" 243 "Reserved" 244 "Reserved" 245 "Reserved" 246 "Reserved" 247 "Reserved" 248 "Reserved" 249 "Reserved" 250 "Reserved" 251 "Reserved" 252 "Reserved" 253 "Reserved" 254 "Reserved" 255 "Invalid" ;
VAL_ 1032 CR_Cms_EVTransferType 0 "AC_single_phase_core" 1 "three_phase_core" 2 "DC_core" 3 "DC_extended" 4 "DC_combo_core" 5 "DC_dual" 6 "AC_core1p_DC_extended" 7 "AC_single_DC_core" 8 "AC_single_phase_three_phase_core_DC_extended" 9 "AC_core3p_DC_extended" ;
VAL_ 1307 CF_Clu_TirePressUnitNValueSet 0 "Default Value" 1 "psi" 2 "kpa" 3 "bar" 4 "Reserved" 5 "Reserved" 6 "Reserved" 7 "Invalid" ;
VAL_ 1307 CF_Clu_FuelGuideReset 0 "Default" 1 "Reset request" ;
VAL_ 1307 CF_Clu_ECoastingNvalueSet 0 "Default" 1 "Disable" 2 "Enable" 3 "Invalid" ;
VAL_ 1307 CF_Clu_USMReset 0 "Default" 1 "Reset" ;
VAL_ 1307 CF_Clu_ECoastWarnNValueSet 0 "Default" 1 "Disable" 2 "Enable" 3 "Invalid" ;
VAL_ 1307 CF_Clu_AuxBatChargeNValueSet 0 "Default" 1 "Disable" 2 "Enable" 3 "Invalid" ;
VAL_ 1307 CF_Clu_ECoastCtrlNValueSet 0 "Default" 1 "Long distance" 2 "Middle distance" 3 "Short distance" 4 "Reserved" 5 "Reserved" 6 "Reserved" 7 "Invalid" ;
VAL_ 339 TCS_REQ 0 "Passive" 1 "TCS/ESC control active" ;
VAL_ 339 MSR_C_REQ 0 "Passive or TCS function" 1 "MSR control active" ;
VAL_ 339 TCS_PAS 1 "TCS is disabled by user" ;
VAL_ 339 TCS_GSC 0 "passive (gear change allowed)" 1 "active (gear change not allowed)" ;
VAL_ 339 CF_Esc_LimoInfo 0 "Invalid" 1 "Invalid" 2 "Vehicle is not Limo" 3 "Vehicle is Limo" ;
VAL_ 339 ABS_DIAG 0 "ABS/TCS/ESC is not diagnostic mode" 1 "ABS/TCS/ESC is diagnostic mode" ;
VAL_ 339 ABS_DEF 0 "ABS is not defective" 1 "ABS is defective" ;
VAL_ 339 TCS_DEF 1 "TCS is defective (failed)" ;
VAL_ 339 TCS_CTL 1 "TCS Active" ;
VAL_ 339 ABS_ACT 0 "ABS control inactive" 1 "ABS control active" ;
VAL_ 339 EBD_DEF 0 "EBD is not defective" 1 "EBD is defective" ;
VAL_ 339 ESP_PAS 1 "ESC disabled by user (SW off)" ;
VAL_ 339 ESP_DEF 1 "ESC is defective (failed)" ;
VAL_ 339 ESP_CTL 1 "ESC active" ;
VAL_ 339 TCS_MFRN 0 "Using both TQI_TCS and TQI_SLW_TCS" 1 "Using TQI_TCS only (Not using TQI_SLW_TCS)" ;
VAL_ 339 DBC_CTL 1 "DBC is Active" ;
VAL_ 339 DBC_PAS 1 "DBC is stand by (SW ON)" ;
VAL_ 339 DBC_DEF 1 "DBC is defective (failed)" ;
VAL_ 339 HAC_CTL 1 "HAC is Active" ;
VAL_ 339 HAC_PAS 1 "HAC is stand by (SW ON) If SW is applied" ;
VAL_ 339 HAC_DEF 1 "HAC is defective (failed)" ;
VAL_ 339 ESS_STAT 0 "ESS control ¡°inactive¡± (Normal condition)" 1 "ESS control ¡°active¡± (Emergency stop condition)" 2 "ESS system is defective" 3 "ESS extended function active (Hazard lamp blinking)" ;
VAL_ 339 CF_Esc_BrkCtl 0 "Brake control is not in activation" 1 "Brake control is in activation" ;
VAL_ 339 CF_Brk_AbsNReq 0 "Inactive" 1 "N Gear position Request Active" ;
VAL_ 339 BLA_CTL 0 "No request" 1 "Activate brake lights" 2 "Reserved" 3 "Reserved" ;
VAL_ 1029 CF_Cms_EvReady 0 "Not Ready" 1 "Ready" ;
VAL_ 1029 CF_Cms_ReadyToCharge 0 "Normal" 1 "Ready to Charge" ;
VAL_ 1029 CF_Cms_ChgComplete 0 "Normal" 1 "Charging Complete" ;
VAL_ 1029 CF_Cms_ChgFinished 0 "Normal" 1 "Charge finish" ;
VAL_ 1029 CF_Cms_PreparationStatusForPLC 0 "Normal" 1 "Ready for PLC" ;
VAL_ 1029 CF_Cms_ReadyForCurDem 0 "Normal" 1 "Ready for Current Demand" ;
VAL_ 1029 CF_Cms_RlyWeldDetectionReq 0 "False" 1 "True" ;
VAL_ 1029 CF_Cms_WeldDctFinish 0 "Normal" 1 "WeldDetection Finished" ;
VAL_ 1029 CF_Cms_SessionStopReq 0 "Normal" 1 "Session Stop" ;
